VERSION ""

NS_ :

BS_:

BU_: VMCU TECU OBDScanT2 IC3 EMS ECUspare2 ECUspare1 DACU CIOM BBM
VAL_TABLE_ ViSig_Debug_PVT_SCIM_RD_DAI2Faul 3 "Input signals invalid" 2 "Open circuit " 1 "Short to GND" 0 "Nomal" ;
VAL_TABLE_ ViSig_Debug_PVT_SCIM_RD_DAI1Faul 3 "Input signals invalid" 2 "Open circuit " 1 "Short to GND " 0 "Nomal" ;
VAL_TABLE_ Debug_PVT_SCIM_RD_VBAT_Fault 8 "Invalid[Error Value]" 7 "Voltage Too High" 6 "Voltage Too Low" 5 "Voltage out of range" 4 "Reserved" 3 "Reserved" 2 "Reserved" 1 "Reserved" 0 "Nomal" ;
VAL_TABLE_ Debug_PVT_SCIM_RD_12VLivingFault 8 "Invalid[Error Value]" 7 "Reserved" 6 "Reserved" 5 "Voltage out of range" 4 "Reserved" 3 "Reserved" 2 "Reserved" 1 "Reserved" 0 "Nomal" ;
VAL_TABLE_ SetActive 1 "Deactivate" 0 "Activate" ;
VAL_TABLE_ FaultMonitoring 7 "Voltage Too High" 6 "Voltage Too Low" 3 "Open Circuit" 2 "Short To Battery" 1 "Short To Ground" ;

BO_ 3221225472 VECTOR__INDEPENDENT_SIG_MSG: 0 Vector__XXX
 SG_ Debug_6_CIOM : 0|64@1+ (1,0) [0|0] "" Vector__XXX
 SG_ Debug_5_CIOM : 0|64@1+ (1,0) [0|0] "" Vector__XXX
 SG_ Debug_4_CIOM : 0|64@1+ (1,0) [0|0] "" Vector__XXX
 SG_ Debug_3_CIOM : 0|64@1+ (1,0) [0|0] "" Vector__XXX
 SG_ Debug_2_CIOM : 0|64@1+ (1,0) [0|0] "" Vector__XXX

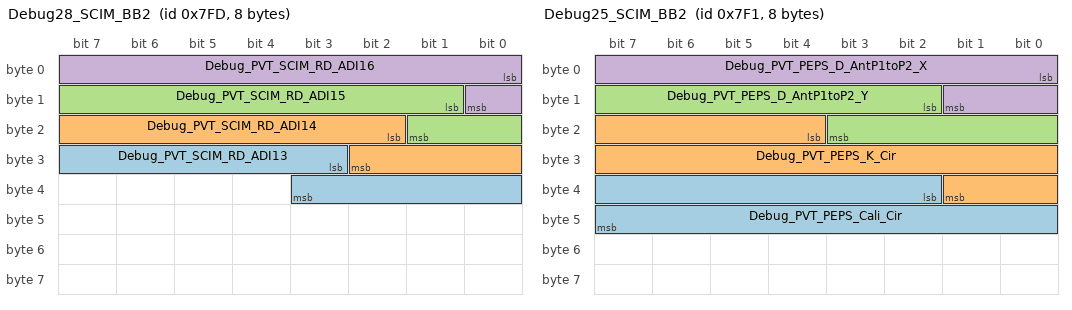
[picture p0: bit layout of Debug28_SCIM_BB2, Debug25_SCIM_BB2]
BO_ 2045 Debug28_SCIM_BB2: 8 CIOM
 SG_ Debug_PVT_SCIM_RD_ADI13 : 27|9@1+ (0.1,0) [0|51] "V" Vector__XXX
 SG_ Debug_PVT_SCIM_RD_ADI14 : 18|9@1+ (0.1,0) [0|51] "V" Vector__XXX
 SG_ Debug_PVT_SCIM_RD_ADI15 : 9|9@1+ (0.1,0) [0|51] "V" Vector__XXX
 SG_ Debug_PVT_SCIM_RD_ADI16 : 0|9@1+ (0.1,0) [0|51] "V" Vector__XXX

BO_ 2044 Debug27_SCIM_BB2: 8 CIOM
 SG_ Debug_PVT_SCIM_RD_DAI1Fault : 34|2@1+ (1,0) [0|3] ""  ECUspare1
 SG_ Debug_PVT_SCIM_RD_DAI2Fualt : 32|2@1+ (1,0) [0|3] ""  ECUspare1
 SG_ Debug_PVT_SCIM_RD_ADI16Fault : 30|2@1+ (1,0) [0|3] ""  ECUspare1
 SG_ Debug_PVT_SCIM_RD_ADI15Fault : 28|2@1+ (1,0) [0|3] ""  ECUspare1
 SG_ Debug_PVT_SCIM_RD_ADI14Fault : 26|2@1+ (1,0) [0|3] ""  ECUspare1
 SG_ Debug_PVT_SCIM_RD_ADI13Fault : 24|2@1+ (1,0) [0|3] ""  ECUspare1
 SG_ Debug_PVT_SCIM_RD_ADI12Fault : 22|2@1+ (1,0) [0|3] ""  ECUspare1
 SG_ Debug_PVT_SCIM_RD_ADI11Fault : 20|2@1+ (1,0) [0|3] ""  ECUspare1
 SG_ Debug_PVT_SCIM_RD_ADI10Fault : 18|2@1+ (1,0) [0|3] ""  ECUspare1
 SG_ Debug_PVT_SCIM_RD_ADI09Fault : 16|2@1+ (1,0) [0|3] ""  ECUspare1
 SG_ Debug_PVT_SCIM_RD_ADI08Fault : 14|2@1+ (1,0) [0|3] ""  ECUspare1
 SG_ Debug_PVT_SCIM_RD_ADI07Fault : 12|2@1+ (1,0) [0|3] ""  ECUspare1
 SG_ Debug_PVT_SCIM_RD_ADI06Fault : 10|2@1+ (1,0) [0|3] ""  ECUspare1
 SG_ Debug_PVT_SCIM_RD_ADI05Fault : 8|2@1+ (1,0) [0|3] ""  ECUspare1
 SG_ Debug_PVT_SCIM_RD_ADI04Fault : 6|2@1+ (1,0) [0|3] ""  ECUspare1
 SG_ Debug_PVT_SCIM_RD_ADI03Fault : 4|2@1+ (1,0) [0|3] ""  ECUspare1
 SG_ Debug_PVT_SCIM_RD_ADI02Fault : 2|2@1+ (1,0) [0|3] ""  ECUspare1
 SG_ Debug_PVT_SCIM_RD_ADI01Fault : 0|2@1+ (1,0) [0|3] ""  ECUspare1

BO_ 2034 Debug26_SCIM_BB2: 8 CIOM
 SG_ Debug_PVT_PEPS_AverRSSI2 : 24|8@1+ (1,0) [0|255] ""  ECUspare1
 SG_ Debug_PVT_PEPS_AverRSSI1 : 16|8@1+ (1,0) [0|255] ""  ECUspare1
 SG_ Debug_PVT_PEPS_DecRSSI : 0|16@1+ (1,0) [0|65535] ""  ECUspare1

BO_ 2033 Debug25_SCIM_BB2: 8 CIOM
 SG_ Debug_PVT_PEPS_Cali_Cir : 34|14@1- (1,0) [-8192|8191] ""  ECUspare1
 SG_ Debug_PVT_PEPS_K_Cir : 20|14@1- (1,0) [-8192|8191] ""  ECUspare1
 SG_ Debug_PVT_PEPS_D_AntP1toP2_Y : 10|10@1- (1,0) [-512|511] ""  ECUspare1
 SG_ Debug_PVT_PEPS_D_AntP1toP2_X : 0|10@1- (1,0) [-512|511] ""  ECUspare1

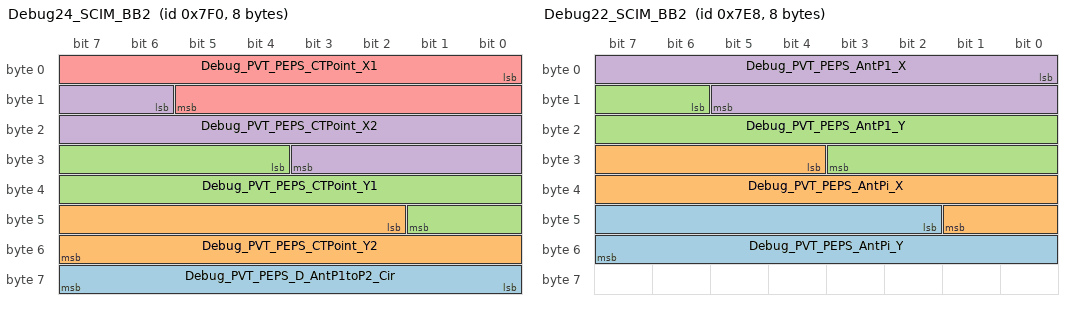
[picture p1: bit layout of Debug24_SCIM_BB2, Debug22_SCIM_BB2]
BO_ 2032 Debug24_SCIM_BB2: 8 CIOM
 SG_ Debug_PVT_PEPS_D_AntP1toP2_Cir : 56|8@1+ (1,0) [0|255] ""  ECUspare1
 SG_ Debug_PVT_PEPS_CTPoint_Y2 : 42|14@1- (1,0) [-8192|8191] ""  ECUspare1
 SG_ Debug_PVT_PEPS_CTPoint_Y1 : 28|14@1- (1,0) [-8192|8191] ""  ECUspare1
 SG_ Debug_PVT_PEPS_CTPoint_X2 : 14|14@1- (1,0) [-8192|8191] ""  ECUspare1
 SG_ Debug_PVT_PEPS_CTPoint_X1 : 0|14@1- (1,0) [-8192|8191] ""  ECUspare1

BO_ 2024 Debug22_SCIM_BB2: 8 CIOM
 SG_ Debug_PVT_PEPS_AntPi_Y : 42|14@1- (1,0) [-8192|8191] ""  ECUspare1
 SG_ Debug_PVT_PEPS_AntPi_X : 28|14@1- (1,0) [-8192|8191] ""  ECUspare1
 SG_ Debug_PVT_PEPS_AntP1_Y : 14|14@1- (1,0) [-8192|8191] ""  ECUspare1
 SG_ Debug_PVT_PEPS_AntP1_X : 0|14@1- (1,0) [-8192|8191] ""  ECUspare1

BO_ 2043 DebugCtrl11_SCIM_BB2: 8 Vector__XXX

BO_ 2042 DebugCtrl10_SCIM_BB2: 8 Vector__XXX

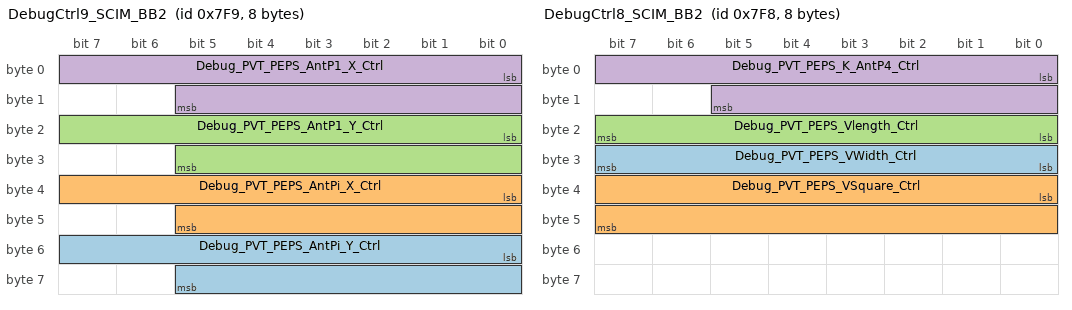
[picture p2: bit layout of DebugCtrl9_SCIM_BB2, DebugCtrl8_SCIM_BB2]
BO_ 2041 DebugCtrl9_SCIM_BB2: 8 ECUspare1
 SG_ Debug_PVT_PEPS_AntPi_Y_Ctrl : 48|14@1- (1,0) [-8192|8191] ""  CIOM
 SG_ Debug_PVT_PEPS_AntPi_X_Ctrl : 32|14@1- (1,0) [-8192|8191] ""  CIOM
 SG_ Debug_PVT_PEPS_AntP1_Y_Ctrl : 16|14@1- (1,0) [-8192|8191] ""  CIOM
 SG_ Debug_PVT_PEPS_AntP1_X_Ctrl : 0|14@1- (1,0) [-8192|8191] ""  CIOM

BO_ 2040 DebugCtrl8_SCIM_BB2: 8 ECUspare1
 SG_ Debug_PVT_PEPS_VWidth_Ctrl : 24|8@1+ (1,0) [0|255] ""  CIOM
 SG_ Debug_PVT_PEPS_VSquare_Ctrl : 32|16@1+ (1,0) [0|65535] ""  CIOM
 SG_ Debug_PVT_PEPS_Vlength_Ctrl : 16|8@1+ (1,0) [0|255] ""  CIOM
 SG_ Debug_PVT_PEPS_K_AntP4_Ctrl : 0|14@1- (1,0) [-8192|8191] ""  CIOM

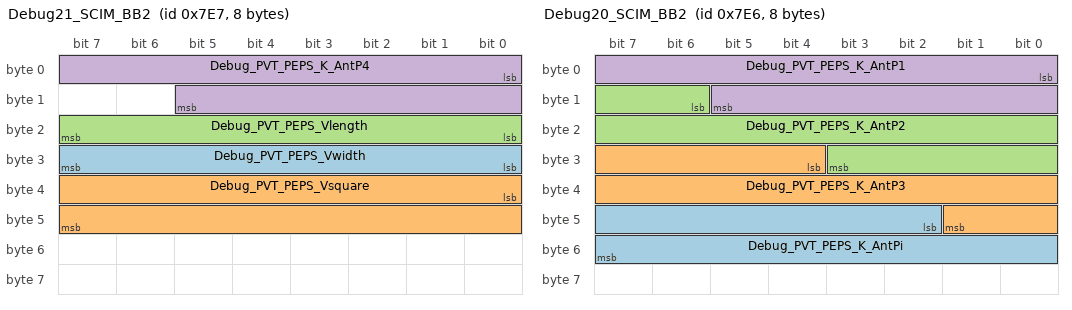
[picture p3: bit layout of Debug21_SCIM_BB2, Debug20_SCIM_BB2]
BO_ 2023 Debug21_SCIM_BB2: 8 CIOM
 SG_ Debug_PVT_PEPS_Vwidth : 24|8@1+ (1,0) [0|255] ""  ECUspare1
 SG_ Debug_PVT_PEPS_Vsquare : 32|16@1+ (1,0) [0|65535] ""  ECUspare1
 SG_ Debug_PVT_PEPS_Vlength : 16|8@1+ (1,0) [0|255] ""  ECUspare1
 SG_ Debug_PVT_PEPS_K_AntP4 : 0|14@1- (1,0) [-8192|8191] ""  ECUspare1

BO_ 2022 Debug20_SCIM_BB2: 8 CIOM
 SG_ Debug_PVT_PEPS_K_AntPi : 42|14@1- (1,0) [-8192|8191] ""  ECUspare1
 SG_ Debug_PVT_PEPS_K_AntP3 : 28|14@1- (1,0) [-8192|8191] ""  ECUspare1
 SG_ Debug_PVT_PEPS_K_AntP2 : 14|14@1- (1,0) [-8192|8191] ""  ECUspare1
 SG_ Debug_PVT_PEPS_K_AntP1 : 0|14@1- (1,0) [-8912|8911] ""  ECUspare1

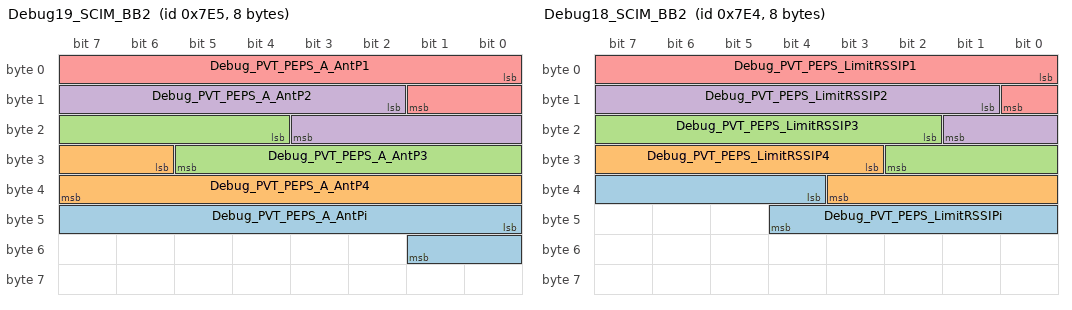
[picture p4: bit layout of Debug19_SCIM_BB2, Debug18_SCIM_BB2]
BO_ 2021 Debug19_SCIM_BB2: 8 CIOM
 SG_ Debug_PVT_PEPS_A_AntPi : 40|10@1- (1,0) [-512|511] ""  ECUspare1
 SG_ Debug_PVT_PEPS_A_AntP4 : 30|10@1- (1,0) [-512|511] ""  ECUspare1
 SG_ Debug_PVT_PEPS_A_AntP3 : 20|10@1- (1,0) [-512|511] ""  ECUspare1
 SG_ Debug_PVT_PEPS_A_AntP2 : 10|10@1- (1,0) [-512|511] ""  ECUspare1
 SG_ Debug_PVT_PEPS_A_AntP1 : 0|10@1- (1,0) [-512|511] ""  ECUspare1

BO_ 2020 Debug18_SCIM_BB2: 8 CIOM
 SG_ Debug_PVT_PEPS_LimitRSSIPi : 36|9@1+ (1,0) [0|511] ""  ECUspare1
 SG_ Debug_PVT_PEPS_LimitRSSIP4 : 27|9@1+ (1,0) [0|511] ""  ECUspare1
 SG_ Debug_PVT_PEPS_LimitRSSIP3 : 18|9@1+ (1,0) [0|511] ""  ECUspare1
 SG_ Debug_PVT_PEPS_LimitRSSIP2 : 9|9@1+ (1,0) [0|511] ""  ECUspare1
 SG_ Debug_PVT_PEPS_LimitRSSIP1 : 0|9@1+ (1,0) [0|511] ""  ECUspare1

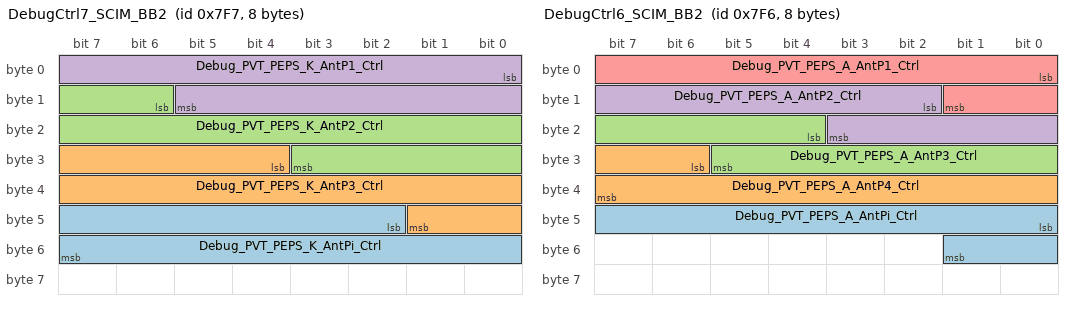
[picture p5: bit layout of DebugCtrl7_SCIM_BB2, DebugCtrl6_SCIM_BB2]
BO_ 2039 DebugCtrl7_SCIM_BB2: 8 ECUspare1
 SG_ Debug_PVT_PEPS_K_AntPi_Ctrl : 42|14@1- (1,0) [-8192|8191] ""  CIOM
 SG_ Debug_PVT_PEPS_K_AntP3_Ctrl : 28|14@1- (1,0) [-8192|8191] ""  CIOM
 SG_ Debug_PVT_PEPS_K_AntP2_Ctrl : 14|14@1- (1,0) [-8192|8191] ""  CIOM
 SG_ Debug_PVT_PEPS_K_AntP1_Ctrl : 0|14@1- (1,0) [-8192|8191] ""  CIOM

BO_ 2038 DebugCtrl6_SCIM_BB2: 8 ECUspare1
 SG_ Debug_PVT_PEPS_A_AntPi_Ctrl : 40|10@1- (1,0) [-512|511] ""  CIOM
 SG_ Debug_PVT_PEPS_A_AntP4_Ctrl : 30|10@1- (1,0) [-512|511] ""  CIOM
 SG_ Debug_PVT_PEPS_A_AntP3_Ctrl : 20|10@1- (1,0) [-512|511] ""  CIOM
 SG_ Debug_PVT_PEPS_A_AntP2_Ctrl : 10|10@1- (1,0) [-512|511] ""  CIOM
 SG_ Debug_PVT_PEPS_A_AntP1_Ctrl : 0|10@1- (1,0) [-512|511] ""  CIOM

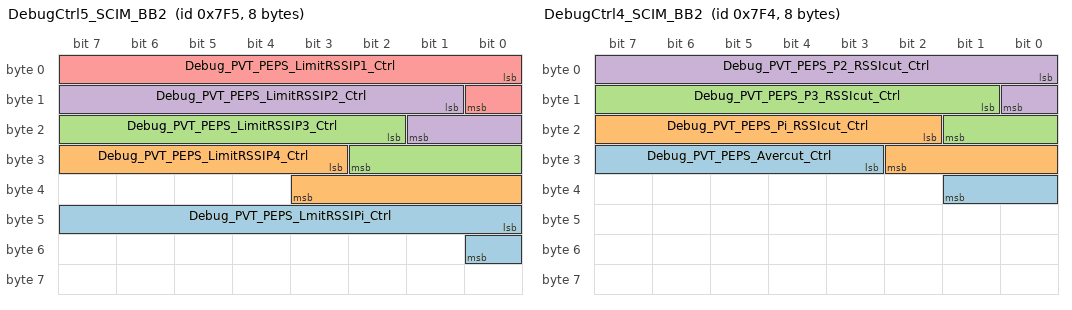
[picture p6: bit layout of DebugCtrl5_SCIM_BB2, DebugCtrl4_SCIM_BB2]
BO_ 2037 DebugCtrl5_SCIM_BB2: 8 ECUspare1
 SG_ Debug_PVT_PEPS_LmitRSSIPi_Ctrl : 40|9@1+ (1,0) [0|511] ""  CIOM
 SG_ Debug_PVT_PEPS_LimitRSSIP4_Ctrl : 27|9@1+ (1,0) [0|511] ""  CIOM
 SG_ Debug_PVT_PEPS_LimitRSSIP3_Ctrl : 18|9@1+ (1,0) [0|511] ""  CIOM
 SG_ Debug_PVT_PEPS_LimitRSSIP2_Ctrl : 9|9@1+ (1,0) [0|511] ""  CIOM
 SG_ Debug_PVT_PEPS_LimitRSSIP1_Ctrl : 0|9@1+ (1,0) [0|511] ""  CIOM

BO_ 2036 DebugCtrl4_SCIM_BB2: 8 ECUspare1
 SG_ Debug_PVT_PEPS_Avercut_Ctrl : 27|7@1+ (1,0) [0|127] ""  CIOM
 SG_ Debug_PVT_PEPS_Pi_RSSIcut_Ctrl : 18|9@1+ (1,0) [0|511] ""  CIOM
 SG_ Debug_PVT_PEPS_P3_RSSIcut_Ctrl : 9|9@1+ (1,0) [0|511] ""  CIOM
 SG_ Debug_PVT_PEPS_P2_RSSIcut_Ctrl : 0|9@1+ (1,0) [0|511] ""  CIOM

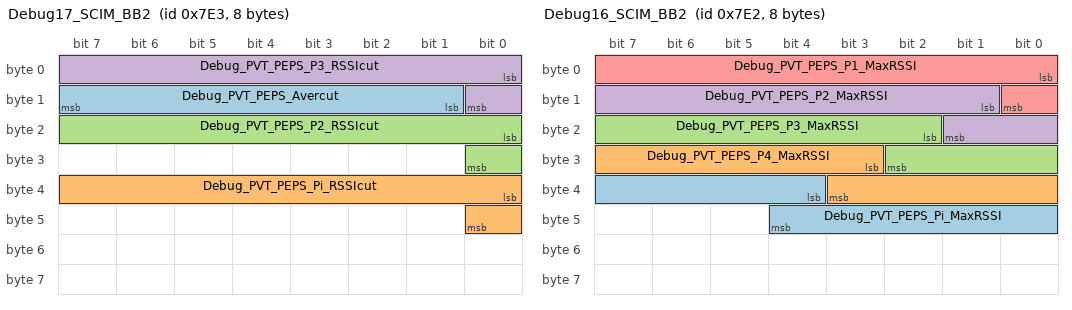
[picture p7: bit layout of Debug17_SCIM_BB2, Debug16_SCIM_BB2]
BO_ 2019 Debug17_SCIM_BB2: 8 CIOM
 SG_ Debug_PVT_PEPS_Avercut : 9|7@1+ (1,0) [0|127] ""  ECUspare1
 SG_ Debug_PVT_PEPS_Pi_RSSIcut : 32|9@1+ (1,0) [0|511] ""  ECUspare1
 SG_ Debug_PVT_PEPS_P2_RSSIcut : 16|9@1+ (1,0) [0|511] ""  ECUspare1
 SG_ Debug_PVT_PEPS_P3_RSSIcut : 0|9@1+ (1,0) [0|511] ""  ECUspare1

BO_ 2018 Debug16_SCIM_BB2: 8 CIOM
 SG_ Debug_PVT_PEPS_Pi_MaxRSSI : 36|9@1+ (1,0) [0|511] ""  ECUspare1
 SG_ Debug_PVT_PEPS_P4_MaxRSSI : 27|9@1+ (1,0) [0|511] ""  ECUspare1
 SG_ Debug_PVT_PEPS_P3_MaxRSSI : 18|9@1+ (1,0) [0|511] ""  ECUspare1
 SG_ Debug_PVT_PEPS_P2_MaxRSSI : 9|9@1+ (1,0) [0|511] ""  ECUspare1
 SG_ Debug_PVT_PEPS_P1_MaxRSSI : 0|9@1+ (1,0) [0|511] ""  ECUspare1

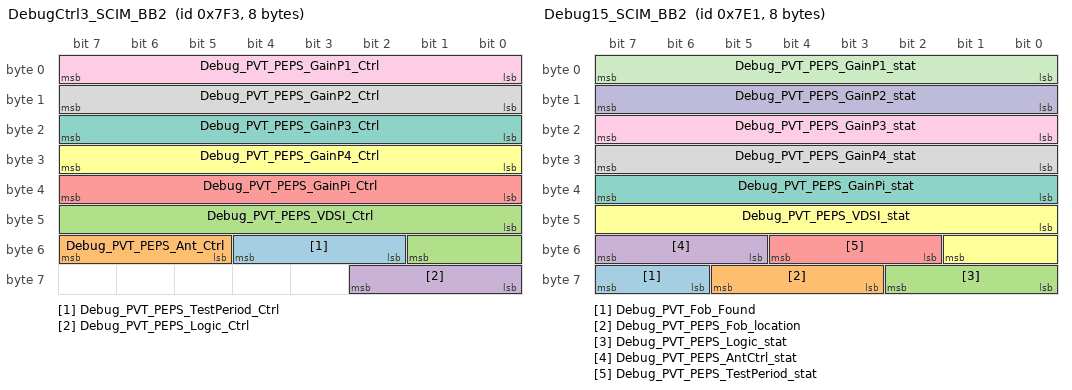
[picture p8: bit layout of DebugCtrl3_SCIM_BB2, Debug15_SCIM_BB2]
BO_ 2035 DebugCtrl3_SCIM_BB2: 8 ECUspare1
 SG_ Debug_PVT_PEPS_TestPeriod_Ctrl : 50|3@1+ (1,0) [0|7] ""  CIOM
 SG_ Debug_PVT_PEPS_Ant_Ctrl : 53|3@1+ (1,0) [0|7] ""  CIOM
 SG_ Debug_PVT_PEPS_VDSI_Ctrl : 40|10@1+ (1,0) [0|1023] ""  CIOM
 SG_ Debug_PVT_PEPS_Logic_Ctrl : 56|3@1+ (1,0) [0|8] ""  CIOM
 SG_ Debug_PVT_PEPS_GainPi_Ctrl : 32|8@1+ (1,0) [0|255] ""  CIOM
 SG_ Debug_PVT_PEPS_GainP4_Ctrl : 24|8@1+ (1,0) [0|255] ""  CIOM
 SG_ Debug_PVT_PEPS_GainP3_Ctrl : 16|8@1+ (1,0) [0|255] ""  CIOM
 SG_ Debug_PVT_PEPS_GainP2_Ctrl : 8|8@1+ (1,0) [0|255] ""  CIOM
 SG_ Debug_PVT_PEPS_GainP1_Ctrl : 0|8@1+ (1,0) [0|255] ""  CIOM

BO_ 2017 Debug15_SCIM_BB2: 8 CIOM
 SG_ Debug_PVT_Fob_Found : 62|2@1+ (1,0) [0|3] "" Vector__XXX
 SG_ Debug_PVT_PEPS_Fob_location : 59|3@1+ (1,0) [0|8] ""  ECUspare1
 SG_ Debug_PVT_PEPS_Logic_stat : 56|3@1+ (1,0) [0|8] ""  ECUspare1
 SG_ Debug_PVT_PEPS_AntCtrl_stat : 53|3@1+ (1,0) [0|7] ""  ECUspare1
 SG_ Debug_PVT_PEPS_TestPeriod_stat : 50|3@1+ (1,0) [0|7] ""  ECUspare1
 SG_ Debug_PVT_PEPS_VDSI_stat : 40|10@1+ (1,0) [0|1023] ""  ECUspare1
 SG_ Debug_PVT_PEPS_GainPi_stat : 32|8@1+ (1,0) [0|255] ""  ECUspare1
 SG_ Debug_PVT_PEPS_GainP4_stat : 24|8@1+ (1,0) [0|255] ""  ECUspare1
 SG_ Debug_PVT_PEPS_GainP3_stat : 16|8@1+ (1,0) [0|255] ""  ECUspare1
 SG_ Debug_PVT_PEPS_GainP2_stat : 8|8@1+ (1,0) [0|255] ""  ECUspare1
 SG_ Debug_PVT_PEPS_GainP1_stat : 0|8@1+ (1,0) [0|255] ""  ECUspare1

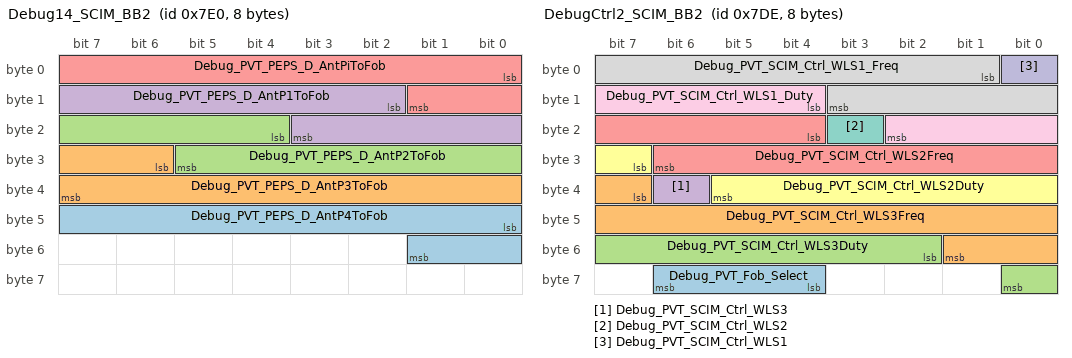
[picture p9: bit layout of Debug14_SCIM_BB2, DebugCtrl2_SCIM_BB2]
BO_ 2016 Debug14_SCIM_BB2: 8 CIOM
 SG_ Debug_PVT_PEPS_D_AntP4ToFob : 40|10@1+ (1,0) [0|1024] ""  ECUspare1
 SG_ Debug_PVT_PEPS_D_AntP3ToFob : 30|10@1+ (1,0) [0|1024] ""  ECUspare1
 SG_ Debug_PVT_PEPS_D_AntP2ToFob : 20|10@1+ (1,0) [0|1024] ""  ECUspare1
 SG_ Debug_PVT_PEPS_D_AntP1ToFob : 10|10@1+ (1,0) [0|1024] ""  ECUspare1
 SG_ Debug_PVT_PEPS_D_AntPiToFob : 0|10@1+ (1,0) [0|1024] ""  ECUspare1

BO_ 2015 Debug13_SCIM_BB2: 8 CIOM
 SG_ Debug_PVT_Fob_RF_RollingCounter : 32|32@1+ (1,0) [0|0] ""  ECUspare1
 SG_ Debug_PVT_SCIM_RF_RollingCounter : 0|32@1+ (1,0) [0|4294967295] ""  ECUspare1

BO_ 2014 DebugCtrl2_SCIM_BB2: 8 ECUspare1
 SG_ Debug_PVT_Fob_Select : 60|3@1+ (1,0) [0|8] ""  CIOM
 SG_ Debug_PVT_SCIM_Ctrl_WLS3Freq : 39|11@1+ (1,0) [0|2047] "Hz"  CIOM
 SG_ Debug_PVT_SCIM_Ctrl_WLS3Duty : 50|7@1+ (1,0) [0|100] "%"  CIOM
 SG_ Debug_PVT_SCIM_Ctrl_WLS3 : 38|1@1+ (1,0) [0|1] ""  CIOM
 SG_ Debug_PVT_SCIM_Ctrl_WLS2Freq : 20|11@1+ (1,0) [0|2047] "Hz"  CIOM
 SG_ Debug_PVT_SCIM_Ctrl_WLS2Duty : 31|7@1+ (1,0) [0|100] "%"  CIOM
 SG_ Debug_PVT_SCIM_Ctrl_WLS2 : 19|1@1+ (1,0) [0|1] ""  CIOM
 SG_ Debug_PVT_SCIM_Ctrl_WLS1_Freq : 1|11@1+ (1,0) [0|2047] "Hz"  CIOM
 SG_ Debug_PVT_SCIM_Ctrl_WLS1_Duty : 12|7@1+ (1,0) [0|100] "%"  CIOM
 SG_ Debug_PVT_SCIM_Ctrl_WLS1 : 0|1@1+ (1,0) [0|1] ""  CIOM

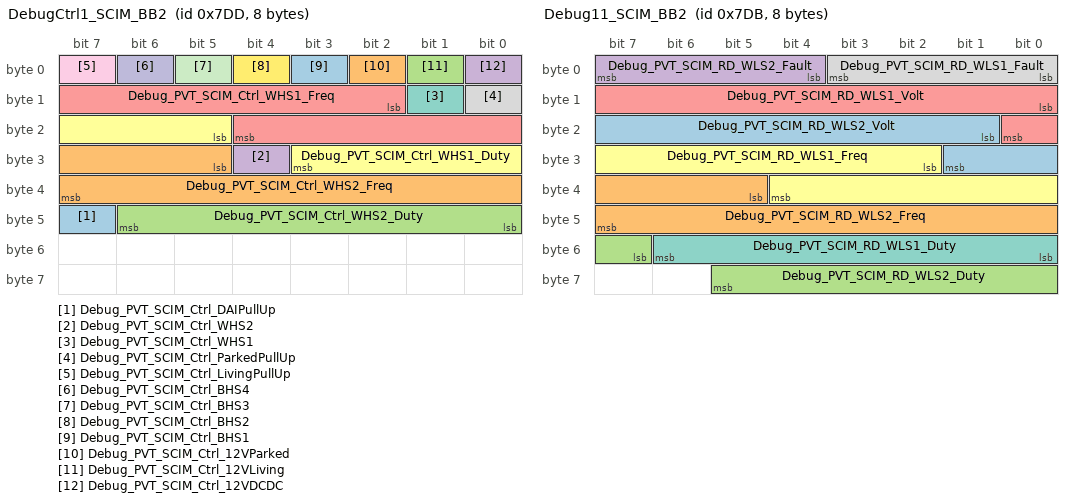
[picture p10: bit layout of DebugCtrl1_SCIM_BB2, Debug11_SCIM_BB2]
BO_ 2013 DebugCtrl1_SCIM_BB2: 8 ECUspare1
 SG_ Debug_PVT_SCIM_Ctrl_DAIPullUp : 47|1@1+ (1,0) [0|1] ""  CIOM
 SG_ Debug_PVT_SCIM_Ctrl_WHS2_Freq : 29|11@1+ (1,0) [0|2047] "Hz"  CIOM
 SG_ Debug_PVT_SCIM_Ctrl_WHS2_Duty : 40|7@1+ (1,0) [0|100] "%"  CIOM
 SG_ Debug_PVT_SCIM_Ctrl_WHS2 : 28|1@1+ (1,0) [0|1] ""  CIOM
 SG_ Debug_PVT_SCIM_Ctrl_WHS1_Freq : 10|11@1+ (1,0) [0|2047] "Hz"  CIOM
 SG_ Debug_PVT_SCIM_Ctrl_WHS1_Duty : 21|7@1+ (1,0) [0|100] "%"  CIOM
 SG_ Debug_PVT_SCIM_Ctrl_WHS1 : 9|1@1+ (1,0) [0|1] ""  CIOM
 SG_ Debug_PVT_SCIM_Ctrl_ParkedPullUp : 8|1@1+ (1,0) [0|1] ""  CIOM
 SG_ Debug_PVT_SCIM_Ctrl_LivingPullUp : 7|1@1+ (1,0) [0|1] ""  CIOM
 SG_ Debug_PVT_SCIM_Ctrl_BHS4 : 6|1@1+ (1,0) [0|1] ""  CIOM
 SG_ Debug_PVT_SCIM_Ctrl_BHS3 : 5|1@1+ (1,0) [0|1] ""  CIOM
 SG_ Debug_PVT_SCIM_Ctrl_BHS2 : 4|1@1+ (1,0) [0|1] ""  CIOM
 SG_ Debug_PVT_SCIM_Ctrl_BHS1 : 3|1@1+ (1,0) [0|1] ""  CIOM
 SG_ Debug_PVT_SCIM_Ctrl_12VParked : 2|1@1+ (1,0) [0|1] ""  CIOM
 SG_ Debug_PVT_SCIM_Ctrl_12VLiving : 1|1@1+ (1,0) [0|1] ""  CIOM
 SG_ Debug_PVT_SCIM_Ctrl_12VDCDC : 0|1@1+ (1,0) [0|1] ""  CIOM

BO_ 2012 Debug12_SCIM_BB2: 8 CIOM
 SG_ Debug_PVT_Fob_ID : 40|3@1+ (1,0) [0|8] ""  ECUspare1
 SG_ Debug_PVT_SCIM_RF_KeyfobSerialNb : 0|24@1+ (1,0) [0|16777216] ""  ECUspare1

BO_ 2011 Debug11_SCIM_BB2: 8 CIOM
 SG_ Debug_PVT_SCIM_RD_WLS2_Volt : 17|9@1+ (0.1,0) [0|51] "V"  ECUspare1
 SG_ Debug_PVT_SCIM_RD_WLS2_Freq : 37|11@1+ (1,0) [0|2047] "Hz"  ECUspare1
 SG_ Debug_PVT_SCIM_RD_WLS2_Duty : 55|7@1+ (1,0) [0|100] "%"  ECUspare1
 SG_ Debug_PVT_SCIM_RD_WLS2_Fault : 4|4@1+ (1,0) [0|15] "0"  ECUspare1
 SG_ Debug_PVT_SCIM_RD_WLS1_Volt : 8|9@1+ (0.1,0) [0|51] "V"  ECUspare1
 SG_ Debug_PVT_SCIM_RD_WLS1_Freq : 26|11@1+ (1,0) [0|2047] "Hz"  ECUspare1
 SG_ Debug_PVT_SCIM_RD_WLS1_Duty : 48|7@1+ (1,0) [0|100] "%"  ECUspare1
 SG_ Debug_PVT_SCIM_RD_WLS1_Fault : 0|4@1+ (1,0) [0|15] "0"  ECUspare1

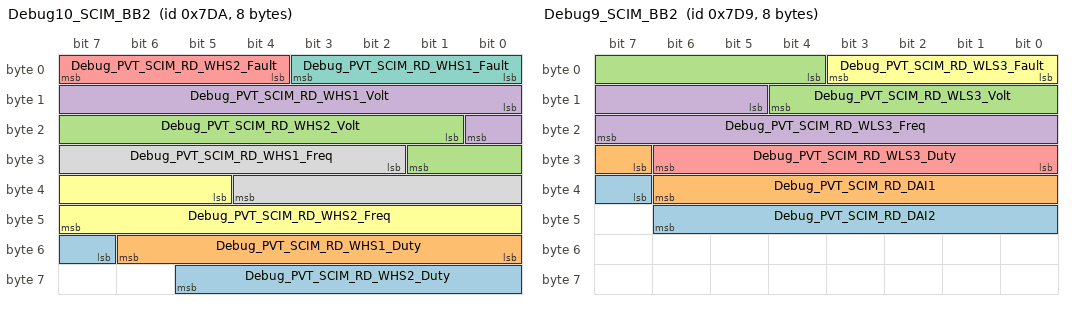
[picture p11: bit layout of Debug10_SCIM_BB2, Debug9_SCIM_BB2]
BO_ 2010 Debug10_SCIM_BB2: 8 CIOM
 SG_ Debug_PVT_SCIM_RD_WHS2_Duty : 55|7@1+ (1,0) [0|100] "%"  ECUspare1
 SG_ Debug_PVT_SCIM_RD_WHS1_Duty : 48|7@1+ (1,0) [0|100] "%"  ECUspare1
 SG_ Debug_PVT_SCIM_RD_WHS2_Volt : 17|9@1+ (0.1,0) [0|51] "V"  ECUspare1
 SG_ Debug_PVT_SCIM_RD_WHS1_Volt : 8|9@1+ (0.1,0) [0|51] "V"  ECUspare1
 SG_ Debug_PVT_SCIM_RD_WHS2_Fault : 4|4@1+ (1,0) [0|15] "0"  ECUspare1
 SG_ Debug_PVT_SCIM_RD_WHS2_Freq : 37|11@1+ (1,0) [0|2047] "Hz"  ECUspare1
 SG_ Debug_PVT_SCIM_RD_WHS1_Fault : 0|4@1+ (1,0) [0|15] "0"  ECUspare1
 SG_ Debug_PVT_SCIM_RD_WHS1_Freq : 26|11@1+ (1,0) [0|2047] "Hz"  ECUspare1

BO_ 2009 Debug9_SCIM_BB2: 8 CIOM
 SG_ Debug_PVT_SCIM_RD_DAI2 : 39|8@1+ (0.2,0) [0|51] "V"  ECUspare1
 SG_ Debug_PVT_SCIM_RD_DAI1 : 31|8@1+ (0.2,0) [0|51] "V"  ECUspare1
 SG_ Debug_PVT_SCIM_RD_WLS3_Volt : 4|9@1+ (0.1,0) [0|51] "V"  ECUspare1
 SG_ Debug_PVT_SCIM_RD_WLS3_Freq : 13|11@1+ (1,0) [0|2047] "Hz"  ECUspare1
 SG_ Debug_PVT_SCIM_RD_WLS3_Duty : 24|7@1+ (1,0) [0|100] "%"  ECUspare1
 SG_ Debug_PVT_SCIM_RD_WLS3_Fault : 0|4@1+ (1,0) [0|15] "0"  ECUspare1

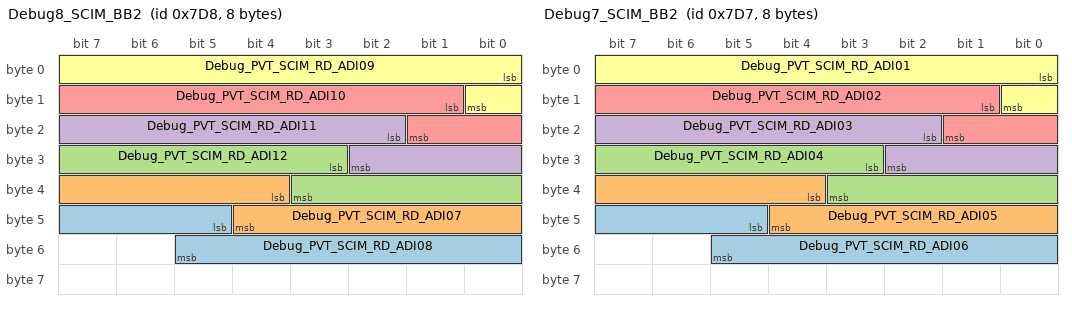
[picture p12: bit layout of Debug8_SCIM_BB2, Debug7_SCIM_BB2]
BO_ 2008 Debug8_SCIM_BB2: 8 CIOM
 SG_ Debug_PVT_SCIM_RD_ADI08 : 45|9@1+ (0.1,0) [0|51] "V" Vector__XXX
 SG_ Debug_PVT_SCIM_RD_ADI07 : 36|9@1+ (0.1,0) [0|51] "V" Vector__XXX
 SG_ Debug_PVT_SCIM_RD_ADI12 : 27|9@1+ (0.1,0) [0|51] "V"  ECUspare1
 SG_ Debug_PVT_SCIM_RD_ADI11 : 18|9@1+ (0.1,0) [0|51] "V"  ECUspare1
 SG_ Debug_PVT_SCIM_RD_ADI10 : 9|9@1+ (0.1,0) [0|51] "V"  ECUspare1
 SG_ Debug_PVT_SCIM_RD_ADI09 : 0|9@1+ (0.1,0) [0|51] "V"  ECUspare1

BO_ 2007 Debug7_SCIM_BB2: 8 CIOM
 SG_ Debug_PVT_SCIM_RD_ADI06 : 45|9@1+ (0.1,0) [0|51] "V"  ECUspare1
 SG_ Debug_PVT_SCIM_RD_ADI05 : 36|9@1+ (0.1,0) [0|51] "V"  ECUspare1
 SG_ Debug_PVT_SCIM_RD_ADI04 : 27|9@1+ (0.1,0) [0|51] "V"  ECUspare1
 SG_ Debug_PVT_SCIM_RD_ADI03 : 18|9@1+ (0.1,0) [0|51] "V"  ECUspare1
 SG_ Debug_PVT_SCIM_RD_ADI02 : 9|9@1+ (0.1,0) [0|51] "V"  ECUspare1
 SG_ Debug_PVT_SCIM_RD_ADI01 : 0|9@1+ (0.1,0) [0|51] "V"  ECUspare1

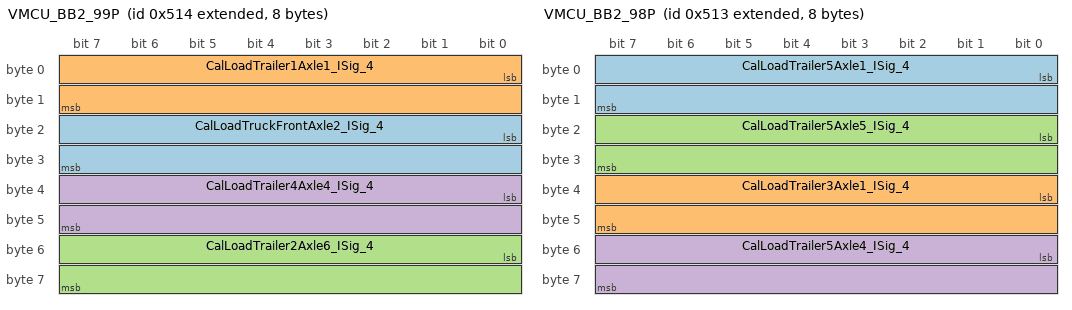
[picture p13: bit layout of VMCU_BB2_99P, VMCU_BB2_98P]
BO_ 2147484948 VMCU_BB2_99P: 8 VMCU
 SG_ CalLoadTruckFrontAxle2_ISig_4 : 16|16@1+ (0.5,0) [0|32767.5] "kg"  IC3,CIOM,BBM
 SG_ CalLoadTrailer1Axle1_ISig_4 : 0|16@1+ (0.5,0) [0|32767.5] "kg"  CIOM,BBM,IC3
 SG_ CalLoadTrailer2Axle6_ISig_4 : 48|16@1+ (0.5,0) [0|32767.5] "kg"  IC3,CIOM
 SG_ CalLoadTrailer4Axle4_ISig_4 : 32|16@1+ (0.5,0) [0|32767.5] "kg"  CIOM,IC3

BO_ 2147484947 VMCU_BB2_98P: 8 VMCU
 SG_ CalLoadTrailer5Axle1_ISig_4 : 0|16@1+ (0.5,0) [0|32767.5] "kg"  IC3,CIOM
 SG_ CalLoadTrailer3Axle1_ISig_4 : 32|16@1+ (0.5,0) [0|32767.5] "kg"  CIOM,IC3
 SG_ CalLoadTrailer5Axle5_ISig_4 : 16|16@1+ (0.5,0) [0|32767.5] "kg"  CIOM,IC3
 SG_ CalLoadTrailer5Axle4_ISig_4 : 48|16@1+ (0.5,0) [0|32767.5] "kg"  IC3,CIOM

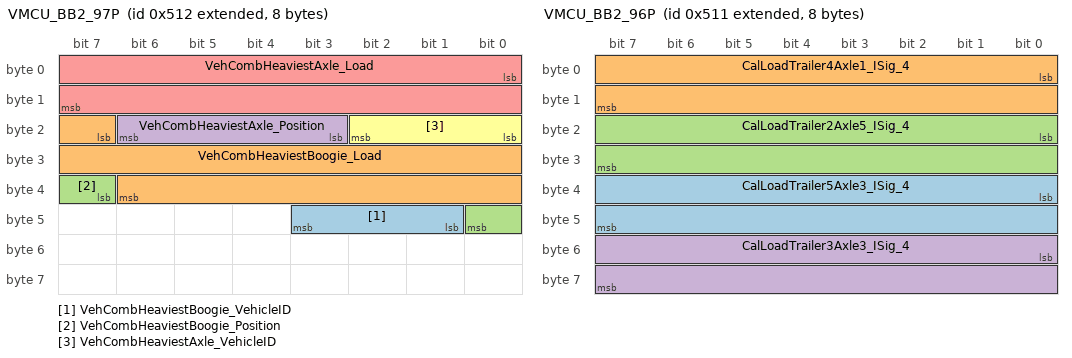
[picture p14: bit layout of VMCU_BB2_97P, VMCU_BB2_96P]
BO_ 2147484946 VMCU_BB2_97P: 8 VMCU
 SG_ VehCombHeaviestBoogie_VehicleID : 41|3@1+ (1,0) [0|0] ""  IC3
 SG_ VehCombHeaviestBoogie_Load : 23|16@1+ (0.5,0) [0|32767.5] "kg"  IC3
 SG_ VehCombHeaviestBoogie_Position : 39|2@1+ (1,0) [0|0] ""  IC3
 SG_ VehCombHeaviestAxle_Position : 19|4@1+ (1,0) [0|0] ""  IC3
 SG_ VehCombHeaviestAxle_Load : 0|16@1+ (0.5,0) [0|32767.5] "kg"  IC3
 SG_ VehCombHeaviestAxle_VehicleID : 16|3@1+ (1,0) [0|0] ""  IC3

BO_ 2147484945 VMCU_BB2_96P: 8 VMCU
 SG_ CalLoadTrailer5Axle3_ISig_4 : 32|16@1+ (0.5,0) [0|32767.5] "kg"  CIOM,IC3
 SG_ CalLoadTrailer4Axle1_ISig_4 : 0|16@1+ (0.5,0) [0|32767.5] "kg"  CIOM,IC3
 SG_ CalLoadTrailer2Axle5_ISig_4 : 16|16@1+ (0.5,0) [0|32767.5] "kg"  CIOM,IC3
 SG_ CalLoadTrailer3Axle3_ISig_4 : 48|16@1+ (0.5,0) [0|32767.5] "kg"  CIOM,IC3

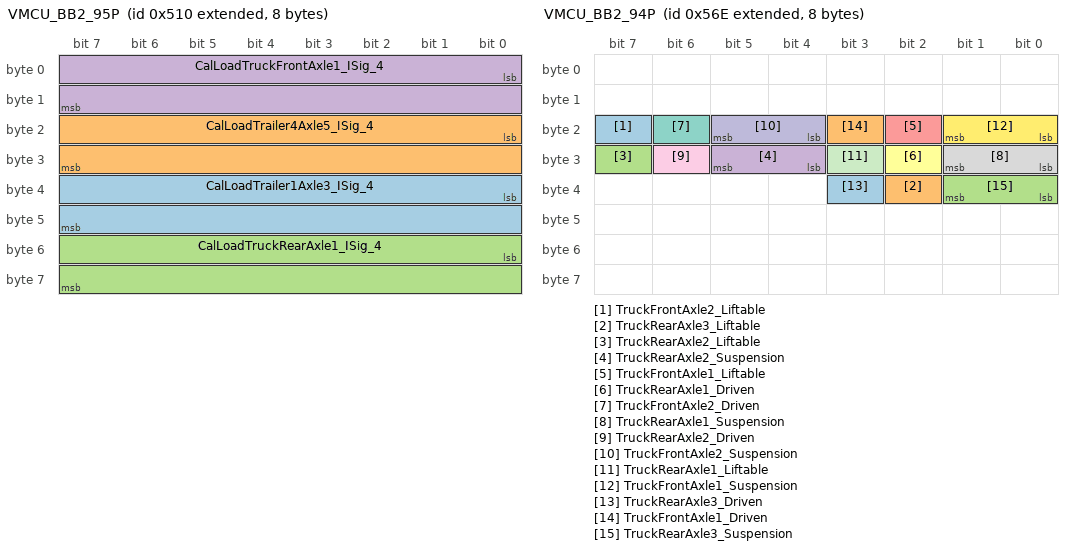
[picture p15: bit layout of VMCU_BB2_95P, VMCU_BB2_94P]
BO_ 2147484944 VMCU_BB2_95P: 8 VMCU
 SG_ CalLoadTrailer1Axle3_ISig_4 : 32|16@1+ (0.5,0) [0|32767.5] "kg"  IC3,BBM,CIOM
 SG_ CalLoadTrailer4Axle5_ISig_4 : 16|16@1+ (0.5,0) [0|32767.5] "kg"  IC3,CIOM
 SG_ CalLoadTruckRearAxle1_ISig_4 : 48|16@1+ (0.5,0) [0|32767.5] "kg"  CIOM,BBM,IC3
 SG_ CalLoadTruckFrontAxle1_ISig_4 : 0|16@1+ (0.5,0) [0|32767.5] "kg"  IC3,BBM,CIOM

BO_ 2147485038 VMCU_BB2_94P: 8 VMCU
 SG_ TruckFrontAxle2_Liftable : 23|1@1+ (1,0) [0|0] ""  IC3
 SG_ TruckRearAxle3_Liftable : 34|1@1+ (1,0) [0|0] ""  IC3
 SG_ TruckRearAxle2_Liftable : 31|1@1+ (1,0) [0|0] ""  IC3
 SG_ TruckRearAxle2_Suspension : 28|2@1+ (1,0) [0|0] ""  IC3
 SG_ TruckFrontAxle1_Liftable : 18|1@1+ (1,0) [0|0] ""  IC3
 SG_ TruckRearAxle1_Driven : 26|1@1+ (1,0) [0|0] ""  IC3
 SG_ TruckFrontAxle2_Driven : 22|1@1+ (1,0) [0|0] ""  IC3
 SG_ TruckRearAxle1_Suspension : 24|2@1+ (1,0) [0|0] ""  IC3
 SG_ TruckRearAxle2_Driven : 30|1@1+ (1,0) [0|0] ""  IC3
 SG_ TruckFrontAxle2_Suspension : 20|2@1+ (1,0) [0|0] ""  IC3
 SG_ TruckRearAxle1_Liftable : 27|1@1+ (1,0) [0|0] ""  IC3
 SG_ TruckFrontAxle1_Suspension : 16|2@1+ (1,0) [0|0] ""  IC3
 SG_ TruckRearAxle3_Driven : 35|1@1+ (1,0) [0|0] ""  IC3
 SG_ TruckFrontAxle1_Driven : 19|1@1+ (1,0) [0|0] ""  IC3
 SG_ TruckRearAxle3_Suspension : 32|2@1+ (1,0) [0|0] ""  IC3

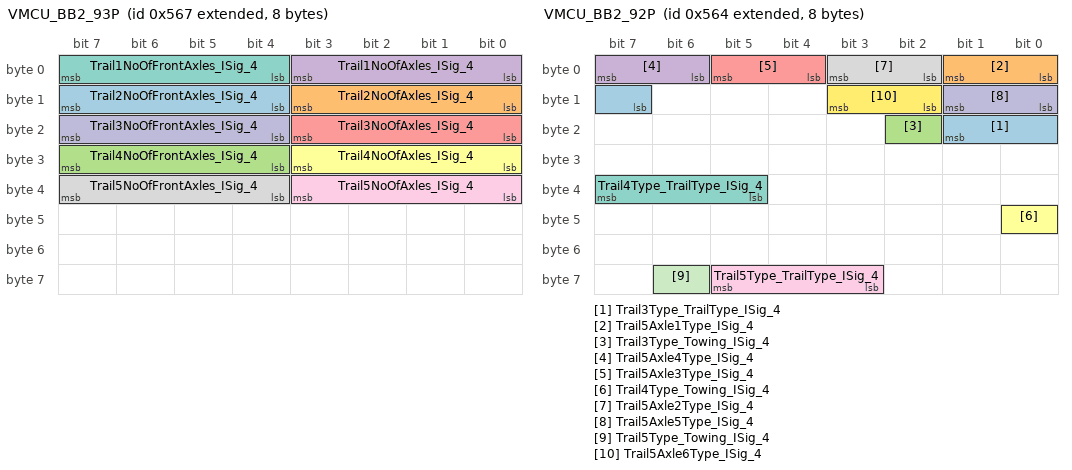
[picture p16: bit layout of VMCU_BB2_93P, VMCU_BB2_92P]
BO_ 2147485031 VMCU_BB2_93P: 8 VMCU
 SG_ Trail2NoOfFrontAxles_ISig_4 : 12|4@1+ (1,0) [0|15] "NotApplicable"  CIOM,IC3
 SG_ Trail2NoOfAxles_ISig_4 : 8|4@1+ (1,0) [0|15] "NotApplicable"  IC3,CIOM
 SG_ Trail4NoOfFrontAxles_ISig_4 : 28|4@1+ (1,0) [0|15] "NotApplicable"  CIOM,IC3
 SG_ Trail1NoOfAxles_ISig_4 : 0|4@1+ (1,0) [0|15] "NotApplicable"  CIOM,IC3
 SG_ Trail3NoOfAxles_ISig_4 : 16|4@1+ (1,0) [0|15] "NotApplicable"  IC3,CIOM
 SG_ Trail4NoOfAxles_ISig_4 : 24|4@1+ (1,0) [0|15] "NotApplicable"  IC3,CIOM
 SG_ Trail1NoOfFrontAxles_ISig_4 : 4|4@1+ (1,0) [0|15] "NotApplicable"  IC3,CIOM
 SG_ Trail5NoOfFrontAxles_ISig_4 : 36|4@1+ (1,0) [0|15] "NotApplicable"  CIOM,IC3
 SG_ Trail5NoOfAxles_ISig_4 : 32|4@1+ (1,0) [0|15] "NotApplicable"  CIOM,IC3
 SG_ Trail3NoOfFrontAxles_ISig_4 : 20|4@1+ (1,0) [0|15] "NotApplicable"  CIOM,IC3

BO_ 2147485028 VMCU_BB2_92P: 8 VMCU
 SG_ Trail3Type_TrailType_ISig_4 : 15|3@1+ (1,0) [0|0] ""  CIOM,IC3
 SG_ Trail5Axle1Type_ISig_4 : 0|2@1+ (1,0) [0|0] ""  CIOM,IC3
 SG_ Trail3Type_Towing_ISig_4 : 18|1@1+ (1,0) [0|0] ""  CIOM,IC3
 SG_ Trail5Axle4Type_ISig_4 : 6|2@1+ (1,0) [0|0] ""  CIOM,IC3
 SG_ Trail5Axle3Type_ISig_4 : 4|2@1+ (1,0) [0|0] ""  CIOM,IC3
 SG_ Trail4Type_Towing_ISig_4 : 40|1@1+ (1,0) [0|0] ""  CIOM,IC3
 SG_ Trail4Type_TrailType_ISig_4 : 37|3@1+ (1,0) [0|0] ""  CIOM,IC3
 SG_ Trail5Axle2Type_ISig_4 : 2|2@1+ (1,0) [0|0] ""  CIOM,IC3
 SG_ Trail5Type_TrailType_ISig_4 : 59|3@1+ (1,0) [0|0] ""  IC3,CIOM
 SG_ Trail5Axle5Type_ISig_4 : 8|2@1+ (1,0) [0|0] ""  CIOM,IC3
 SG_ Trail5Type_Towing_ISig_4 : 62|1@1+ (1,0) [0|0] ""  IC3,CIOM
 SG_ Trail5Axle6Type_ISig_4 : 10|2@1+ (1,0) [0|0] ""  IC3,CIOM

BO_ 2147485026 VMCU_BB2_91P: 8 VMCU
 SG_ Trail2Axle4Type_ISig_4 : 22|2@1+ (1,0) [0|0] ""  CIOM,IC3
 SG_ Trail4Axle1Type_ISig_4 : 44|2@1+ (1,0) [0|0] ""  CIOM,IC3
 SG_ Trail2Axle3Type_ISig_4 : 16|2@1+ (1,0) [0|0] ""  IC3,CIOM
 SG_ Trail1Axle6Type_ISig_4 : 10|2@1+ (1,0) [0|0] ""  IC3,CIOM
 SG_ Trail1Type_Towing_ISig_4 : 21|1@1+ (1,0) [0|0] ""  CIOM,IC3
 SG_ Trail3Axle5Type_ISig_4 : 36|2@1+ (1,0) [0|0] ""  IC3,CIOM
 SG_ Trail1Axle5Type_ISig_4 : 8|2@1+ (1,0) [0|0] ""  IC3,CIOM
 SG_ Trail3Axle4Type_ISig_4 : 34|2@1+ (1,0) [0|0] ""  CIOM,IC3
 SG_ Trail4Axle4Type_ISig_4 : 50|2@1+ (1,0) [0|0] ""  CIOM,IC3
 SG_ Trail4Axle3Type_ISig_4 : 48|2@1+ (1,0) [0|0] ""  IC3,CIOM
 SG_ Trail4Axle2Type_ISig_4 : 46|2@1+ (1,0) [0|0] ""  CIOM,IC3
 SG_ Trail1Axle4Type_ISig_4 : 6|2@1+ (1,0) [0|0] ""  CIOM,IC3
 SG_ Trail1Axle1Type_ISig_4 : 0|2@1+ (1,0) [0|0] ""  IC3,CIOM
 SG_ Trail1Type_TrailType_ISig_4 : 18|3@1+ (1,0) [0|0] ""  CIOM,IC3
 SG_ Trail2Type_Towing_ISig_4 : 43|1@1+ (1,0) [0|0] ""  CIOM,IC3
 SG_ Trail2Axle1Type_ISig_4 : 12|2@1+ (1,0) [0|0] ""  CIOM,IC3
 SG_ Trail3Axle3Type_ISig_4 : 32|2@1+ (1,0) [0|0] ""  CIOM,IC3
 SG_ Trail3Axle1Type_ISig_4 : 28|2@1+ (1,0) [0|0] ""  IC3,CIOM
 SG_ Trail4Axle5Type_ISig_4 : 52|2@1+ (1,0) [0|0] ""  CIOM,IC3
 SG_ Trail1Axle3Type_ISig_4 : 4|2@1+ (1,0) [0|0] ""  IC3,CIOM
 SG_ Trail2Type_TrailType_ISig_4 : 40|3@1+ (1,0) [0|0] ""  CIOM,IC3
 SG_ Trail3Axle2Type_ISig_4 : 30|2@1+ (1,0) [0|0] ""  IC3,CIOM
 SG_ Trail4Axle6Type_ISig_4 : 54|2@1+ (1,0) [0|0] ""  IC3,CIOM
 SG_ Trail2Axle5Type_ISig_4 : 24|2@1+ (1,0) [0|0] ""  IC3,CIOM
 SG_ Trail2Axle6Type_ISig_4 : 26|2@1+ (1,0) [0|0] ""  CIOM,IC3
 SG_ Trail3Axle6Type_ISig_4 : 38|2@1+ (1,0) [0|0] ""  IC3,CIOM
 SG_ Trail1Axle2Type_ISig_4 : 2|2@1+ (1,0) [0|0] ""  IC3,CIOM
 SG_ Trail2Axle2Type_ISig_4 : 14|2@1+ (1,0) [0|0] ""  CIOM,IC3

BO_ 2147484291 VMCU_BB2_90P: 8 VMCU
 SG_ RelCargoLoadTrailer1_ISig_4 : 0|16@1+ (4,-128508) [-128508|133632] "kg"  IC3,CIOM
 SG_ RelCargoLoadTrailer5_ISig_4 : 16|16@1+ (4,-128508) [-128508|133632] "kg"  IC3,CIOM

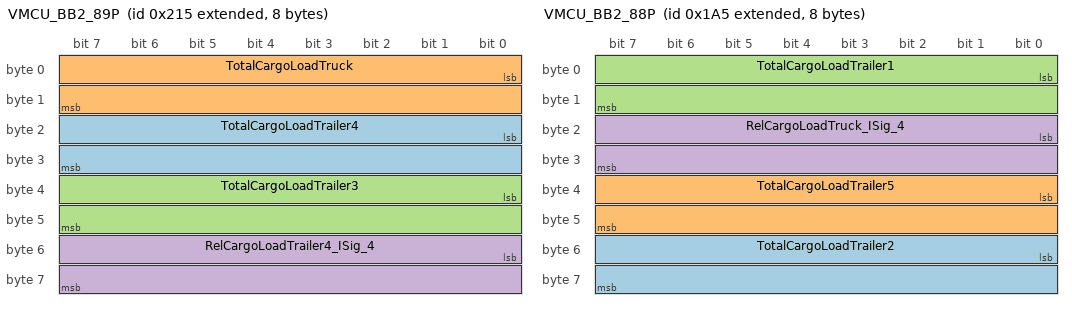
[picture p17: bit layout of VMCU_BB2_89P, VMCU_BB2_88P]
BO_ 2147484181 VMCU_BB2_89P: 8 VMCU
 SG_ TotalCargoLoadTrailer4 : 16|16@1+ (2,0) [0|131070] "kg"  BBM
 SG_ TotalCargoLoadTruck : 0|16@1+ (2,0) [0|131070] "kg"  BBM
 SG_ TotalCargoLoadTrailer3 : 32|16@1+ (2,0) [0|131070] "kg"  BBM
 SG_ RelCargoLoadTrailer4_ISig_4 : 48|16@1+ (4,-128508) [-128508|133632] "kg"  IC3,CIOM

BO_ 2147484069 VMCU_BB2_88P: 8 VMCU
 SG_ TotalCargoLoadTrailer2 : 48|16@1+ (2,0) [0|131070] "kg"  BBM
 SG_ TotalCargoLoadTrailer5 : 32|16@1+ (2,0) [0|131070] "kg"  BBM
 SG_ TotalCargoLoadTrailer1 : 0|16@1+ (2,0) [0|131070] "kg"  BBM
 SG_ RelCargoLoadTruck_ISig_4 : 16|16@1+ (4,-128508) [-128508|133632] "kg"  CIOM,IC3

BO_ 2147483971 VMCU_BB2_87P: 8 VMCU
 SG_ LoadTrailer5_ISig_4 : 32|16@1+ (2,0) [0|131070] "kg"  IC3,CIOM,BBM
 SG_ LoadTrailer4Back : 16|16@1+ (2,0) [0|131070] "kg"  IC3
 SG_ LoadTrailer2Front : 0|16@1+ (2,0) [0|131070] "kg"  IC3

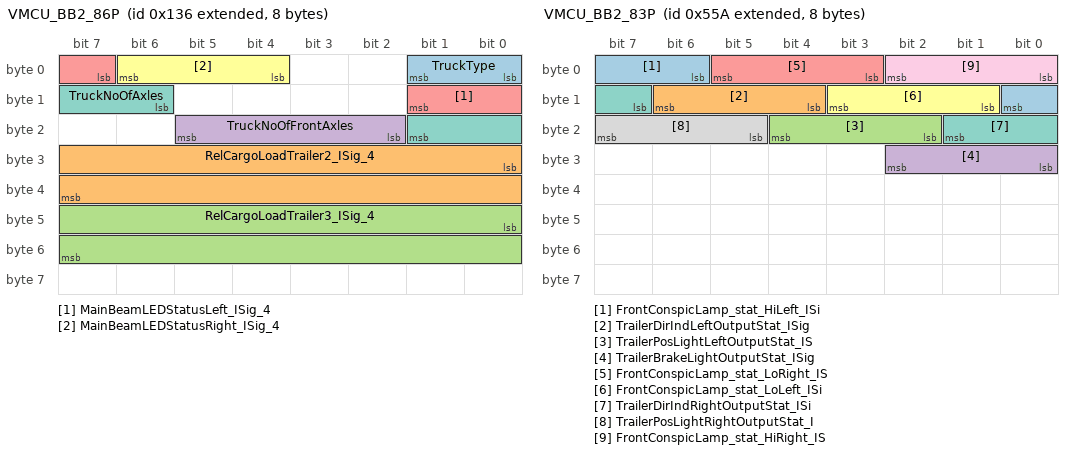
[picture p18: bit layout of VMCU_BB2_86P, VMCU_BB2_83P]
BO_ 2147483958 VMCU_BB2_86P: 8 VMCU
 SG_ TruckType : 0|2@1+ (1,0) [0|0] ""  IC3
 SG_ RelCargoLoadTrailer2_ISig_4 : 24|16@1+ (4,-128508) [-128508|133632] "kg"  IC3,CIOM
 SG_ RelCargoLoadTrailer3_ISig_4 : 40|16@1+ (4,-128508) [-128508|133632] "kg"  IC3,CIOM
 SG_ TruckNoOfFrontAxles : 18|4@1+ (1,0) [0|15] "NotApplicable"  IC3
 SG_ MainBeamLEDStatusLeft_ISig_4 : 7|3@1+ (1,0) [0|0] ""  IC3
 SG_ MainBeamLEDStatusRight_ISig_4 : 4|3@1+ (1,0) [0|0] ""  IC3
 SG_ TruckNoOfAxles : 14|4@1+ (1,0) [0|15] "NotApplicable"  IC3

BO_ 2147485015 VMCU_BB2_85P: 8 VMCU
 SG_ DistanceToEmptyLNG_ISig_4 : 48|16@1+ (1,0) [0|65535] "km"  IC3
 SG_ DistanceToEmpty_Diesel_ISig_4 : 32|16@1+ (1,0) [0|65535] "km"  IC3
 SG_ FuelLostInIdle : 0|32@1+ (0.01,0) [0|42949672.95] "l"  IC3

BO_ 2147485016 VMCU_BB2_84P: 8 VMCU
 SG_ FuelLostInOverAccel : 0|32@1+ (0.01,0) [0|42949672.95] "l"  IC3
 SG_ FuelLostInOverSpd : 32|32@1+ (0.01,0) [0|42949672.95] "l"  IC3

BO_ 2147485018 VMCU_BB2_83P: 8 VMCU
 SG_ FrontConspicLamp_stat_HiLeft_ISi : 6|3@1+ (1,0) [0|0] ""  IC3
 SG_ TrailerDirIndLeftOutputStat_ISig : 12|3@1+ (1,0) [0|0] ""  IC3
 SG_ TrailerPosLightLeftOutputStat_IS : 18|3@1+ (1,0) [0|0] ""  IC3
 SG_ TrailerBrakeLightOutputStat_ISig : 24|3@1+ (1,0) [0|0] ""  IC3
 SG_ FrontConspicLamp_stat_LoRight_IS : 3|3@1+ (1,0) [0|0] ""  IC3
 SG_ FrontConspicLamp_stat_LoLeft_ISi : 9|3@1+ (1,0) [0|0] ""  IC3
 SG_ TrailerDirIndRightOutputStat_ISi : 15|3@1+ (1,0) [0|0] ""  IC3
 SG_ TrailerPosLightRightOutputStat_I : 21|3@1+ (1,0) [0|0] ""  IC3
 SG_ FrontConspicLamp_stat_HiRight_IS : 0|3@1+ (1,0) [0|0] ""  IC3

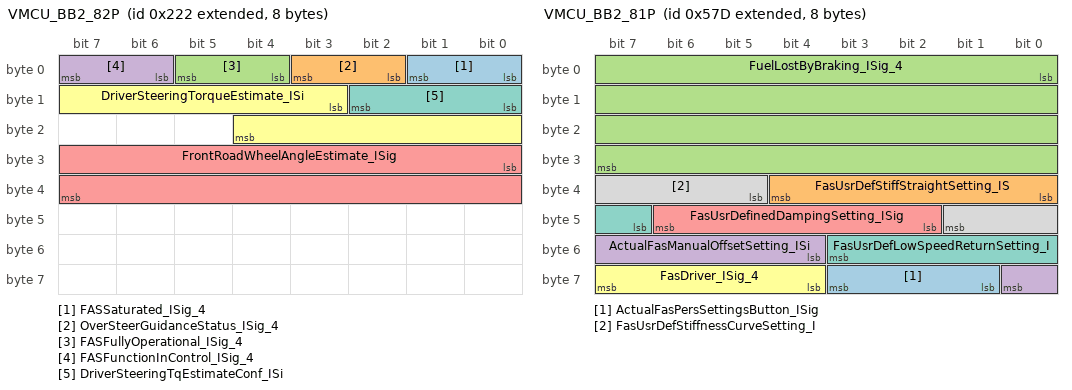
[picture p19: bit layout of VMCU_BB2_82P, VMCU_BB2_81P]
BO_ 2147484194 VMCU_BB2_82P: 8 VMCU
 SG_ FASSaturated_ISig_4 : 0|2@1+ (1,0) [0|0] ""  DACU
 SG_ OverSteerGuidanceStatus_ISig_4 : 2|2@1+ (1,0) [0|0] ""  IC3
 SG_ FASFullyOperational_ISig_4 : 4|2@1+ (1,0) [0|0] ""  DACU,BBM
 SG_ FASFunctionInControl_ISig_4 : 6|2@1+ (1,0) [0|0] ""  DACU
 SG_ FrontRoadWheelAngleEstimate_ISig : 24|16@1+ (5E-005,-1.6) [-1.6|1.67675] "rad"  DACU,BBM
 SG_ DriverSteeringTorqueEstimate_ISi : 11|10@1+ (0.05,-25) [-25|26.15] "Nm"  DACU
 SG_ DriverSteeringTqEstimateConf_ISi : 8|3@1+ (1,0) [0|0] ""  DACU

BO_ 2147485053 VMCU_BB2_81P: 8 VMCU
 SG_ ActualFasPersSettingsButton_ISig : 57|3@1+ (1,0) [0|0] ""  IC3
 SG_ FasUsrDefStiffStraightSetting_IS : 32|5@1+ (1,-10) [-10|21] ""  IC3
 SG_ FuelLostByBraking_ISig_4 : 0|32@1+ (0.01,0) [0|42949672.95] "l"  IC3
 SG_ ActualFasManualOffsetSetting_ISi : 52|5@1+ (1,-10) [-10|21] ""  IC3
 SG_ FasUsrDefinedDampingSetting_ISig : 42|5@1+ (1,-10) [-10|21] ""  IC3
 SG_ FasDriver_ISig_4 : 60|4@1+ (1,0) [0|0] ""  IC3
 SG_ FasUsrDefLowSpeedReturnSetting_I : 47|5@1+ (1,-10) [-10|21] ""  IC3
 SG_ FasUsrDefStiffnessCurveSetting_I : 37|5@1+ (1,-10) [-10|21] ""  IC3

BO_ 2147484478 VMCU_BB2_80P: 8 VMCU
 SG_ PS_PosLightDoorOpen : 10|2@1+ (1,0) [0|0] ""  IC3
 SG_ PS_FogLightRear : 24|2@1+ (1,0) [0|0] ""  IC3
 SG_ TrailerBodyLampDI_stat : 2|2@1+ (1,0) [0|0] ""  CIOM
 SG_ ParkedLoadDistribution_ISig_4 : 20|3@1+ (1,0) [0|0] ""  IC3
 SG_ PV_HeadLightLevel : 16|4@1+ (1,-7) [-7|8] "NotApplicable"  IC3
 SG_ TrailerBodyLampFdbk_stat : 0|2@1+ (1,0) [0|0] ""  CIOM
 SG_ PS_FogLightFront : 26|2@1+ (1,0) [0|0] ""  IC3
 SG_ Alcolock_PBReleaseInhibit_ind : 61|3@1+ (1,0) [0|0] ""  IC3
 SG_ DHCNotificationReq : 55|4@1+ (1,0) [0|0] ""  IC3
 SG_ DriverCrank_rqst : 12|2@1+ (1,0) [0|0] ""  IC3
 SG_ PS_HeadLightAdjustment : 8|2@1+ (1,0) [0|0] ""  IC3
 SG_ PS_MainBeam : 14|2@1+ (1,0) [0|0] ""  IC3
 SG_ InstFuel_ConsumpValue : 28|16@1+ (0.01,0) [0|655.35] ""  IC3
 SG_ InstFuel_VehicleMoving : 44|2@1+ (1,0) [0|0] ""  IC3
 SG_ PS_AFSAllowedInDriveP : 49|2@1+ (1,0) [0|0] ""  IC3
 SG_ PS_AFS : 46|3@1+ (1,0) [0|0] ""  IC3
 SG_ AC2CoolingFanControl_rqst : 4|2@1+ (1,0) [0|0] ""  CIOM
 SG_ DHCStatus : 53|2@1+ (1,0) [0|0] ""  IC3
 SG_ PS_PositionLight : 51|2@1+ (1,0) [0|0] ""  IC3

CM_ "COM_MATRIX_T2_1.6.0";
CM_ BO_ 3221225472 "This is a message for not used signals, created by Vector CANdb++ DBC OLE DB Provider.";
BA_DEF_ BO_  "GenMsgStartDelayTime" INT 0 0;
BA_DEF_ BO_  "GenMsgDelayTime" INT 0 0;
BA_DEF_ BO_  "GenMsgCycleTime" INT 0 0;
BA_DEF_ BO_  "GenMsgSendType" ENUM  "Cyclic","NotUsed","NotUsed","NotUsed","NotUsed","NotUsed","NotUsed","IfActive","NoMsgSendType","NotUsed";
BA_DEF_ SG_  "GenSigStartValue" INT 0 0;
BA_DEF_ SG_  "GenSigCycleTimeActive" INT 0 0;
BA_DEF_ SG_  "GenSigCycleTime" INT 0 0;
BA_DEF_ SG_  "GenSigSendType" ENUM  "Cyclic","OnWrite","OnWriteWithRepetition","OnChange","OnChangeWithRepetition","IfActive","IfActiveWithRepetition","NoSigSendType","NotUsed","NotUsed","NotUsed","NotUsed","NotUsed";
BA_DEF_  "Baudrate" INT 0 1000000;
BA_DEF_  "BusType" STRING ;
BA_DEF_  "NmType" STRING ;
BA_DEF_  "Manufacturer" STRING ;
BA_DEF_  "VersionYear" INT 0 99;
BA_DEF_  "VersionNumber" INT 0 99;
BA_DEF_  "VersionMonth" INT 1 12;
BA_DEF_  "VersionDay" INT 1 31;
BA_DEF_ BO_  "VFrameFormat" ENUM  "StandardCAN","ExtendedCAN","reserved","J1939PG";
BA_DEF_ BU_  "TpOwnSystemEcuNumber" HEX 0 255;
BA_DEF_ SG_  "SigType" ENUM  "Default","Range","RangeSigned","ASCII","Discrete","Control","ReferencePGN","DTC","StringDelimiter","StringLength","StringLengthControl";
BA_DEF_ SG_  "SeToolVersion_SIGNAL" STRING ;
BA_DEF_ SG_  "SeToolUniqueID_SIGNAL" STRING ;
BA_DEF_ SG_  "SeToolOwnerSigGroup_SIGNAL" STRING ;
BA_DEF_ SG_  "SeToolOwnerSigGroupID_SIGNAL" STRING ;
BA_DEF_ SG_  "SeToolName_SIGNAL" STRING ;
BA_DEF_ SG_  "SeToolItemID_SIGNAL" STRING ;
BA_DEF_ SG_  "SeToolAncestorID_SIGNAL" STRING ;
BA_DEF_ SG_  "Platform_VMCU1_Sig" ENUM  "No","Yes";
BA_DEF_ BU_  "NmStationAddress" INT 0 255;
BA_DEF_  "NmAsrWaitBusSleepTime" INT 0 65535;
BA_DEF_  "NmAsrTimeoutTime" INT 0 65535;
BA_DEF_  "NmAsrRepeatMessageTime" INT 0 65535;
BA_DEF_ BU_  "NmAsrNodeIdentifier" HEX 0 253;
BA_DEF_ BU_  "NmAsrNode" ENUM  "No","Yes";
BA_DEF_  "NmAsrMessageCount" INT 1 256;
BA_DEF_ BO_  "NmAsrMessage" ENUM  "No","Yes";
BA_DEF_  "NmAsrCanMsgCycleTime" INT 0 65535;
BA_DEF_  "NmAsrBaseAddress" HEX 0 536870911;
BA_DEF_ SG_  "NeedsUpdateBit" ENUM  "No","Yes";
BA_DEF_ SG_  "MmAnSignal" ENUM  "No","Yes";
BA_DEF_ BU_  "IsOBDrelevant" ENUM  "No","Yes";
BA_DEF_ SG_  "GenSigMaxLatency" INT 0 65535;
BA_DEF_ SG_  "GenSigILSupport" ENUM  "Yes","No";
BA_DEF_ BO_  "GenMsgRequestable" INT 0 1;
BA_DEF_ BO_  "GenMsgILSupport" ENUM  "No","Yes";
BA_DEF_ BU_  "DiagnosticClientAddress" HEX 0 255;
BA_DEF_ BO_  "DiagUUDTResponse" ENUM  "No","Yes";
BA_DEF_ BO_  "DiagState" ENUM  "No","Yes";
BA_DEF_ BU_  "DiagRole" ENUM  "None","OBDTester","ExternalTester","InternalTester";
BA_DEF_ BO_  "DiagResponse" ENUM  "No","Yes";
BA_DEF_ BO_  "DiagRequest" ENUM  "No","Yes";
BA_DEF_ BO_  "DiagConnection" HEX 0 65535;
BA_DEF_  "DBName" STRING ;
BA_DEF_ BO_  "CanTpSTmin" INT 0 255;
BA_DEF_ BO_  "CanTpFcFrameId" HEX 0 2147483647;
BA_DEF_ BO_  "CanTpBs" INT 0 255;
BA_DEF_ SG_  "SystemSignalLongSymbol" STRING ;
BA_DEF_REL_ BU_SG_REL_  "GenSigTimeoutTime" INT 0 65535;
BA_DEF_REL_ BU_SG_REL_  "GenSigFirstTimeoutTime" INT 0 65535;
BA_DEF_DEF_  "GenMsgStartDelayTime" 0;
BA_DEF_DEF_  "GenMsgDelayTime" 0;
BA_DEF_DEF_  "GenMsgCycleTime" 0;
BA_DEF_DEF_  "GenMsgSendType" "Cyclic";
BA_DEF_DEF_  "GenSigStartValue" 0;
BA_DEF_DEF_  "GenSigCycleTimeActive" 0;
BA_DEF_DEF_  "GenSigCycleTime" 0;
BA_DEF_DEF_  "GenSigSendType" "Cyclic";
BA_DEF_DEF_  "Baudrate" 500000;
BA_DEF_DEF_  "BusType" "";
BA_DEF_DEF_  "NmType" "";
BA_DEF_DEF_  "Manufacturer" "VOLVO_AB";
BA_DEF_DEF_  "VersionYear" 0;
BA_DEF_DEF_  "VersionNumber" 0;
BA_DEF_DEF_  "VersionMonth" 1;
BA_DEF_DEF_  "VersionDay" 1;
BA_DEF_DEF_  "VFrameFormat" "ExtendedCAN";
BA_DEF_DEF_  "TpOwnSystemEcuNumber" 0;
BA_DEF_DEF_  "SigType" "Default";
BA_DEF_DEF_  "SeToolVersion_SIGNAL" "";
BA_DEF_DEF_  "SeToolUniqueID_SIGNAL" "";
BA_DEF_DEF_  "SeToolOwnerSigGroup_SIGNAL" "";
BA_DEF_DEF_  "SeToolOwnerSigGroupID_SIGNAL" "";
BA_DEF_DEF_  "SeToolName_SIGNAL" "";
BA_DEF_DEF_  "SeToolItemID_SIGNAL" "";
BA_DEF_DEF_  "SeToolAncestorID_SIGNAL" "";
BA_DEF_DEF_  "Platform_VMCU1_Sig" "No";
BA_DEF_DEF_  "NmStationAddress" 254;
BA_DEF_DEF_  "NmAsrWaitBusSleepTime" 750;
BA_DEF_DEF_  "NmAsrTimeoutTime" 5000;
BA_DEF_DEF_  "NmAsrRepeatMessageTime" 300;
BA_DEF_DEF_  "NmAsrNodeIdentifier" 0;
BA_DEF_DEF_  "NmAsrNode" "Yes";
BA_DEF_DEF_  "NmAsrMessageCount" 256;
BA_DEF_DEF_  "NmAsrMessage" "No";
BA_DEF_DEF_  "NmAsrCanMsgCycleTime" 200;
BA_DEF_DEF_  "NmAsrBaseAddress" 486506496;
BA_DEF_DEF_  "NeedsUpdateBit" "No";
BA_DEF_DEF_  "MmAnSignal" "No";
BA_DEF_DEF_  "IsOBDrelevant" "No";
BA_DEF_DEF_  "GenSigMaxLatency" 0;
BA_DEF_DEF_  "GenSigILSupport" "Yes";
BA_DEF_DEF_  "GenMsgRequestable" 1;
BA_DEF_DEF_  "GenMsgILSupport" "Yes";
BA_DEF_DEF_  "DiagnosticClientAddress" 0;
BA_DEF_DEF_  "DiagUUDTResponse" "No";
BA_DEF_DEF_  "DiagState" "No";
BA_DEF_DEF_  "DiagRole" "None";
BA_DEF_DEF_  "DiagResponse" "No";
BA_DEF_DEF_  "DiagRequest" "No";
BA_DEF_DEF_  "DiagConnection" 0;
BA_DEF_DEF_  "DBName" "";
BA_DEF_DEF_  "CanTpSTmin" 0;
BA_DEF_DEF_  "CanTpFcFrameId" 2147483647;
BA_DEF_DEF_  "CanTpBs" 255;
BA_DEF_DEF_REL_ "GenSigTimeoutTime" 0;
BA_DEF_DEF_REL_ "GenSigFirstTimeoutTime" 0;
BA_DEF_DEF_  "SystemSignalLongSymbol" "";
BA_ "NmType" "NmAsr";
BA_ "BusType" "CAN";
BA_ "VersionDay" 17;
BA_ "VersionNumber" 1;
BA_ "VersionYear" 18;
BA_ "DBName" "Backbone2";
BA_ "IsOBDrelevant" BU_ VMCU 1;
BA_ "TpOwnSystemEcuNumber" BU_ VMCU 36;
BA_ "NmAsrNodeIdentifier" BU_ VMCU 36;
BA_ "TpOwnSystemEcuNumber" BU_ TECU 24;
BA_ "NmAsrNodeIdentifier" BU_ TECU 24;
BA_ "DiagRole" BU_ IC3 3;
BA_ "DiagnosticClientAddress" BU_ IC3 243;
BA_ "TpOwnSystemEcuNumber" BU_ IC3 97;
BA_ "NmAsrNodeIdentifier" BU_ IC3 96;
BA_ "IsOBDrelevant" BU_ EMS 1;
BA_ "TpOwnSystemEcuNumber" BU_ EMS 16;
BA_ "NmAsrNodeIdentifier" BU_ EMS 16;
BA_ "TpOwnSystemEcuNumber" BU_ DACU 80;
BA_ "NmAsrNodeIdentifier" BU_ DACU 80;
BA_ "TpOwnSystemEcuNumber" BU_ CIOM 64;
BA_ "NmAsrNodeIdentifier" BU_ CIOM 64;
BA_ "TpOwnSystemEcuNumber" BU_ BBM 230;
BA_ "NmAsrNodeIdentifier" BU_ BBM 230;
BA_ "GenMsgDelayTime" BO_ 2045 50;
BA_ "GenMsgStartDelayTime" BO_ 2045 50;
BA_ "GenMsgCycleTime" BO_ 2045 20;
BA_ "VFrameFormat" BO_ 2045 0;
BA_ "VFrameFormat" BO_ 2044 0;
BA_ "GenMsgStartDelayTime" BO_ 2044 50;
BA_ "GenMsgDelayTime" BO_ 2044 50;
BA_ "GenMsgCycleTime" BO_ 2044 20;
BA_ "GenMsgCycleTime" BO_ 2034 20;
BA_ "VFrameFormat" BO_ 2034 0;
BA_ "GenMsgStartDelayTime" BO_ 2034 50;
BA_ "GenMsgDelayTime" BO_ 2034 50;
BA_ "GenMsgCycleTime" BO_ 2033 20;
BA_ "VFrameFormat" BO_ 2033 0;
BA_ "GenMsgStartDelayTime" BO_ 2033 50;
BA_ "GenMsgDelayTime" BO_ 2033 50;
BA_ "GenMsgCycleTime" BO_ 2032 20;
BA_ "VFrameFormat" BO_ 2032 0;
BA_ "GenMsgStartDelayTime" BO_ 2032 50;
BA_ "GenMsgDelayTime" BO_ 2032 50;
BA_ "GenMsgCycleTime" BO_ 2024 20;
BA_ "VFrameFormat" BO_ 2024 0;
BA_ "GenMsgStartDelayTime" BO_ 2024 50;
BA_ "GenMsgDelayTime" BO_ 2024 50;
BA_ "VFrameFormat" BO_ 2043 0;
BA_ "VFrameFormat" BO_ 2042 0;
BA_ "GenMsgCycleTime" BO_ 2041 20;
BA_ "GenMsgDelayTime" BO_ 2041 50;
BA_ "GenMsgStartDelayTime" BO_ 2041 50;
BA_ "GenMsgSendType" BO_ 2041 8;
BA_ "VFrameFormat" BO_ 2041 0;
BA_ "GenMsgCycleTime" BO_ 2040 20;
BA_ "GenMsgDelayTime" BO_ 2040 50;
BA_ "GenMsgStartDelayTime" BO_ 2040 50;
BA_ "GenMsgSendType" BO_ 2040 8;
BA_ "VFrameFormat" BO_ 2040 0;
BA_ "GenMsgCycleTime" BO_ 2023 20;
BA_ "VFrameFormat" BO_ 2023 0;
BA_ "GenMsgStartDelayTime" BO_ 2023 50;
BA_ "GenMsgDelayTime" BO_ 2023 50;
BA_ "GenMsgCycleTime" BO_ 2022 20;
BA_ "VFrameFormat" BO_ 2022 0;
BA_ "GenMsgStartDelayTime" BO_ 2022 50;
BA_ "GenMsgDelayTime" BO_ 2022 50;
BA_ "GenMsgCycleTime" BO_ 2021 20;
BA_ "VFrameFormat" BO_ 2021 0;
BA_ "GenMsgStartDelayTime" BO_ 2021 50;
BA_ "GenMsgDelayTime" BO_ 2021 50;
BA_ "GenMsgCycleTime" BO_ 2020 20;
BA_ "VFrameFormat" BO_ 2020 0;
BA_ "GenMsgStartDelayTime" BO_ 2020 50;
BA_ "GenMsgDelayTime" BO_ 2020 50;
BA_ "GenMsgCycleTime" BO_ 2039 20;
BA_ "GenMsgDelayTime" BO_ 2039 50;
BA_ "GenMsgStartDelayTime" BO_ 2039 50;
BA_ "GenMsgSendType" BO_ 2039 8;
BA_ "VFrameFormat" BO_ 2039 0;
BA_ "GenMsgCycleTime" BO_ 2038 20;
BA_ "GenMsgDelayTime" BO_ 2038 50;
BA_ "GenMsgStartDelayTime" BO_ 2038 50;
BA_ "GenMsgSendType" BO_ 2038 8;
BA_ "VFrameFormat" BO_ 2038 0;
BA_ "GenMsgCycleTime" BO_ 2037 20;
BA_ "GenMsgDelayTime" BO_ 2037 50;
BA_ "GenMsgStartDelayTime" BO_ 2037 50;
BA_ "GenMsgSendType" BO_ 2037 8;
BA_ "VFrameFormat" BO_ 2037 0;
BA_ "GenMsgCycleTime" BO_ 2036 20;
BA_ "GenMsgDelayTime" BO_ 2036 50;
BA_ "GenMsgStartDelayTime" BO_ 2036 50;
BA_ "GenMsgSendType" BO_ 2036 8;
BA_ "VFrameFormat" BO_ 2036 0;
BA_ "GenMsgCycleTime" BO_ 2019 20;
BA_ "VFrameFormat" BO_ 2019 0;
BA_ "GenMsgStartDelayTime" BO_ 2019 50;
BA_ "GenMsgDelayTime" BO_ 2019 50;
BA_ "GenMsgCycleTime" BO_ 2018 20;
BA_ "VFrameFormat" BO_ 2018 0;
BA_ "GenMsgStartDelayTime" BO_ 2018 50;
BA_ "GenMsgDelayTime" BO_ 2018 50;
BA_ "GenMsgCycleTime" BO_ 2035 20;
BA_ "GenMsgDelayTime" BO_ 2035 50;
BA_ "GenMsgStartDelayTime" BO_ 2035 50;
BA_ "GenMsgSendType" BO_ 2035 8;
BA_ "VFrameFormat" BO_ 2035 0;
BA_ "GenMsgCycleTime" BO_ 2017 20;
BA_ "VFrameFormat" BO_ 2017 0;
BA_ "GenMsgStartDelayTime" BO_ 2017 50;
BA_ "GenMsgDelayTime" BO_ 2017 50;
BA_ "GenMsgCycleTime" BO_ 2016 20;
BA_ "VFrameFormat" BO_ 2016 0;
BA_ "GenMsgStartDelayTime" BO_ 2016 50;
BA_ "GenMsgDelayTime" BO_ 2016 50;
BA_ "GenMsgCycleTime" BO_ 2015 20;
BA_ "VFrameFormat" BO_ 2015 0;
BA_ "GenMsgStartDelayTime" BO_ 2015 50;
BA_ "GenMsgDelayTime" BO_ 2015 50;
BA_ "GenMsgCycleTime" BO_ 2014 20;
BA_ "GenMsgDelayTime" BO_ 2014 50;
BA_ "GenMsgStartDelayTime" BO_ 2014 50;
BA_ "GenMsgSendType" BO_ 2014 8;
BA_ "VFrameFormat" BO_ 2014 0;
BA_ "GenMsgCycleTime" BO_ 2013 20;
BA_ "GenMsgDelayTime" BO_ 2013 50;
BA_ "GenMsgStartDelayTime" BO_ 2013 50;
BA_ "GenMsgSendType" BO_ 2013 8;
BA_ "VFrameFormat" BO_ 2013 0;
BA_ "GenMsgCycleTime" BO_ 2012 20;
BA_ "VFrameFormat" BO_ 2012 0;
BA_ "GenMsgDelayTime" BO_ 2012 50;
BA_ "GenMsgStartDelayTime" BO_ 2012 50;
BA_ "GenMsgCycleTime" BO_ 2011 20;
BA_ "VFrameFormat" BO_ 2011 0;
BA_ "GenMsgDelayTime" BO_ 2011 50;
BA_ "GenMsgStartDelayTime" BO_ 2011 50;
BA_ "VFrameFormat" BO_ 2010 0;
BA_ "GenMsgDelayTime" BO_ 2010 50;
BA_ "GenMsgStartDelayTime" BO_ 2010 50;
BA_ "GenMsgCycleTime" BO_ 2010 20;
BA_ "GenMsgCycleTime" BO_ 2009 20;
BA_ "VFrameFormat" BO_ 2009 0;
BA_ "GenMsgDelayTime" BO_ 2009 50;
BA_ "GenMsgStartDelayTime" BO_ 2009 50;
BA_ "GenMsgCycleTime" BO_ 2008 20;
BA_ "VFrameFormat" BO_ 2008 0;
BA_ "GenMsgDelayTime" BO_ 2008 50;
BA_ "GenMsgStartDelayTime" BO_ 2008 50;
BA_ "GenMsgCycleTime" BO_ 2007 20;
BA_ "VFrameFormat" BO_ 2007 0;
BA_ "GenMsgDelayTime" BO_ 2007 50;
BA_ "GenMsgStartDelayTime" BO_ 2007 50;
BA_ "GenMsgCycleTime" BO_ 2147484948 1000;
BA_ "GenMsgStartDelayTime" BO_ 2147484948 95;
BA_ "GenMsgCycleTime" BO_ 2147484947 1000;
BA_ "GenMsgStartDelayTime" BO_ 2147484947 85;
BA_ "GenMsgCycleTime" BO_ 2147484946 1000;
BA_ "GenMsgStartDelayTime" BO_ 2147484946 75;
BA_ "GenMsgCycleTime" BO_ 2147484945 1000;
BA_ "GenMsgStartDelayTime" BO_ 2147484945 60;
BA_ "GenMsgCycleTime" BO_ 2147484944 1000;
BA_ "GenMsgStartDelayTime" BO_ 2147484944 50;
BA_ "GenMsgCycleTime" BO_ 2147485038 1000;
BA_ "GenMsgStartDelayTime" BO_ 2147485038 160;
BA_ "GenMsgCycleTime" BO_ 2147485031 1000;
BA_ "GenMsgStartDelayTime" BO_ 2147485031 150;
BA_ "GenMsgCycleTime" BO_ 2147485028 1000;
BA_ "GenMsgStartDelayTime" BO_ 2147485028 140;
BA_ "GenMsgCycleTime" BO_ 2147485026 1000;
BA_ "GenMsgStartDelayTime" BO_ 2147485026 130;
BA_ "GenMsgCycleTime" BO_ 2147484291 1000;
BA_ "GenMsgStartDelayTime" BO_ 2147484291 135;
BA_ "GenMsgCycleTime" BO_ 2147484181 500;
BA_ "GenMsgStartDelayTime" BO_ 2147484181 105;
BA_ "GenMsgCycleTime" BO_ 2147484069 500;
BA_ "GenMsgStartDelayTime" BO_ 2147484069 90;
BA_ "GenMsgCycleTime" BO_ 2147483971 500;
BA_ "GenMsgStartDelayTime" BO_ 2147483971 75;
BA_ "GenMsgCycleTime" BO_ 2147483958 500;
BA_ "GenMsgStartDelayTime" BO_ 2147483958 50;
BA_ "GenMsgCycleTime" BO_ 2147485015 1000;
BA_ "GenMsgStartDelayTime" BO_ 2147485015 125;
BA_ "GenMsgCycleTime" BO_ 2147485016 1000;
BA_ "GenMsgStartDelayTime" BO_ 2147485016 70;
BA_ "GenMsgCycleTime" BO_ 2147485018 250;
BA_ "GenMsgStartDelayTime" BO_ 2147485018 60;
BA_ "GenMsgCycleTime" BO_ 2147484194 20;
BA_ "GenMsgStartDelayTime" BO_ 2147484194 10;
BA_ "GenMsgCycleTime" BO_ 2147485053 1000;
BA_ "GenMsgStartDelayTime" BO_ 2147485053 25;
BA_ "GenMsgCycleTime" BO_ 2147484478 100;
BA_ "GenMsgStartDelayTime" BO_ 2147484478 10;
BA_ "GenSigSendType" SG_ 3221225472 Debug_6_CIOM 1;
BA_ "GenSigMaxLatency" SG_ 3221225472 Debug_6_CIOM 55;
BA_ "Platform_VMCU1_Sig" SG_ 3221225472 Debug_6_CIOM 1;
BA_ "GenSigSendType" SG_ 3221225472 Debug_5_CIOM 1;
BA_ "GenSigMaxLatency" SG_ 3221225472 Debug_5_CIOM 55;
BA_ "Platform_VMCU1_Sig" SG_ 3221225472 Debug_5_CIOM 1;
BA_ "GenSigSendType" SG_ 3221225472 Debug_4_CIOM 1;
BA_ "GenSigMaxLatency" SG_ 3221225472 Debug_4_CIOM 55;
BA_ "Platform_VMCU1_Sig" SG_ 3221225472 Debug_4_CIOM 1;
BA_ "GenSigSendType" SG_ 3221225472 Debug_3_CIOM 1;
BA_ "GenSigMaxLatency" SG_ 3221225472 Debug_3_CIOM 55;
BA_ "Platform_VMCU1_Sig" SG_ 3221225472 Debug_3_CIOM 1;
BA_ "GenSigSendType" SG_ 3221225472 Debug_2_CIOM 1;
BA_ "GenSigMaxLatency" SG_ 3221225472 Debug_2_CIOM 55;
BA_ "Platform_VMCU1_Sig" SG_ 3221225472 Debug_2_CIOM 1;
BA_ "GenSigCycleTime" SG_ 2045 Debug_PVT_SCIM_RD_ADI13 100;
BA_ "GenSigCycleTimeActive" SG_ 2045 Debug_PVT_SCIM_RD_ADI13 100;
BA_ "GenSigCycleTime" SG_ 2045 Debug_PVT_SCIM_RD_ADI14 100;
BA_ "GenSigCycleTimeActive" SG_ 2045 Debug_PVT_SCIM_RD_ADI14 100;
BA_ "GenSigCycleTime" SG_ 2045 Debug_PVT_SCIM_RD_ADI15 100;
BA_ "GenSigCycleTimeActive" SG_ 2045 Debug_PVT_SCIM_RD_ADI15 100;
BA_ "GenSigCycleTime" SG_ 2045 Debug_PVT_SCIM_RD_ADI16 100;
BA_ "GenSigCycleTimeActive" SG_ 2045 Debug_PVT_SCIM_RD_ADI16 100;
BA_ "GenSigCycleTime" SG_ 2044 Debug_PVT_SCIM_RD_DAI1Fault 100;
BA_ "GenSigCycleTimeActive" SG_ 2044 Debug_PVT_SCIM_RD_DAI1Fault 100;
BA_ "GenSigCycleTime" SG_ 2044 Debug_PVT_SCIM_RD_DAI2Fualt 100;
BA_ "GenSigCycleTimeActive" SG_ 2044 Debug_PVT_SCIM_RD_DAI2Fualt 100;
BA_ "GenSigCycleTime" SG_ 2044 Debug_PVT_SCIM_RD_ADI16Fault 100;
BA_ "GenSigCycleTimeActive" SG_ 2044 Debug_PVT_SCIM_RD_ADI16Fault 100;
BA_ "GenSigCycleTime" SG_ 2044 Debug_PVT_SCIM_RD_ADI15Fault 100;
BA_ "GenSigCycleTimeActive" SG_ 2044 Debug_PVT_SCIM_RD_ADI15Fault 100;
BA_ "GenSigCycleTime" SG_ 2044 Debug_PVT_SCIM_RD_ADI14Fault 100;
BA_ "GenSigCycleTimeActive" SG_ 2044 Debug_PVT_SCIM_RD_ADI14Fault 100;
BA_ "GenSigCycleTime" SG_ 2044 Debug_PVT_SCIM_RD_ADI13Fault 100;
BA_ "GenSigCycleTimeActive" SG_ 2044 Debug_PVT_SCIM_RD_ADI13Fault 100;
BA_ "GenSigCycleTime" SG_ 2044 Debug_PVT_SCIM_RD_ADI12Fault 100;
BA_ "GenSigCycleTimeActive" SG_ 2044 Debug_PVT_SCIM_RD_ADI12Fault 100;
BA_ "GenSigCycleTime" SG_ 2044 Debug_PVT_SCIM_RD_ADI11Fault 100;
BA_ "GenSigCycleTimeActive" SG_ 2044 Debug_PVT_SCIM_RD_ADI11Fault 100;
BA_ "GenSigCycleTime" SG_ 2044 Debug_PVT_SCIM_RD_ADI10Fault 100;
BA_ "GenSigCycleTimeActive" SG_ 2044 Debug_PVT_SCIM_RD_ADI10Fault 100;
BA_ "GenSigCycleTime" SG_ 2044 Debug_PVT_SCIM_RD_ADI09Fault 100;
BA_ "GenSigCycleTimeActive" SG_ 2044 Debug_PVT_SCIM_RD_ADI09Fault 100;
BA_ "GenSigCycleTime" SG_ 2044 Debug_PVT_SCIM_RD_ADI08Fault 100;
BA_ "GenSigCycleTimeActive" SG_ 2044 Debug_PVT_SCIM_RD_ADI08Fault 100;
BA_ "GenSigCycleTime" SG_ 2044 Debug_PVT_SCIM_RD_ADI07Fault 100;
BA_ "GenSigCycleTimeActive" SG_ 2044 Debug_PVT_SCIM_RD_ADI07Fault 100;
BA_ "GenSigCycleTime" SG_ 2044 Debug_PVT_SCIM_RD_ADI06Fault 100;
BA_ "GenSigCycleTimeActive" SG_ 2044 Debug_PVT_SCIM_RD_ADI06Fault 100;
BA_ "GenSigCycleTime" SG_ 2044 Debug_PVT_SCIM_RD_ADI05Fault 100;
BA_ "GenSigCycleTimeActive" SG_ 2044 Debug_PVT_SCIM_RD_ADI05Fault 100;
BA_ "GenSigCycleTime" SG_ 2044 Debug_PVT_SCIM_RD_ADI04Fault 100;
BA_ "GenSigCycleTimeActive" SG_ 2044 Debug_PVT_SCIM_RD_ADI04Fault 100;
BA_ "GenSigCycleTime" SG_ 2044 Debug_PVT_SCIM_RD_ADI03Fault 100;
BA_ "GenSigCycleTimeActive" SG_ 2044 Debug_PVT_SCIM_RD_ADI03Fault 100;
BA_ "GenSigCycleTime" SG_ 2044 Debug_PVT_SCIM_RD_ADI02Fault 100;
BA_ "GenSigCycleTimeActive" SG_ 2044 Debug_PVT_SCIM_RD_ADI02Fault 100;
BA_ "GenSigCycleTime" SG_ 2044 Debug_PVT_SCIM_RD_ADI01Fault 100;
BA_ "GenSigCycleTimeActive" SG_ 2044 Debug_PVT_SCIM_RD_ADI01Fault 100;
BA_ "GenSigCycleTime" SG_ 2034 Debug_PVT_PEPS_AverRSSI2 100;
BA_ "GenSigCycleTimeActive" SG_ 2034 Debug_PVT_PEPS_AverRSSI2 100;
BA_ "GenSigCycleTime" SG_ 2034 Debug_PVT_PEPS_AverRSSI1 100;
BA_ "GenSigCycleTimeActive" SG_ 2034 Debug_PVT_PEPS_AverRSSI1 100;
BA_ "GenSigCycleTimeActive" SG_ 2034 Debug_PVT_PEPS_DecRSSI 100;
BA_ "GenSigCycleTime" SG_ 2034 Debug_PVT_PEPS_DecRSSI 100;
BA_ "GenSigCycleTime" SG_ 2033 Debug_PVT_PEPS_Cali_Cir 100;
BA_ "GenSigCycleTimeActive" SG_ 2033 Debug_PVT_PEPS_Cali_Cir 100;
BA_ "GenSigCycleTime" SG_ 2033 Debug_PVT_PEPS_K_Cir 100;
BA_ "GenSigCycleTimeActive" SG_ 2033 Debug_PVT_PEPS_K_Cir 100;
BA_ "GenSigCycleTime" SG_ 2033 Debug_PVT_PEPS_D_AntP1toP2_Y 100;
BA_ "GenSigCycleTimeActive" SG_ 2033 Debug_PVT_PEPS_D_AntP1toP2_Y 100;
BA_ "GenSigCycleTime" SG_ 2033 Debug_PVT_PEPS_D_AntP1toP2_X 100;
BA_ "GenSigCycleTimeActive" SG_ 2033 Debug_PVT_PEPS_D_AntP1toP2_X 100;
BA_ "GenSigCycleTime" SG_ 2032 Debug_PVT_PEPS_D_AntP1toP2_Cir 100;
BA_ "GenSigCycleTimeActive" SG_ 2032 Debug_PVT_PEPS_D_AntP1toP2_Cir 100;
BA_ "GenSigCycleTime" SG_ 2032 Debug_PVT_PEPS_CTPoint_Y2 100;
BA_ "GenSigCycleTimeActive" SG_ 2032 Debug_PVT_PEPS_CTPoint_Y2 100;
BA_ "GenSigCycleTime" SG_ 2032 Debug_PVT_PEPS_CTPoint_Y1 100;
BA_ "GenSigCycleTimeActive" SG_ 2032 Debug_PVT_PEPS_CTPoint_Y1 100;
BA_ "GenSigCycleTime" SG_ 2032 Debug_PVT_PEPS_CTPoint_X2 100;
BA_ "GenSigCycleTimeActive" SG_ 2032 Debug_PVT_PEPS_CTPoint_X2 100;
BA_ "GenSigCycleTime" SG_ 2032 Debug_PVT_PEPS_CTPoint_X1 100;
BA_ "GenSigCycleTimeActive" SG_ 2032 Debug_PVT_PEPS_CTPoint_X1 100;
BA_ "GenSigCycleTimeActive" SG_ 2024 Debug_PVT_PEPS_AntPi_Y 100;
BA_ "GenSigCycleTime" SG_ 2024 Debug_PVT_PEPS_AntPi_Y 100;
BA_ "GenSigCycleTimeActive" SG_ 2024 Debug_PVT_PEPS_AntPi_X 100;
BA_ "GenSigCycleTime" SG_ 2024 Debug_PVT_PEPS_AntPi_X 100;
BA_ "GenSigCycleTimeActive" SG_ 2024 Debug_PVT_PEPS_AntP1_Y 100;
BA_ "GenSigCycleTime" SG_ 2024 Debug_PVT_PEPS_AntP1_Y 100;
BA_ "GenSigCycleTimeActive" SG_ 2024 Debug_PVT_PEPS_AntP1_X 100;
BA_ "GenSigCycleTime" SG_ 2024 Debug_PVT_PEPS_AntP1_X 100;
BA_ "GenSigCycleTimeActive" SG_ 2023 Debug_PVT_PEPS_Vwidth 100;
BA_ "GenSigCycleTime" SG_ 2023 Debug_PVT_PEPS_Vwidth 100;
BA_ "GenSigCycleTimeActive" SG_ 2023 Debug_PVT_PEPS_Vsquare 100;
BA_ "GenSigCycleTime" SG_ 2023 Debug_PVT_PEPS_Vsquare 100;
BA_ "GenSigCycleTimeActive" SG_ 2023 Debug_PVT_PEPS_Vlength 100;
BA_ "GenSigCycleTime" SG_ 2023 Debug_PVT_PEPS_Vlength 100;
BA_ "GenSigCycleTime" SG_ 2023 Debug_PVT_PEPS_K_AntP4 100;
BA_ "GenSigCycleTimeActive" SG_ 2023 Debug_PVT_PEPS_K_AntP4 100;
BA_ "GenSigCycleTime" SG_ 2022 Debug_PVT_PEPS_K_AntPi 100;
BA_ "GenSigCycleTimeActive" SG_ 2022 Debug_PVT_PEPS_K_AntPi 100;
BA_ "GenSigCycleTime" SG_ 2022 Debug_PVT_PEPS_K_AntP3 100;
BA_ "GenSigCycleTimeActive" SG_ 2022 Debug_PVT_PEPS_K_AntP3 100;
BA_ "GenSigCycleTime" SG_ 2022 Debug_PVT_PEPS_K_AntP2 100;
BA_ "GenSigCycleTimeActive" SG_ 2022 Debug_PVT_PEPS_K_AntP2 100;
BA_ "GenSigCycleTime" SG_ 2022 Debug_PVT_PEPS_K_AntP1 100;
BA_ "GenSigCycleTimeActive" SG_ 2022 Debug_PVT_PEPS_K_AntP1 100;
BA_ "GenSigCycleTimeActive" SG_ 2021 Debug_PVT_PEPS_A_AntPi 100;
BA_ "GenSigCycleTime" SG_ 2021 Debug_PVT_PEPS_A_AntPi 100;
BA_ "GenSigCycleTimeActive" SG_ 2021 Debug_PVT_PEPS_A_AntP4 100;
BA_ "GenSigCycleTime" SG_ 2021 Debug_PVT_PEPS_A_AntP4 100;
BA_ "GenSigCycleTimeActive" SG_ 2021 Debug_PVT_PEPS_A_AntP3 100;
BA_ "GenSigCycleTime" SG_ 2021 Debug_PVT_PEPS_A_AntP3 100;
BA_ "GenSigCycleTimeActive" SG_ 2021 Debug_PVT_PEPS_A_AntP2 100;
BA_ "GenSigCycleTime" SG_ 2021 Debug_PVT_PEPS_A_AntP2 100;
BA_ "GenSigCycleTimeActive" SG_ 2021 Debug_PVT_PEPS_A_AntP1 100;
BA_ "GenSigCycleTime" SG_ 2021 Debug_PVT_PEPS_A_AntP1 100;
BA_ "GenSigCycleTime" SG_ 2020 Debug_PVT_PEPS_LimitRSSIPi 100;
BA_ "GenSigCycleTimeActive" SG_ 2020 Debug_PVT_PEPS_LimitRSSIPi 100;
BA_ "GenSigCycleTime" SG_ 2020 Debug_PVT_PEPS_LimitRSSIP4 100;
BA_ "GenSigCycleTimeActive" SG_ 2020 Debug_PVT_PEPS_LimitRSSIP4 100;
BA_ "GenSigCycleTime" SG_ 2020 Debug_PVT_PEPS_LimitRSSIP3 100;
BA_ "GenSigCycleTimeActive" SG_ 2020 Debug_PVT_PEPS_LimitRSSIP3 100;
BA_ "GenSigCycleTime" SG_ 2020 Debug_PVT_PEPS_LimitRSSIP2 100;
BA_ "GenSigCycleTimeActive" SG_ 2020 Debug_PVT_PEPS_LimitRSSIP2 100;
BA_ "GenSigCycleTime" SG_ 2020 Debug_PVT_PEPS_LimitRSSIP1 100;
BA_ "GenSigCycleTimeActive" SG_ 2020 Debug_PVT_PEPS_LimitRSSIP1 100;
BA_ "GenSigCycleTimeActive" SG_ 2038 Debug_PVT_PEPS_A_AntPi_Ctrl 100;
BA_ "GenSigCycleTime" SG_ 2038 Debug_PVT_PEPS_A_AntPi_Ctrl 100;
BA_ "GenSigCycleTimeActive" SG_ 2038 Debug_PVT_PEPS_A_AntP4_Ctrl 100;
BA_ "GenSigCycleTime" SG_ 2038 Debug_PVT_PEPS_A_AntP4_Ctrl 100;
BA_ "GenSigCycleTime" SG_ 2038 Debug_PVT_PEPS_A_AntP3_Ctrl 100;
BA_ "GenSigCycleTimeActive" SG_ 2038 Debug_PVT_PEPS_A_AntP3_Ctrl 100;
BA_ "GenSigCycleTimeActive" SG_ 2038 Debug_PVT_PEPS_A_AntP2_Ctrl 100;
BA_ "GenSigCycleTime" SG_ 2038 Debug_PVT_PEPS_A_AntP2_Ctrl 100;
BA_ "GenSigCycleTimeActive" SG_ 2038 Debug_PVT_PEPS_A_AntP1_Ctrl 100;
BA_ "GenSigCycleTime" SG_ 2038 Debug_PVT_PEPS_A_AntP1_Ctrl 100;
BA_ "GenSigCycleTimeActive" SG_ 2019 Debug_PVT_PEPS_Avercut 100;
BA_ "GenSigCycleTime" SG_ 2019 Debug_PVT_PEPS_Avercut 100;
BA_ "GenSigCycleTime" SG_ 2019 Debug_PVT_PEPS_Pi_RSSIcut 100;
BA_ "GenSigCycleTimeActive" SG_ 2019 Debug_PVT_PEPS_Pi_RSSIcut 100;
BA_ "GenSigCycleTimeActive" SG_ 2019 Debug_PVT_PEPS_P2_RSSIcut 100;
BA_ "GenSigCycleTime" SG_ 2019 Debug_PVT_PEPS_P2_RSSIcut 100;
BA_ "GenSigCycleTimeActive" SG_ 2019 Debug_PVT_PEPS_P3_RSSIcut 100;
BA_ "GenSigCycleTime" SG_ 2019 Debug_PVT_PEPS_P3_RSSIcut 100;
BA_ "GenSigCycleTime" SG_ 2018 Debug_PVT_PEPS_Pi_MaxRSSI 100;
BA_ "GenSigCycleTimeActive" SG_ 2018 Debug_PVT_PEPS_Pi_MaxRSSI 100;
BA_ "GenSigCycleTimeActive" SG_ 2018 Debug_PVT_PEPS_P4_MaxRSSI 100;
BA_ "GenSigCycleTime" SG_ 2018 Debug_PVT_PEPS_P4_MaxRSSI 100;
BA_ "GenSigCycleTimeActive" SG_ 2018 Debug_PVT_PEPS_P3_MaxRSSI 100;
BA_ "GenSigCycleTime" SG_ 2018 Debug_PVT_PEPS_P3_MaxRSSI 100;
BA_ "GenSigCycleTimeActive" SG_ 2018 Debug_PVT_PEPS_P2_MaxRSSI 100;
BA_ "GenSigCycleTime" SG_ 2018 Debug_PVT_PEPS_P2_MaxRSSI 100;
BA_ "GenSigCycleTimeActive" SG_ 2018 Debug_PVT_PEPS_P1_MaxRSSI 100;
BA_ "GenSigCycleTime" SG_ 2018 Debug_PVT_PEPS_P1_MaxRSSI 100;
BA_ "GenSigCycleTime" SG_ 2017 Debug_PVT_Fob_Found 20;
BA_ "GenSigCycleTimeActive" SG_ 2017 Debug_PVT_PEPS_Fob_location 100;
BA_ "GenSigCycleTime" SG_ 2017 Debug_PVT_PEPS_Fob_location 100;
BA_ "GenSigCycleTime" SG_ 2017 Debug_PVT_PEPS_Logic_stat 100;
BA_ "GenSigCycleTimeActive" SG_ 2017 Debug_PVT_PEPS_Logic_stat 100;
BA_ "GenSigCycleTimeActive" SG_ 2017 Debug_PVT_PEPS_AntCtrl_stat 100;
BA_ "GenSigCycleTime" SG_ 2017 Debug_PVT_PEPS_AntCtrl_stat 100;
BA_ "GenSigCycleTimeActive" SG_ 2017 Debug_PVT_PEPS_TestPeriod_stat 100;
BA_ "GenSigCycleTime" SG_ 2017 Debug_PVT_PEPS_TestPeriod_stat 100;
BA_ "GenSigCycleTimeActive" SG_ 2017 Debug_PVT_PEPS_VDSI_stat 100;
BA_ "GenSigCycleTime" SG_ 2017 Debug_PVT_PEPS_VDSI_stat 100;
BA_ "GenSigCycleTime" SG_ 2017 Debug_PVT_PEPS_GainPi_stat 100;
BA_ "GenSigCycleTimeActive" SG_ 2017 Debug_PVT_PEPS_GainPi_stat 100;
BA_ "GenSigCycleTimeActive" SG_ 2017 Debug_PVT_PEPS_GainP4_stat 100;
BA_ "GenSigCycleTime" SG_ 2017 Debug_PVT_PEPS_GainP4_stat 100;
BA_ "GenSigCycleTimeActive" SG_ 2017 Debug_PVT_PEPS_GainP3_stat 100;
BA_ "GenSigCycleTime" SG_ 2017 Debug_PVT_PEPS_GainP3_stat 100;
BA_ "GenSigCycleTimeActive" SG_ 2017 Debug_PVT_PEPS_GainP2_stat 100;
BA_ "GenSigCycleTime" SG_ 2017 Debug_PVT_PEPS_GainP2_stat 100;
BA_ "GenSigCycleTimeActive" SG_ 2017 Debug_PVT_PEPS_GainP1_stat 100;
BA_ "GenSigCycleTime" SG_ 2017 Debug_PVT_PEPS_GainP1_stat 100;
BA_ "GenSigCycleTime" SG_ 2016 Debug_PVT_PEPS_D_AntP4ToFob 100;
BA_ "GenSigCycleTimeActive" SG_ 2016 Debug_PVT_PEPS_D_AntP4ToFob 100;
BA_ "GenSigCycleTimeActive" SG_ 2016 Debug_PVT_PEPS_D_AntP3ToFob 100;
BA_ "GenSigCycleTime" SG_ 2016 Debug_PVT_PEPS_D_AntP3ToFob 100;
BA_ "GenSigCycleTime" SG_ 2016 Debug_PVT_PEPS_D_AntP2ToFob 100;
BA_ "GenSigCycleTimeActive" SG_ 2016 Debug_PVT_PEPS_D_AntP2ToFob 100;
BA_ "GenSigCycleTime" SG_ 2016 Debug_PVT_PEPS_D_AntP1ToFob 100;
BA_ "GenSigCycleTimeActive" SG_ 2016 Debug_PVT_PEPS_D_AntP1ToFob 100;
BA_ "GenSigCycleTimeActive" SG_ 2016 Debug_PVT_PEPS_D_AntPiToFob 100;
BA_ "GenSigCycleTime" SG_ 2016 Debug_PVT_PEPS_D_AntPiToFob 100;
BA_ "GenSigCycleTimeActive" SG_ 2015 Debug_PVT_Fob_RF_RollingCounter 100;
BA_ "GenSigCycleTime" SG_ 2015 Debug_PVT_Fob_RF_RollingCounter 100;
BA_ "GenSigCycleTimeActive" SG_ 2015 Debug_PVT_SCIM_RF_RollingCounter 100;
BA_ "GenSigCycleTime" SG_ 2015 Debug_PVT_SCIM_RF_RollingCounter 100;
BA_ "GenSigCycleTimeActive" SG_ 2014 Debug_PVT_Fob_Select 100;
BA_ "GenSigCycleTime" SG_ 2014 Debug_PVT_Fob_Select 100;
BA_ "GenSigCycleTimeActive" SG_ 2012 Debug_PVT_Fob_ID 100;
BA_ "GenSigCycleTime" SG_ 2012 Debug_PVT_Fob_ID 100;
BA_ "GenSigCycleTimeActive" SG_ 2012 Debug_PVT_SCIM_RF_KeyfobSerialNb 100;
BA_ "GenSigCycleTime" SG_ 2012 Debug_PVT_SCIM_RF_KeyfobSerialNb 100;
BA_ "GenSigCycleTimeActive" SG_ 2011 Debug_PVT_SCIM_RD_WLS2_Volt 100;
BA_ "GenSigCycleTime" SG_ 2011 Debug_PVT_SCIM_RD_WLS2_Volt 100;
BA_ "GenSigCycleTimeActive" SG_ 2011 Debug_PVT_SCIM_RD_WLS2_Freq 100;
BA_ "GenSigCycleTime" SG_ 2011 Debug_PVT_SCIM_RD_WLS2_Freq 100;
BA_ "GenSigCycleTimeActive" SG_ 2011 Debug_PVT_SCIM_RD_WLS2_Duty 100;
BA_ "GenSigCycleTime" SG_ 2011 Debug_PVT_SCIM_RD_WLS2_Duty 100;
BA_ "GenSigCycleTimeActive" SG_ 2011 Debug_PVT_SCIM_RD_WLS2_Fault 100;
BA_ "GenSigCycleTime" SG_ 2011 Debug_PVT_SCIM_RD_WLS2_Fault 100;
BA_ "GenSigCycleTimeActive" SG_ 2011 Debug_PVT_SCIM_RD_WLS1_Volt 100;
BA_ "GenSigCycleTime" SG_ 2011 Debug_PVT_SCIM_RD_WLS1_Volt 100;
BA_ "GenSigCycleTimeActive" SG_ 2011 Debug_PVT_SCIM_RD_WLS1_Freq 100;
BA_ "GenSigCycleTime" SG_ 2011 Debug_PVT_SCIM_RD_WLS1_Freq 100;
BA_ "GenSigCycleTimeActive" SG_ 2011 Debug_PVT_SCIM_RD_WLS1_Duty 100;
BA_ "GenSigCycleTime" SG_ 2011 Debug_PVT_SCIM_RD_WLS1_Duty 100;
BA_ "GenSigCycleTimeActive" SG_ 2011 Debug_PVT_SCIM_RD_WLS1_Fault 100;
BA_ "GenSigCycleTime" SG_ 2011 Debug_PVT_SCIM_RD_WLS1_Fault 100;
BA_ "GenSigCycleTimeActive" SG_ 2010 Debug_PVT_SCIM_RD_WHS2_Duty 100;
BA_ "GenSigCycleTime" SG_ 2010 Debug_PVT_SCIM_RD_WHS2_Duty 100;
BA_ "GenSigCycleTime" SG_ 2010 Debug_PVT_SCIM_RD_WHS1_Duty 100;
BA_ "GenSigCycleTimeActive" SG_ 2010 Debug_PVT_SCIM_RD_WHS1_Duty 100;
BA_ "GenSigCycleTimeActive" SG_ 2010 Debug_PVT_SCIM_RD_WHS2_Volt 100;
BA_ "GenSigCycleTime" SG_ 2010 Debug_PVT_SCIM_RD_WHS2_Volt 100;
BA_ "GenSigCycleTimeActive" SG_ 2010 Debug_PVT_SCIM_RD_WHS1_Volt 100;
BA_ "GenSigCycleTime" SG_ 2010 Debug_PVT_SCIM_RD_WHS1_Volt 100;
BA_ "GenSigCycleTimeActive" SG_ 2010 Debug_PVT_SCIM_RD_WHS2_Fault 100;
BA_ "GenSigCycleTime" SG_ 2010 Debug_PVT_SCIM_RD_WHS2_Fault 100;
BA_ "GenSigCycleTimeActive" SG_ 2010 Debug_PVT_SCIM_RD_WHS2_Freq 100;
BA_ "GenSigCycleTime" SG_ 2010 Debug_PVT_SCIM_RD_WHS2_Freq 100;
BA_ "GenSigCycleTime" SG_ 2010 Debug_PVT_SCIM_RD_WHS1_Fault 100;
BA_ "GenSigCycleTimeActive" SG_ 2010 Debug_PVT_SCIM_RD_WHS1_Fault 100;
BA_ "GenSigCycleTime" SG_ 2010 Debug_PVT_SCIM_RD_WHS1_Freq 100;
BA_ "GenSigCycleTimeActive" SG_ 2010 Debug_PVT_SCIM_RD_WHS1_Freq 100;
BA_ "GenSigCycleTime" SG_ 2009 Debug_PVT_SCIM_RD_DAI2 100;
BA_ "GenSigCycleTimeActive" SG_ 2009 Debug_PVT_SCIM_RD_DAI2 100;
BA_ "GenSigCycleTime" SG_ 2009 Debug_PVT_SCIM_RD_DAI1 100;
BA_ "GenSigCycleTimeActive" SG_ 2009 Debug_PVT_SCIM_RD_DAI1 100;
BA_ "GenSigCycleTimeActive" SG_ 2009 Debug_PVT_SCIM_RD_WLS3_Volt 100;
BA_ "GenSigCycleTime" SG_ 2009 Debug_PVT_SCIM_RD_WLS3_Volt 100;
BA_ "GenSigCycleTimeActive" SG_ 2009 Debug_PVT_SCIM_RD_WLS3_Freq 100;
BA_ "GenSigCycleTime" SG_ 2009 Debug_PVT_SCIM_RD_WLS3_Freq 100;
BA_ "GenSigCycleTimeActive" SG_ 2009 Debug_PVT_SCIM_RD_WLS3_Duty 100;
BA_ "GenSigCycleTime" SG_ 2009 Debug_PVT_SCIM_RD_WLS3_Duty 100;
BA_ "GenSigCycleTimeActive" SG_ 2009 Debug_PVT_SCIM_RD_WLS3_Fault 100;
BA_ "GenSigCycleTime" SG_ 2009 Debug_PVT_SCIM_RD_WLS3_Fault 100;
BA_ "GenSigCycleTime" SG_ 2008 Debug_PVT_SCIM_RD_ADI08 100;
BA_ "GenSigCycleTimeActive" SG_ 2008 Debug_PVT_SCIM_RD_ADI08 100;
BA_ "GenSigCycleTime" SG_ 2008 Debug_PVT_SCIM_RD_ADI07 100;
BA_ "GenSigCycleTimeActive" SG_ 2008 Debug_PVT_SCIM_RD_ADI07 100;
BA_ "GenSigCycleTime" SG_ 2008 Debug_PVT_SCIM_RD_ADI12 100;
BA_ "GenSigCycleTimeActive" SG_ 2008 Debug_PVT_SCIM_RD_ADI12 100;
BA_ "GenSigCycleTime" SG_ 2008 Debug_PVT_SCIM_RD_ADI11 100;
BA_ "GenSigCycleTimeActive" SG_ 2008 Debug_PVT_SCIM_RD_ADI11 100;
BA_ "GenSigCycleTime" SG_ 2008 Debug_PVT_SCIM_RD_ADI10 100;
BA_ "GenSigCycleTimeActive" SG_ 2008 Debug_PVT_SCIM_RD_ADI10 100;
BA_ "GenSigCycleTime" SG_ 2008 Debug_PVT_SCIM_RD_ADI09 100;
BA_ "GenSigCycleTimeActive" SG_ 2008 Debug_PVT_SCIM_RD_ADI09 100;
BA_ "GenSigCycleTimeActive" SG_ 2007 Debug_PVT_SCIM_RD_ADI06 100;
BA_ "GenSigCycleTime" SG_ 2007 Debug_PVT_SCIM_RD_ADI06 100;
BA_ "GenSigCycleTime" SG_ 2007 Debug_PVT_SCIM_RD_ADI05 100;
BA_ "GenSigCycleTimeActive" SG_ 2007 Debug_PVT_SCIM_RD_ADI05 100;
BA_ "GenSigCycleTime" SG_ 2007 Debug_PVT_SCIM_RD_ADI04 100;
BA_ "GenSigCycleTimeActive" SG_ 2007 Debug_PVT_SCIM_RD_ADI04 100;
BA_ "GenSigCycleTimeActive" SG_ 2007 Debug_PVT_SCIM_RD_ADI03 100;
BA_ "GenSigCycleTime" SG_ 2007 Debug_PVT_SCIM_RD_ADI03 100;
BA_ "GenSigCycleTimeActive" SG_ 2007 Debug_PVT_SCIM_RD_ADI02 100;
BA_ "GenSigCycleTime" SG_ 2007 Debug_PVT_SCIM_RD_ADI02 100;
BA_ "GenSigCycleTimeActive" SG_ 2007 Debug_PVT_SCIM_RD_ADI01 100;
BA_ "GenSigCycleTime" SG_ 2007 Debug_PVT_SCIM_RD_ADI01 100;
BA_ "GenSigCycleTime" SG_ 2147484948 CalLoadTruckFrontAxle2_ISig_4 100;
BA_ "GenSigCycleTimeActive" SG_ 2147484948 CalLoadTruckFrontAxle2_ISig_4 100;
BA_ "GenSigStartValue" SG_ 2147484948 CalLoadTruckFrontAxle2_ISig_4 65535;
BA_ "GenSigCycleTime" SG_ 2147484948 CalLoadTrailer1Axle1_ISig_4 100;
BA_ "GenSigCycleTimeActive" SG_ 2147484948 CalLoadTrailer1Axle1_ISig_4 100;
BA_ "GenSigStartValue" SG_ 2147484948 CalLoadTrailer1Axle1_ISig_4 65535;
BA_ "GenSigCycleTime" SG_ 2147484948 CalLoadTrailer2Axle6_ISig_4 100;
BA_ "GenSigCycleTimeActive" SG_ 2147484948 CalLoadTrailer2Axle6_ISig_4 100;
BA_ "GenSigStartValue" SG_ 2147484948 CalLoadTrailer2Axle6_ISig_4 65535;
BA_ "GenSigCycleTime" SG_ 2147484948 CalLoadTrailer4Axle4_ISig_4 100;
BA_ "GenSigCycleTimeActive" SG_ 2147484948 CalLoadTrailer4Axle4_ISig_4 100;
BA_ "GenSigStartValue" SG_ 2147484948 CalLoadTrailer4Axle4_ISig_4 65535;
BA_ "GenSigCycleTime" SG_ 2147484947 CalLoadTrailer5Axle1_ISig_4 100;
BA_ "GenSigCycleTimeActive" SG_ 2147484947 CalLoadTrailer5Axle1_ISig_4 100;
BA_ "GenSigStartValue" SG_ 2147484947 CalLoadTrailer5Axle1_ISig_4 65535;
BA_ "GenSigCycleTime" SG_ 2147484947 CalLoadTrailer3Axle1_ISig_4 100;
BA_ "GenSigCycleTimeActive" SG_ 2147484947 CalLoadTrailer3Axle1_ISig_4 100;
BA_ "GenSigStartValue" SG_ 2147484947 CalLoadTrailer3Axle1_ISig_4 65535;
BA_ "GenSigCycleTime" SG_ 2147484947 CalLoadTrailer5Axle5_ISig_4 100;
BA_ "GenSigCycleTimeActive" SG_ 2147484947 CalLoadTrailer5Axle5_ISig_4 100;
BA_ "GenSigStartValue" SG_ 2147484947 CalLoadTrailer5Axle5_ISig_4 65535;
BA_ "GenSigCycleTime" SG_ 2147484947 CalLoadTrailer5Axle4_ISig_4 100;
BA_ "GenSigCycleTimeActive" SG_ 2147484947 CalLoadTrailer5Axle4_ISig_4 100;
BA_ "GenSigStartValue" SG_ 2147484947 CalLoadTrailer5Axle4_ISig_4 65535;
BA_ "GenSigCycleTime" SG_ 2147484946 VehCombHeaviestBoogie_VehicleID 100;
BA_ "GenSigCycleTimeActive" SG_ 2147484946 VehCombHeaviestBoogie_VehicleID 100;
BA_ "GenSigStartValue" SG_ 2147484946 VehCombHeaviestBoogie_VehicleID 7;
BA_ "GenSigMaxLatency" SG_ 2147484946 VehCombHeaviestBoogie_VehicleID 1000;
BA_ "GenSigCycleTime" SG_ 2147484946 VehCombHeaviestBoogie_Load 100;
BA_ "GenSigCycleTimeActive" SG_ 2147484946 VehCombHeaviestBoogie_Load 100;
BA_ "GenSigStartValue" SG_ 2147484946 VehCombHeaviestBoogie_Load 65535;
BA_ "GenSigMaxLatency" SG_ 2147484946 VehCombHeaviestBoogie_Load 1000;
BA_ "GenSigCycleTime" SG_ 2147484946 VehCombHeaviestBoogie_Position 100;
BA_ "GenSigCycleTimeActive" SG_ 2147484946 VehCombHeaviestBoogie_Position 100;
BA_ "GenSigStartValue" SG_ 2147484946 VehCombHeaviestBoogie_Position 3;
BA_ "GenSigMaxLatency" SG_ 2147484946 VehCombHeaviestBoogie_Position 1000;
BA_ "GenSigCycleTime" SG_ 2147484946 VehCombHeaviestAxle_Position 100;
BA_ "GenSigCycleTimeActive" SG_ 2147484946 VehCombHeaviestAxle_Position 100;
BA_ "GenSigStartValue" SG_ 2147484946 VehCombHeaviestAxle_Position 15;
BA_ "GenSigMaxLatency" SG_ 2147484946 VehCombHeaviestAxle_Position 1000;
BA_ "GenSigCycleTime" SG_ 2147484946 VehCombHeaviestAxle_Load 100;
BA_ "GenSigCycleTimeActive" SG_ 2147484946 VehCombHeaviestAxle_Load 100;
BA_ "GenSigStartValue" SG_ 2147484946 VehCombHeaviestAxle_Load 65535;
BA_ "GenSigMaxLatency" SG_ 2147484946 VehCombHeaviestAxle_Load 1000;
BA_ "GenSigCycleTime" SG_ 2147484946 VehCombHeaviestAxle_VehicleID 100;
BA_ "GenSigCycleTimeActive" SG_ 2147484946 VehCombHeaviestAxle_VehicleID 100;
BA_ "GenSigStartValue" SG_ 2147484946 VehCombHeaviestAxle_VehicleID 7;
BA_ "GenSigMaxLatency" SG_ 2147484946 VehCombHeaviestAxle_VehicleID 1000;
BA_ "GenSigCycleTime" SG_ 2147484945 CalLoadTrailer5Axle3_ISig_4 100;
BA_ "GenSigCycleTimeActive" SG_ 2147484945 CalLoadTrailer5Axle3_ISig_4 100;
BA_ "GenSigStartValue" SG_ 2147484945 CalLoadTrailer5Axle3_ISig_4 65535;
BA_ "GenSigCycleTime" SG_ 2147484945 CalLoadTrailer4Axle1_ISig_4 100;
BA_ "GenSigCycleTimeActive" SG_ 2147484945 CalLoadTrailer4Axle1_ISig_4 100;
BA_ "GenSigStartValue" SG_ 2147484945 CalLoadTrailer4Axle1_ISig_4 65535;
BA_ "GenSigCycleTime" SG_ 2147484945 CalLoadTrailer2Axle5_ISig_4 100;
BA_ "GenSigCycleTimeActive" SG_ 2147484945 CalLoadTrailer2Axle5_ISig_4 100;
BA_ "GenSigStartValue" SG_ 2147484945 CalLoadTrailer2Axle5_ISig_4 65535;
BA_ "GenSigCycleTime" SG_ 2147484945 CalLoadTrailer3Axle3_ISig_4 100;
BA_ "GenSigCycleTimeActive" SG_ 2147484945 CalLoadTrailer3Axle3_ISig_4 100;
BA_ "GenSigStartValue" SG_ 2147484945 CalLoadTrailer3Axle3_ISig_4 65535;
BA_ "GenSigCycleTime" SG_ 2147484944 CalLoadTrailer1Axle3_ISig_4 100;
BA_ "GenSigCycleTimeActive" SG_ 2147484944 CalLoadTrailer1Axle3_ISig_4 100;
BA_ "GenSigStartValue" SG_ 2147484944 CalLoadTrailer1Axle3_ISig_4 65535;
BA_ "GenSigCycleTime" SG_ 2147484944 CalLoadTrailer4Axle5_ISig_4 100;
BA_ "GenSigCycleTimeActive" SG_ 2147484944 CalLoadTrailer4Axle5_ISig_4 100;
BA_ "GenSigStartValue" SG_ 2147484944 CalLoadTrailer4Axle5_ISig_4 65535;
BA_ "GenSigCycleTime" SG_ 2147484944 CalLoadTruckRearAxle1_ISig_4 100;
BA_ "GenSigCycleTimeActive" SG_ 2147484944 CalLoadTruckRearAxle1_ISig_4 100;
BA_ "GenSigStartValue" SG_ 2147484944 CalLoadTruckRearAxle1_ISig_4 65535;
BA_ "GenSigCycleTime" SG_ 2147484944 CalLoadTruckFrontAxle1_ISig_4 100;
BA_ "GenSigCycleTimeActive" SG_ 2147484944 CalLoadTruckFrontAxle1_ISig_4 100;
BA_ "GenSigStartValue" SG_ 2147484944 CalLoadTruckFrontAxle1_ISig_4 65535;
BA_ "GenSigCycleTime" SG_ 2147485038 TruckFrontAxle2_Liftable 100;
BA_ "GenSigCycleTimeActive" SG_ 2147485038 TruckFrontAxle2_Liftable 100;
BA_ "GenSigCycleTime" SG_ 2147485038 TruckRearAxle3_Liftable 100;
BA_ "GenSigCycleTimeActive" SG_ 2147485038 TruckRearAxle3_Liftable 100;
BA_ "GenSigCycleTime" SG_ 2147485038 TruckRearAxle2_Liftable 100;
BA_ "GenSigCycleTimeActive" SG_ 2147485038 TruckRearAxle2_Liftable 100;
BA_ "GenSigCycleTime" SG_ 2147485038 TruckRearAxle2_Suspension 100;
BA_ "GenSigCycleTimeActive" SG_ 2147485038 TruckRearAxle2_Suspension 100;
BA_ "GenSigStartValue" SG_ 2147485038 TruckRearAxle2_Suspension 3;
BA_ "GenSigCycleTime" SG_ 2147485038 TruckFrontAxle1_Liftable 100;
BA_ "GenSigCycleTimeActive" SG_ 2147485038 TruckFrontAxle1_Liftable 100;
BA_ "GenSigCycleTime" SG_ 2147485038 TruckRearAxle1_Driven 100;
BA_ "GenSigCycleTimeActive" SG_ 2147485038 TruckRearAxle1_Driven 100;
BA_ "GenSigCycleTime" SG_ 2147485038 TruckFrontAxle2_Driven 100;
BA_ "GenSigCycleTimeActive" SG_ 2147485038 TruckFrontAxle2_Driven 100;
BA_ "GenSigCycleTime" SG_ 2147485038 TruckRearAxle1_Suspension 100;
BA_ "GenSigCycleTimeActive" SG_ 2147485038 TruckRearAxle1_Suspension 100;
BA_ "GenSigStartValue" SG_ 2147485038 TruckRearAxle1_Suspension 3;
BA_ "GenSigCycleTime" SG_ 2147485038 TruckRearAxle2_Driven 100;
BA_ "GenSigCycleTimeActive" SG_ 2147485038 TruckRearAxle2_Driven 100;
BA_ "GenSigCycleTime" SG_ 2147485038 TruckFrontAxle2_Suspension 100;
BA_ "GenSigCycleTimeActive" SG_ 2147485038 TruckFrontAxle2_Suspension 100;
BA_ "GenSigStartValue" SG_ 2147485038 TruckFrontAxle2_Suspension 3;
BA_ "GenSigCycleTime" SG_ 2147485038 TruckRearAxle1_Liftable 100;
BA_ "GenSigCycleTimeActive" SG_ 2147485038 TruckRearAxle1_Liftable 100;
BA_ "GenSigCycleTime" SG_ 2147485038 TruckFrontAxle1_Suspension 100;
BA_ "GenSigCycleTimeActive" SG_ 2147485038 TruckFrontAxle1_Suspension 100;
BA_ "GenSigStartValue" SG_ 2147485038 TruckFrontAxle1_Suspension 3;
BA_ "GenSigCycleTime" SG_ 2147485038 TruckRearAxle3_Driven 100;
BA_ "GenSigCycleTimeActive" SG_ 2147485038 TruckRearAxle3_Driven 100;
BA_ "GenSigCycleTime" SG_ 2147485038 TruckFrontAxle1_Driven 100;
BA_ "GenSigCycleTimeActive" SG_ 2147485038 TruckFrontAxle1_Driven 100;
BA_ "GenSigCycleTime" SG_ 2147485038 TruckRearAxle3_Suspension 100;
BA_ "GenSigCycleTimeActive" SG_ 2147485038 TruckRearAxle3_Suspension 100;
BA_ "GenSigStartValue" SG_ 2147485038 TruckRearAxle3_Suspension 3;
BA_ "GenSigCycleTime" SG_ 2147485031 Trail2NoOfFrontAxles_ISig_4 100;
BA_ "GenSigCycleTimeActive" SG_ 2147485031 Trail2NoOfFrontAxles_ISig_4 100;
BA_ "GenSigStartValue" SG_ 2147485031 Trail2NoOfFrontAxles_ISig_4 15;
BA_ "GenSigCycleTime" SG_ 2147485031 Trail2NoOfAxles_ISig_4 100;
BA_ "GenSigCycleTimeActive" SG_ 2147485031 Trail2NoOfAxles_ISig_4 100;
BA_ "GenSigStartValue" SG_ 2147485031 Trail2NoOfAxles_ISig_4 15;
BA_ "GenSigCycleTime" SG_ 2147485031 Trail4NoOfFrontAxles_ISig_4 100;
BA_ "GenSigCycleTimeActive" SG_ 2147485031 Trail4NoOfFrontAxles_ISig_4 100;
BA_ "GenSigStartValue" SG_ 2147485031 Trail4NoOfFrontAxles_ISig_4 15;
BA_ "GenSigCycleTime" SG_ 2147485031 Trail1NoOfAxles_ISig_4 100;
BA_ "GenSigCycleTimeActive" SG_ 2147485031 Trail1NoOfAxles_ISig_4 100;
BA_ "GenSigStartValue" SG_ 2147485031 Trail1NoOfAxles_ISig_4 15;
BA_ "GenSigCycleTime" SG_ 2147485031 Trail3NoOfAxles_ISig_4 100;
BA_ "GenSigCycleTimeActive" SG_ 2147485031 Trail3NoOfAxles_ISig_4 100;
BA_ "GenSigStartValue" SG_ 2147485031 Trail3NoOfAxles_ISig_4 15;
BA_ "GenSigCycleTime" SG_ 2147485031 Trail4NoOfAxles_ISig_4 100;
BA_ "GenSigCycleTimeActive" SG_ 2147485031 Trail4NoOfAxles_ISig_4 100;
BA_ "GenSigStartValue" SG_ 2147485031 Trail4NoOfAxles_ISig_4 15;
BA_ "GenSigCycleTime" SG_ 2147485031 Trail1NoOfFrontAxles_ISig_4 100;
BA_ "GenSigCycleTimeActive" SG_ 2147485031 Trail1NoOfFrontAxles_ISig_4 100;
BA_ "GenSigStartValue" SG_ 2147485031 Trail1NoOfFrontAxles_ISig_4 15;
BA_ "GenSigCycleTime" SG_ 2147485031 Trail5NoOfFrontAxles_ISig_4 100;
BA_ "GenSigCycleTimeActive" SG_ 2147485031 Trail5NoOfFrontAxles_ISig_4 100;
BA_ "GenSigStartValue" SG_ 2147485031 Trail5NoOfFrontAxles_ISig_4 15;
BA_ "GenSigCycleTime" SG_ 2147485031 Trail5NoOfAxles_ISig_4 100;
BA_ "GenSigCycleTimeActive" SG_ 2147485031 Trail5NoOfAxles_ISig_4 100;
BA_ "GenSigStartValue" SG_ 2147485031 Trail5NoOfAxles_ISig_4 15;
BA_ "GenSigCycleTime" SG_ 2147485031 Trail3NoOfFrontAxles_ISig_4 100;
BA_ "GenSigCycleTimeActive" SG_ 2147485031 Trail3NoOfFrontAxles_ISig_4 100;
BA_ "GenSigStartValue" SG_ 2147485031 Trail3NoOfFrontAxles_ISig_4 15;
BA_ "GenSigCycleTime" SG_ 2147485028 Trail3Type_TrailType_ISig_4 100;
BA_ "GenSigCycleTimeActive" SG_ 2147485028 Trail3Type_TrailType_ISig_4 100;
BA_ "GenSigStartValue" SG_ 2147485028 Trail3Type_TrailType_ISig_4 7;
BA_ "GenSigCycleTime" SG_ 2147485028 Trail5Axle1Type_ISig_4 100;
BA_ "GenSigCycleTimeActive" SG_ 2147485028 Trail5Axle1Type_ISig_4 100;
BA_ "GenSigStartValue" SG_ 2147485028 Trail5Axle1Type_ISig_4 3;
BA_ "GenSigCycleTime" SG_ 2147485028 Trail3Type_Towing_ISig_4 100;
BA_ "GenSigCycleTimeActive" SG_ 2147485028 Trail3Type_Towing_ISig_4 100;
BA_ "GenSigCycleTime" SG_ 2147485028 Trail5Axle4Type_ISig_4 100;
BA_ "GenSigCycleTimeActive" SG_ 2147485028 Trail5Axle4Type_ISig_4 100;
BA_ "GenSigStartValue" SG_ 2147485028 Trail5Axle4Type_ISig_4 3;
BA_ "GenSigCycleTime" SG_ 2147485028 Trail5Axle3Type_ISig_4 100;
BA_ "GenSigCycleTimeActive" SG_ 2147485028 Trail5Axle3Type_ISig_4 100;
BA_ "GenSigStartValue" SG_ 2147485028 Trail5Axle3Type_ISig_4 3;
BA_ "GenSigCycleTime" SG_ 2147485028 Trail4Type_Towing_ISig_4 100;
BA_ "GenSigCycleTimeActive" SG_ 2147485028 Trail4Type_Towing_ISig_4 100;
BA_ "GenSigCycleTime" SG_ 2147485028 Trail4Type_TrailType_ISig_4 100;
BA_ "GenSigCycleTimeActive" SG_ 2147485028 Trail4Type_TrailType_ISig_4 100;
BA_ "GenSigStartValue" SG_ 2147485028 Trail4Type_TrailType_ISig_4 7;
BA_ "GenSigCycleTime" SG_ 2147485028 Trail5Axle2Type_ISig_4 100;
BA_ "GenSigCycleTimeActive" SG_ 2147485028 Trail5Axle2Type_ISig_4 100;
BA_ "GenSigStartValue" SG_ 2147485028 Trail5Axle2Type_ISig_4 3;
BA_ "GenSigCycleTime" SG_ 2147485028 Trail5Type_TrailType_ISig_4 100;
BA_ "GenSigCycleTimeActive" SG_ 2147485028 Trail5Type_TrailType_ISig_4 100;
BA_ "GenSigStartValue" SG_ 2147485028 Trail5Type_TrailType_ISig_4 7;
BA_ "GenSigCycleTime" SG_ 2147485028 Trail5Axle5Type_ISig_4 100;
BA_ "GenSigCycleTimeActive" SG_ 2147485028 Trail5Axle5Type_ISig_4 100;
BA_ "GenSigStartValue" SG_ 2147485028 Trail5Axle5Type_ISig_4 3;
BA_ "GenSigCycleTime" SG_ 2147485028 Trail5Type_Towing_ISig_4 100;
BA_ "GenSigCycleTimeActive" SG_ 2147485028 Trail5Type_Towing_ISig_4 100;
BA_ "GenSigCycleTime" SG_ 2147485028 Trail5Axle6Type_ISig_4 100;
BA_ "GenSigCycleTimeActive" SG_ 2147485028 Trail5Axle6Type_ISig_4 100;
BA_ "GenSigStartValue" SG_ 2147485028 Trail5Axle6Type_ISig_4 3;
BA_ "GenSigCycleTime" SG_ 2147485026 Trail2Axle4Type_ISig_4 100;
BA_ "GenSigCycleTimeActive" SG_ 2147485026 Trail2Axle4Type_ISig_4 100;
BA_ "GenSigStartValue" SG_ 2147485026 Trail2Axle4Type_ISig_4 3;
BA_ "GenSigCycleTime" SG_ 2147485026 Trail4Axle1Type_ISig_4 100;
BA_ "GenSigCycleTimeActive" SG_ 2147485026 Trail4Axle1Type_ISig_4 100;
BA_ "GenSigStartValue" SG_ 2147485026 Trail4Axle1Type_ISig_4 3;
BA_ "GenSigCycleTime" SG_ 2147485026 Trail2Axle3Type_ISig_4 100;
BA_ "GenSigCycleTimeActive" SG_ 2147485026 Trail2Axle3Type_ISig_4 100;
BA_ "GenSigStartValue" SG_ 2147485026 Trail2Axle3Type_ISig_4 3;
BA_ "GenSigCycleTime" SG_ 2147485026 Trail1Axle6Type_ISig_4 100;
BA_ "GenSigCycleTimeActive" SG_ 2147485026 Trail1Axle6Type_ISig_4 100;
BA_ "GenSigStartValue" SG_ 2147485026 Trail1Axle6Type_ISig_4 3;
BA_ "GenSigCycleTime" SG_ 2147485026 Trail1Type_Towing_ISig_4 100;
BA_ "GenSigCycleTimeActive" SG_ 2147485026 Trail1Type_Towing_ISig_4 100;
BA_ "GenSigCycleTime" SG_ 2147485026 Trail3Axle5Type_ISig_4 100;
BA_ "GenSigCycleTimeActive" SG_ 2147485026 Trail3Axle5Type_ISig_4 100;
BA_ "GenSigStartValue" SG_ 2147485026 Trail3Axle5Type_ISig_4 3;
BA_ "GenSigCycleTime" SG_ 2147485026 Trail1Axle5Type_ISig_4 100;
BA_ "GenSigCycleTimeActive" SG_ 2147485026 Trail1Axle5Type_ISig_4 100;
BA_ "GenSigStartValue" SG_ 2147485026 Trail1Axle5Type_ISig_4 3;
BA_ "GenSigCycleTime" SG_ 2147485026 Trail3Axle4Type_ISig_4 100;
BA_ "GenSigCycleTimeActive" SG_ 2147485026 Trail3Axle4Type_ISig_4 100;
BA_ "GenSigStartValue" SG_ 2147485026 Trail3Axle4Type_ISig_4 3;
BA_ "GenSigCycleTime" SG_ 2147485026 Trail4Axle4Type_ISig_4 100;
BA_ "GenSigCycleTimeActive" SG_ 2147485026 Trail4Axle4Type_ISig_4 100;
BA_ "GenSigStartValue" SG_ 2147485026 Trail4Axle4Type_ISig_4 3;
BA_ "GenSigCycleTime" SG_ 2147485026 Trail4Axle3Type_ISig_4 100;
BA_ "GenSigCycleTimeActive" SG_ 2147485026 Trail4Axle3Type_ISig_4 100;
BA_ "GenSigStartValue" SG_ 2147485026 Trail4Axle3Type_ISig_4 3;
BA_ "GenSigCycleTime" SG_ 2147485026 Trail4Axle2Type_ISig_4 100;
BA_ "GenSigCycleTimeActive" SG_ 2147485026 Trail4Axle2Type_ISig_4 100;
BA_ "GenSigStartValue" SG_ 2147485026 Trail4Axle2Type_ISig_4 3;
BA_ "GenSigCycleTime" SG_ 2147485026 Trail1Axle4Type_ISig_4 100;
BA_ "GenSigCycleTimeActive" SG_ 2147485026 Trail1Axle4Type_ISig_4 100;
BA_ "GenSigStartValue" SG_ 2147485026 Trail1Axle4Type_ISig_4 3;
BA_ "GenSigCycleTime" SG_ 2147485026 Trail1Axle1Type_ISig_4 100;
BA_ "GenSigCycleTimeActive" SG_ 2147485026 Trail1Axle1Type_ISig_4 100;
BA_ "GenSigStartValue" SG_ 2147485026 Trail1Axle1Type_ISig_4 3;
BA_ "GenSigCycleTime" SG_ 2147485026 Trail1Type_TrailType_ISig_4 100;
BA_ "GenSigCycleTimeActive" SG_ 2147485026 Trail1Type_TrailType_ISig_4 100;
BA_ "GenSigStartValue" SG_ 2147485026 Trail1Type_TrailType_ISig_4 7;
BA_ "GenSigCycleTime" SG_ 2147485026 Trail2Type_Towing_ISig_4 100;
BA_ "GenSigCycleTimeActive" SG_ 2147485026 Trail2Type_Towing_ISig_4 100;
BA_ "GenSigCycleTime" SG_ 2147485026 Trail2Axle1Type_ISig_4 100;
BA_ "GenSigCycleTimeActive" SG_ 2147485026 Trail2Axle1Type_ISig_4 100;
BA_ "GenSigStartValue" SG_ 2147485026 Trail2Axle1Type_ISig_4 3;
BA_ "GenSigCycleTime" SG_ 2147485026 Trail3Axle3Type_ISig_4 100;
BA_ "GenSigCycleTimeActive" SG_ 2147485026 Trail3Axle3Type_ISig_4 100;
BA_ "GenSigStartValue" SG_ 2147485026 Trail3Axle3Type_ISig_4 3;
BA_ "GenSigCycleTime" SG_ 2147485026 Trail3Axle1Type_ISig_4 100;
BA_ "GenSigCycleTimeActive" SG_ 2147485026 Trail3Axle1Type_ISig_4 100;
BA_ "GenSigStartValue" SG_ 2147485026 Trail3Axle1Type_ISig_4 3;
BA_ "GenSigCycleTime" SG_ 2147485026 Trail4Axle5Type_ISig_4 100;
BA_ "GenSigCycleTimeActive" SG_ 2147485026 Trail4Axle5Type_ISig_4 100;
BA_ "GenSigStartValue" SG_ 2147485026 Trail4Axle5Type_ISig_4 3;
BA_ "GenSigCycleTime" SG_ 2147485026 Trail1Axle3Type_ISig_4 100;
BA_ "GenSigCycleTimeActive" SG_ 2147485026 Trail1Axle3Type_ISig_4 100;
BA_ "GenSigStartValue" SG_ 2147485026 Trail1Axle3Type_ISig_4 3;
BA_ "GenSigCycleTime" SG_ 2147485026 Trail2Type_TrailType_ISig_4 100;
BA_ "GenSigCycleTimeActive" SG_ 2147485026 Trail2Type_TrailType_ISig_4 100;
BA_ "GenSigStartValue" SG_ 2147485026 Trail2Type_TrailType_ISig_4 7;
BA_ "GenSigCycleTime" SG_ 2147485026 Trail3Axle2Type_ISig_4 100;
BA_ "GenSigCycleTimeActive" SG_ 2147485026 Trail3Axle2Type_ISig_4 100;
BA_ "GenSigStartValue" SG_ 2147485026 Trail3Axle2Type_ISig_4 3;
BA_ "GenSigCycleTime" SG_ 2147485026 Trail4Axle6Type_ISig_4 100;
BA_ "GenSigCycleTimeActive" SG_ 2147485026 Trail4Axle6Type_ISig_4 100;
BA_ "GenSigStartValue" SG_ 2147485026 Trail4Axle6Type_ISig_4 3;
BA_ "GenSigCycleTime" SG_ 2147485026 Trail2Axle5Type_ISig_4 100;
BA_ "GenSigCycleTimeActive" SG_ 2147485026 Trail2Axle5Type_ISig_4 100;
BA_ "GenSigStartValue" SG_ 2147485026 Trail2Axle5Type_ISig_4 3;
BA_ "GenSigCycleTime" SG_ 2147485026 Trail2Axle6Type_ISig_4 100;
BA_ "GenSigCycleTimeActive" SG_ 2147485026 Trail2Axle6Type_ISig_4 100;
BA_ "GenSigStartValue" SG_ 2147485026 Trail2Axle6Type_ISig_4 3;
BA_ "GenSigCycleTime" SG_ 2147485026 Trail3Axle6Type_ISig_4 100;
BA_ "GenSigCycleTimeActive" SG_ 2147485026 Trail3Axle6Type_ISig_4 100;
BA_ "GenSigStartValue" SG_ 2147485026 Trail3Axle6Type_ISig_4 3;
BA_ "GenSigCycleTime" SG_ 2147485026 Trail1Axle2Type_ISig_4 100;
BA_ "GenSigCycleTimeActive" SG_ 2147485026 Trail1Axle2Type_ISig_4 100;
BA_ "GenSigStartValue" SG_ 2147485026 Trail1Axle2Type_ISig_4 3;
BA_ "GenSigCycleTime" SG_ 2147485026 Trail2Axle2Type_ISig_4 100;
BA_ "GenSigCycleTimeActive" SG_ 2147485026 Trail2Axle2Type_ISig_4 100;
BA_ "GenSigStartValue" SG_ 2147485026 Trail2Axle2Type_ISig_4 3;
BA_ "GenSigCycleTime" SG_ 2147484291 RelCargoLoadTrailer1_ISig_4 100;
BA_ "GenSigCycleTimeActive" SG_ 2147484291 RelCargoLoadTrailer1_ISig_4 100;
BA_ "GenSigStartValue" SG_ 2147484291 RelCargoLoadTrailer1_ISig_4 65535;
BA_ "GenSigCycleTime" SG_ 2147484291 RelCargoLoadTrailer5_ISig_4 100;
BA_ "GenSigCycleTimeActive" SG_ 2147484291 RelCargoLoadTrailer5_ISig_4 100;
BA_ "GenSigStartValue" SG_ 2147484291 RelCargoLoadTrailer5_ISig_4 65535;
BA_ "GenSigCycleTime" SG_ 2147484181 TotalCargoLoadTrailer4 100;
BA_ "GenSigCycleTimeActive" SG_ 2147484181 TotalCargoLoadTrailer4 100;
BA_ "GenSigStartValue" SG_ 2147484181 TotalCargoLoadTrailer4 65535;
BA_ "GenSigCycleTime" SG_ 2147484181 TotalCargoLoadTruck 100;
BA_ "GenSigCycleTimeActive" SG_ 2147484181 TotalCargoLoadTruck 100;
BA_ "GenSigStartValue" SG_ 2147484181 TotalCargoLoadTruck 65535;
BA_ "GenSigCycleTime" SG_ 2147484181 TotalCargoLoadTrailer3 100;
BA_ "GenSigCycleTimeActive" SG_ 2147484181 TotalCargoLoadTrailer3 100;
BA_ "GenSigStartValue" SG_ 2147484181 TotalCargoLoadTrailer3 65535;
BA_ "GenSigCycleTime" SG_ 2147484181 RelCargoLoadTrailer4_ISig_4 100;
BA_ "GenSigCycleTimeActive" SG_ 2147484181 RelCargoLoadTrailer4_ISig_4 100;
BA_ "GenSigStartValue" SG_ 2147484181 RelCargoLoadTrailer4_ISig_4 65535;
BA_ "GenSigCycleTime" SG_ 2147484069 TotalCargoLoadTrailer2 100;
BA_ "GenSigCycleTimeActive" SG_ 2147484069 TotalCargoLoadTrailer2 100;
BA_ "GenSigStartValue" SG_ 2147484069 TotalCargoLoadTrailer2 65535;
BA_ "GenSigCycleTime" SG_ 2147484069 TotalCargoLoadTrailer5 100;
BA_ "GenSigCycleTimeActive" SG_ 2147484069 TotalCargoLoadTrailer5 100;
BA_ "GenSigStartValue" SG_ 2147484069 TotalCargoLoadTrailer5 65535;
BA_ "GenSigCycleTime" SG_ 2147484069 TotalCargoLoadTrailer1 100;
BA_ "GenSigCycleTimeActive" SG_ 2147484069 TotalCargoLoadTrailer1 100;
BA_ "GenSigStartValue" SG_ 2147484069 TotalCargoLoadTrailer1 65535;
BA_ "GenSigCycleTime" SG_ 2147484069 RelCargoLoadTruck_ISig_4 100;
BA_ "GenSigCycleTimeActive" SG_ 2147484069 RelCargoLoadTruck_ISig_4 100;
BA_ "GenSigStartValue" SG_ 2147484069 RelCargoLoadTruck_ISig_4 65535;
BA_ "GenSigCycleTime" SG_ 2147483971 LoadTrailer5_ISig_4 100;
BA_ "GenSigCycleTimeActive" SG_ 2147483971 LoadTrailer5_ISig_4 100;
BA_ "GenSigStartValue" SG_ 2147483971 LoadTrailer5_ISig_4 65535;
BA_ "GenSigCycleTime" SG_ 2147483971 LoadTrailer4Back 100;
BA_ "GenSigCycleTimeActive" SG_ 2147483971 LoadTrailer4Back 100;
BA_ "GenSigStartValue" SG_ 2147483971 LoadTrailer4Back 65535;
BA_ "GenSigCycleTime" SG_ 2147483971 LoadTrailer2Front 100;
BA_ "GenSigCycleTimeActive" SG_ 2147483971 LoadTrailer2Front 100;
BA_ "GenSigStartValue" SG_ 2147483971 LoadTrailer2Front 65535;
BA_ "GenSigCycleTime" SG_ 2147483958 TruckType 100;
BA_ "GenSigCycleTimeActive" SG_ 2147483958 TruckType 100;
BA_ "GenSigStartValue" SG_ 2147483958 TruckType 3;
BA_ "GenSigCycleTime" SG_ 2147483958 RelCargoLoadTrailer2_ISig_4 100;
BA_ "GenSigCycleTimeActive" SG_ 2147483958 RelCargoLoadTrailer2_ISig_4 100;
BA_ "GenSigStartValue" SG_ 2147483958 RelCargoLoadTrailer2_ISig_4 65535;
BA_ "GenSigCycleTime" SG_ 2147483958 RelCargoLoadTrailer3_ISig_4 100;
BA_ "GenSigCycleTimeActive" SG_ 2147483958 RelCargoLoadTrailer3_ISig_4 100;
BA_ "GenSigStartValue" SG_ 2147483958 RelCargoLoadTrailer3_ISig_4 65535;
BA_ "GenSigCycleTime" SG_ 2147483958 TruckNoOfFrontAxles 100;
BA_ "GenSigCycleTimeActive" SG_ 2147483958 TruckNoOfFrontAxles 100;
BA_ "GenSigStartValue" SG_ 2147483958 TruckNoOfFrontAxles 15;
BA_ "GenSigCycleTime" SG_ 2147483958 MainBeamLEDStatusLeft_ISig_4 100;
BA_ "GenSigCycleTimeActive" SG_ 2147483958 MainBeamLEDStatusLeft_ISig_4 100;
BA_ "GenSigStartValue" SG_ 2147483958 MainBeamLEDStatusLeft_ISig_4 7;
BA_ "GenSigCycleTime" SG_ 2147483958 MainBeamLEDStatusRight_ISig_4 100;
BA_ "GenSigCycleTimeActive" SG_ 2147483958 MainBeamLEDStatusRight_ISig_4 100;
BA_ "GenSigStartValue" SG_ 2147483958 MainBeamLEDStatusRight_ISig_4 7;
BA_ "GenSigCycleTime" SG_ 2147483958 TruckNoOfAxles 100;
BA_ "GenSigCycleTimeActive" SG_ 2147483958 TruckNoOfAxles 100;
BA_ "GenSigStartValue" SG_ 2147483958 TruckNoOfAxles 15;
BA_ "GenSigCycleTime" SG_ 2147485015 DistanceToEmptyLNG_ISig_4 100;
BA_ "GenSigCycleTimeActive" SG_ 2147485015 DistanceToEmptyLNG_ISig_4 100;
BA_ "GenSigStartValue" SG_ 2147485015 DistanceToEmptyLNG_ISig_4 65535;
BA_ "GenSigMaxLatency" SG_ 2147485015 DistanceToEmptyLNG_ISig_4 1000;
BA_ "GenSigCycleTime" SG_ 2147485015 DistanceToEmpty_Diesel_ISig_4 100;
BA_ "GenSigCycleTimeActive" SG_ 2147485015 DistanceToEmpty_Diesel_ISig_4 100;
BA_ "GenSigStartValue" SG_ 2147485015 DistanceToEmpty_Diesel_ISig_4 65535;
BA_ "GenSigMaxLatency" SG_ 2147485015 DistanceToEmpty_Diesel_ISig_4 1000;
BA_ "GenSigCycleTime" SG_ 2147485015 FuelLostInIdle 100;
BA_ "GenSigCycleTimeActive" SG_ 2147485015 FuelLostInIdle 100;
BA_ "GenSigStartValue" SG_ 2147485015 FuelLostInIdle 4294967295;
BA_ "GenSigMaxLatency" SG_ 2147485015 FuelLostInIdle 1000;
BA_ "GenSigCycleTime" SG_ 2147485016 FuelLostInOverAccel 100;
BA_ "GenSigCycleTimeActive" SG_ 2147485016 FuelLostInOverAccel 100;
BA_ "GenSigStartValue" SG_ 2147485016 FuelLostInOverAccel 4294967295;
BA_ "GenSigMaxLatency" SG_ 2147485016 FuelLostInOverAccel 1000;
BA_ "GenSigCycleTime" SG_ 2147485016 FuelLostInOverSpd 100;
BA_ "GenSigCycleTimeActive" SG_ 2147485016 FuelLostInOverSpd 100;
BA_ "GenSigStartValue" SG_ 2147485016 FuelLostInOverSpd 4294967295;
BA_ "GenSigMaxLatency" SG_ 2147485016 FuelLostInOverSpd 1000;
BA_ "GenSigCycleTime" SG_ 2147485018 FrontConspicLamp_stat_HiLeft_ISi 100;
BA_ "GenSigCycleTimeActive" SG_ 2147485018 FrontConspicLamp_stat_HiLeft_ISi 100;
BA_ "GenSigStartValue" SG_ 2147485018 FrontConspicLamp_stat_HiLeft_ISi 7;
BA_ "GenSigMaxLatency" SG_ 2147485018 FrontConspicLamp_stat_HiLeft_ISi 259;
BA_ "SystemSignalLongSymbol" SG_ 2147485018 FrontConspicLamp_stat_HiLeft_ISi "FrontConspicLamp_stat_HiLeft_ISig_4";
BA_ "GenSigCycleTime" SG_ 2147485018 TrailerDirIndLeftOutputStat_ISig 100;
BA_ "GenSigCycleTimeActive" SG_ 2147485018 TrailerDirIndLeftOutputStat_ISig 100;
BA_ "GenSigStartValue" SG_ 2147485018 TrailerDirIndLeftOutputStat_ISig 7;
BA_ "SystemSignalLongSymbol" SG_ 2147485018 TrailerDirIndLeftOutputStat_ISig "TrailerDirIndLeftOutputStat_ISig_4";
BA_ "GenSigCycleTime" SG_ 2147485018 TrailerPosLightLeftOutputStat_IS 100;
BA_ "GenSigCycleTimeActive" SG_ 2147485018 TrailerPosLightLeftOutputStat_IS 100;
BA_ "GenSigStartValue" SG_ 2147485018 TrailerPosLightLeftOutputStat_IS 7;
BA_ "SystemSignalLongSymbol" SG_ 2147485018 TrailerPosLightLeftOutputStat_IS "TrailerPosLightLeftOutputStat_ISig_4";
BA_ "GenSigCycleTime" SG_ 2147485018 TrailerBrakeLightOutputStat_ISig 100;
BA_ "GenSigCycleTimeActive" SG_ 2147485018 TrailerBrakeLightOutputStat_ISig 100;
BA_ "GenSigStartValue" SG_ 2147485018 TrailerBrakeLightOutputStat_ISig 7;
BA_ "SystemSignalLongSymbol" SG_ 2147485018 TrailerBrakeLightOutputStat_ISig "TrailerBrakeLightOutputStat_ISig_4";
BA_ "GenSigCycleTime" SG_ 2147485018 FrontConspicLamp_stat_LoRight_IS 100;
BA_ "GenSigCycleTimeActive" SG_ 2147485018 FrontConspicLamp_stat_LoRight_IS 100;
BA_ "GenSigStartValue" SG_ 2147485018 FrontConspicLamp_stat_LoRight_IS 7;
BA_ "GenSigMaxLatency" SG_ 2147485018 FrontConspicLamp_stat_LoRight_IS 259;
BA_ "SystemSignalLongSymbol" SG_ 2147485018 FrontConspicLamp_stat_LoRight_IS "FrontConspicLamp_stat_LoRight_ISig_4";
BA_ "GenSigCycleTime" SG_ 2147485018 FrontConspicLamp_stat_LoLeft_ISi 100;
BA_ "GenSigCycleTimeActive" SG_ 2147485018 FrontConspicLamp_stat_LoLeft_ISi 100;
BA_ "GenSigStartValue" SG_ 2147485018 FrontConspicLamp_stat_LoLeft_ISi 7;
BA_ "GenSigMaxLatency" SG_ 2147485018 FrontConspicLamp_stat_LoLeft_ISi 259;
BA_ "SystemSignalLongSymbol" SG_ 2147485018 FrontConspicLamp_stat_LoLeft_ISi "FrontConspicLamp_stat_LoLeft_ISig_4";
BA_ "GenSigCycleTime" SG_ 2147485018 TrailerDirIndRightOutputStat_ISi 100;
BA_ "GenSigCycleTimeActive" SG_ 2147485018 TrailerDirIndRightOutputStat_ISi 100;
BA_ "GenSigStartValue" SG_ 2147485018 TrailerDirIndRightOutputStat_ISi 7;
BA_ "SystemSignalLongSymbol" SG_ 2147485018 TrailerDirIndRightOutputStat_ISi "TrailerDirIndRightOutputStat_ISig_4";
BA_ "GenSigCycleTime" SG_ 2147485018 TrailerPosLightRightOutputStat_I 100;
BA_ "GenSigCycleTimeActive" SG_ 2147485018 TrailerPosLightRightOutputStat_I 100;
BA_ "GenSigStartValue" SG_ 2147485018 TrailerPosLightRightOutputStat_I 7;
BA_ "SystemSignalLongSymbol" SG_ 2147485018 TrailerPosLightRightOutputStat_I "TrailerPosLightRightOutputStat_ISig_4";
BA_ "GenSigCycleTime" SG_ 2147485018 FrontConspicLamp_stat_HiRight_IS 100;
BA_ "GenSigCycleTimeActive" SG_ 2147485018 FrontConspicLamp_stat_HiRight_IS 100;
BA_ "GenSigStartValue" SG_ 2147485018 FrontConspicLamp_stat_HiRight_IS 7;
BA_ "GenSigMaxLatency" SG_ 2147485018 FrontConspicLamp_stat_HiRight_IS 259;
BA_ "SystemSignalLongSymbol" SG_ 2147485018 FrontConspicLamp_stat_HiRight_IS "FrontConspicLamp_stat_HiRight_ISig_4";
BA_ "GenSigCycleTime" SG_ 2147484194 FASSaturated_ISig_4 100;
BA_ "GenSigCycleTimeActive" SG_ 2147484194 FASSaturated_ISig_4 100;
BA_ "GenSigStartValue" SG_ 2147484194 FASSaturated_ISig_4 3;
BA_ "GenSigMaxLatency" SG_ 2147484194 FASSaturated_ISig_4 27;
BA_ "GenSigCycleTime" SG_ 2147484194 OverSteerGuidanceStatus_ISig_4 100;
BA_ "GenSigCycleTimeActive" SG_ 2147484194 OverSteerGuidanceStatus_ISig_4 100;
BA_ "GenSigStartValue" SG_ 2147484194 OverSteerGuidanceStatus_ISig_4 3;
BA_ "GenSigMaxLatency" SG_ 2147484194 OverSteerGuidanceStatus_ISig_4 27;
BA_ "GenSigCycleTime" SG_ 2147484194 FASFullyOperational_ISig_4 100;
BA_ "GenSigCycleTimeActive" SG_ 2147484194 FASFullyOperational_ISig_4 100;
BA_ "GenSigStartValue" SG_ 2147484194 FASFullyOperational_ISig_4 3;
BA_ "GenSigMaxLatency" SG_ 2147484194 FASFullyOperational_ISig_4 27;
BA_ "GenSigCycleTime" SG_ 2147484194 FASFunctionInControl_ISig_4 100;
BA_ "GenSigCycleTimeActive" SG_ 2147484194 FASFunctionInControl_ISig_4 100;
BA_ "GenSigStartValue" SG_ 2147484194 FASFunctionInControl_ISig_4 3;
BA_ "GenSigMaxLatency" SG_ 2147484194 FASFunctionInControl_ISig_4 27;
BA_ "GenSigCycleTime" SG_ 2147484194 FrontRoadWheelAngleEstimate_ISig 100;
BA_ "GenSigCycleTimeActive" SG_ 2147484194 FrontRoadWheelAngleEstimate_ISig 100;
BA_ "GenSigStartValue" SG_ 2147484194 FrontRoadWheelAngleEstimate_ISig 65535;
BA_ "GenSigMaxLatency" SG_ 2147484194 FrontRoadWheelAngleEstimate_ISig 27;
BA_ "SystemSignalLongSymbol" SG_ 2147484194 FrontRoadWheelAngleEstimate_ISig "FrontRoadWheelAngleEstimate_ISig_4";
BA_ "GenSigCycleTime" SG_ 2147484194 DriverSteeringTorqueEstimate_ISi 100;
BA_ "GenSigCycleTimeActive" SG_ 2147484194 DriverSteeringTorqueEstimate_ISi 100;
BA_ "GenSigStartValue" SG_ 2147484194 DriverSteeringTorqueEstimate_ISi 1023;
BA_ "GenSigMaxLatency" SG_ 2147484194 DriverSteeringTorqueEstimate_ISi 27;
BA_ "SystemSignalLongSymbol" SG_ 2147484194 DriverSteeringTorqueEstimate_ISi "DriverSteeringTorqueEstimate_ISig_4";
BA_ "GenSigCycleTime" SG_ 2147484194 DriverSteeringTqEstimateConf_ISi 100;
BA_ "GenSigCycleTimeActive" SG_ 2147484194 DriverSteeringTqEstimateConf_ISi 100;
BA_ "GenSigStartValue" SG_ 2147484194 DriverSteeringTqEstimateConf_ISi 7;
BA_ "GenSigMaxLatency" SG_ 2147484194 DriverSteeringTqEstimateConf_ISi 27;
BA_ "SystemSignalLongSymbol" SG_ 2147484194 DriverSteeringTqEstimateConf_ISi "DriverSteeringTqEstimateConf_ISig_4";
BA_ "GenSigCycleTime" SG_ 2147485053 ActualFasPersSettingsButton_ISig 100;
BA_ "GenSigCycleTimeActive" SG_ 2147485053 ActualFasPersSettingsButton_ISig 100;
BA_ "GenSigStartValue" SG_ 2147485053 ActualFasPersSettingsButton_ISig 7;
BA_ "SystemSignalLongSymbol" SG_ 2147485053 ActualFasPersSettingsButton_ISig "ActualFasPersSettingsButton_ISig_4";
BA_ "GenSigCycleTime" SG_ 2147485053 FasUsrDefStiffStraightSetting_IS 100;
BA_ "GenSigCycleTimeActive" SG_ 2147485053 FasUsrDefStiffStraightSetting_IS 100;
BA_ "GenSigStartValue" SG_ 2147485053 FasUsrDefStiffStraightSetting_IS 31;
BA_ "SystemSignalLongSymbol" SG_ 2147485053 FasUsrDefStiffStraightSetting_IS "FasUsrDefStiffStraightSetting_ISig_4";
BA_ "GenSigCycleTime" SG_ 2147485053 FuelLostByBraking_ISig_4 100;
BA_ "GenSigCycleTimeActive" SG_ 2147485053 FuelLostByBraking_ISig_4 100;
BA_ "GenSigStartValue" SG_ 2147485053 FuelLostByBraking_ISig_4 4294967295;
BA_ "Platform_VMCU1_Sig" SG_ 2147485053 FuelLostByBraking_ISig_4 1;
BA_ "GenSigCycleTime" SG_ 2147485053 ActualFasManualOffsetSetting_ISi 100;
BA_ "GenSigCycleTimeActive" SG_ 2147485053 ActualFasManualOffsetSetting_ISi 100;
BA_ "GenSigStartValue" SG_ 2147485053 ActualFasManualOffsetSetting_ISi 31;
BA_ "SystemSignalLongSymbol" SG_ 2147485053 ActualFasManualOffsetSetting_ISi "ActualFasManualOffsetSetting_ISig_4";
BA_ "GenSigCycleTime" SG_ 2147485053 FasUsrDefinedDampingSetting_ISig 100;
BA_ "GenSigCycleTimeActive" SG_ 2147485053 FasUsrDefinedDampingSetting_ISig 100;
BA_ "GenSigStartValue" SG_ 2147485053 FasUsrDefinedDampingSetting_ISig 31;
BA_ "SystemSignalLongSymbol" SG_ 2147485053 FasUsrDefinedDampingSetting_ISig "FasUsrDefinedDampingSetting_ISig_4";
BA_ "GenSigCycleTime" SG_ 2147485053 FasDriver_ISig_4 100;
BA_ "GenSigCycleTimeActive" SG_ 2147485053 FasDriver_ISig_4 100;
BA_ "GenSigStartValue" SG_ 2147485053 FasDriver_ISig_4 15;
BA_ "GenSigCycleTime" SG_ 2147485053 FasUsrDefLowSpeedReturnSetting_I 100;
BA_ "GenSigCycleTimeActive" SG_ 2147485053 FasUsrDefLowSpeedReturnSetting_I 100;
BA_ "GenSigStartValue" SG_ 2147485053 FasUsrDefLowSpeedReturnSetting_I 31;
BA_ "SystemSignalLongSymbol" SG_ 2147485053 FasUsrDefLowSpeedReturnSetting_I "FasUsrDefLowSpeedReturnSetting_ISig_4";
BA_ "GenSigCycleTime" SG_ 2147485053 FasUsrDefStiffnessCurveSetting_I 100;
BA_ "GenSigCycleTimeActive" SG_ 2147485053 FasUsrDefStiffnessCurveSetting_I 100;
BA_ "GenSigStartValue" SG_ 2147485053 FasUsrDefStiffnessCurveSetting_I 31;
BA_ "SystemSignalLongSymbol" SG_ 2147485053 FasUsrDefStiffnessCurveSetting_I "FasUsrDefStiffnessCurveSetting_ISig_4";
BA_ "GenSigCycleTime" SG_ 2147484478 PS_PosLightDoorOpen 100;
BA_ "GenSigCycleTimeActive" SG_ 2147484478 PS_PosLightDoorOpen 100;
BA_ "GenSigStartValue" SG_ 2147484478 PS_PosLightDoorOpen 3;
BA_ "Platform_VMCU1_Sig" SG_ 2147484478 PS_PosLightDoorOpen 1;
BA_ "GenSigCycleTime" SG_ 2147484478 PS_FogLightRear 100;
BA_ "GenSigCycleTimeActive" SG_ 2147484478 PS_FogLightRear 100;
BA_ "GenSigStartValue" SG_ 2147484478 PS_FogLightRear 3;
BA_ "Platform_VMCU1_Sig" SG_ 2147484478 PS_FogLightRear 1;
BA_ "GenSigCycleTime" SG_ 2147484478 TrailerBodyLampDI_stat 100;
BA_ "GenSigCycleTimeActive" SG_ 2147484478 TrailerBodyLampDI_stat 100;
BA_ "GenSigStartValue" SG_ 2147484478 TrailerBodyLampDI_stat 3;
BA_ "Platform_VMCU1_Sig" SG_ 2147484478 TrailerBodyLampDI_stat 1;
BA_ "GenSigCycleTime" SG_ 2147484478 ParkedLoadDistribution_ISig_4 100;
BA_ "GenSigCycleTimeActive" SG_ 2147484478 ParkedLoadDistribution_ISig_4 100;
BA_ "GenSigStartValue" SG_ 2147484478 ParkedLoadDistribution_ISig_4 7;
BA_ "Platform_VMCU1_Sig" SG_ 2147484478 ParkedLoadDistribution_ISig_4 1;
BA_ "GenSigCycleTime" SG_ 2147484478 PV_HeadLightLevel 100;
BA_ "GenSigCycleTimeActive" SG_ 2147484478 PV_HeadLightLevel 100;
BA_ "GenSigStartValue" SG_ 2147484478 PV_HeadLightLevel 15;
BA_ "Platform_VMCU1_Sig" SG_ 2147484478 PV_HeadLightLevel 1;
BA_ "GenSigCycleTime" SG_ 2147484478 TrailerBodyLampFdbk_stat 100;
BA_ "GenSigCycleTimeActive" SG_ 2147484478 TrailerBodyLampFdbk_stat 100;
BA_ "GenSigStartValue" SG_ 2147484478 TrailerBodyLampFdbk_stat 3;
BA_ "Platform_VMCU1_Sig" SG_ 2147484478 TrailerBodyLampFdbk_stat 1;
BA_ "GenSigCycleTime" SG_ 2147484478 PS_FogLightFront 100;
BA_ "GenSigCycleTimeActive" SG_ 2147484478 PS_FogLightFront 100;
BA_ "GenSigStartValue" SG_ 2147484478 PS_FogLightFront 3;
BA_ "Platform_VMCU1_Sig" SG_ 2147484478 PS_FogLightFront 1;
BA_ "GenSigCycleTime" SG_ 2147484478 Alcolock_PBReleaseInhibit_ind 100;
BA_ "GenSigCycleTimeActive" SG_ 2147484478 Alcolock_PBReleaseInhibit_ind 100;
BA_ "GenSigStartValue" SG_ 2147484478 Alcolock_PBReleaseInhibit_ind 7;
BA_ "GenSigCycleTime" SG_ 2147484478 DHCNotificationReq 100;
BA_ "GenSigCycleTimeActive" SG_ 2147484478 DHCNotificationReq 100;
BA_ "GenSigStartValue" SG_ 2147484478 DHCNotificationReq 15;
BA_ "GenSigCycleTime" SG_ 2147484478 DriverCrank_rqst 100;
BA_ "GenSigCycleTimeActive" SG_ 2147484478 DriverCrank_rqst 100;
BA_ "GenSigStartValue" SG_ 2147484478 DriverCrank_rqst 3;
BA_ "Platform_VMCU1_Sig" SG_ 2147484478 DriverCrank_rqst 1;
BA_ "GenSigCycleTime" SG_ 2147484478 PS_HeadLightAdjustment 100;
BA_ "GenSigCycleTimeActive" SG_ 2147484478 PS_HeadLightAdjustment 100;
BA_ "GenSigStartValue" SG_ 2147484478 PS_HeadLightAdjustment 3;
BA_ "Platform_VMCU1_Sig" SG_ 2147484478 PS_HeadLightAdjustment 1;
BA_ "GenSigCycleTime" SG_ 2147484478 PS_MainBeam 100;
BA_ "GenSigCycleTimeActive" SG_ 2147484478 PS_MainBeam 100;
BA_ "GenSigStartValue" SG_ 2147484478 PS_MainBeam 3;
BA_ "Platform_VMCU1_Sig" SG_ 2147484478 PS_MainBeam 1;
BA_ "GenSigCycleTime" SG_ 2147484478 InstFuel_ConsumpValue 100;
BA_ "GenSigCycleTimeActive" SG_ 2147484478 InstFuel_ConsumpValue 100;
BA_ "GenSigStartValue" SG_ 2147484478 InstFuel_ConsumpValue 65535;
BA_ "Platform_VMCU1_Sig" SG_ 2147484478 InstFuel_ConsumpValue 1;
BA_ "GenSigCycleTime" SG_ 2147484478 InstFuel_VehicleMoving 100;
BA_ "GenSigCycleTimeActive" SG_ 2147484478 InstFuel_VehicleMoving 100;
BA_ "GenSigStartValue" SG_ 2147484478 InstFuel_VehicleMoving 3;
BA_ "Platform_VMCU1_Sig" SG_ 2147484478 InstFuel_VehicleMoving 1;
BA_ "GenSigCycleTime" SG_ 2147484478 PS_AFSAllowedInDriveP 100;
BA_ "GenSigCycleTimeActive" SG_ 2147484478 PS_AFSAllowedInDriveP 100;
BA_ "GenSigStartValue" SG_ 2147484478 PS_AFSAllowedInDriveP 3;
BA_ "GenSigCycleTime" SG_ 2147484478 PS_AFS 100;
BA_ "GenSigCycleTimeActive" SG_ 2147484478 PS_AFS 100;
BA_ "GenSigStartValue" SG_ 2147484478 PS_AFS 7;
BA_ "GenSigCycleTime" SG_ 2147484478 AC2CoolingFanControl_rqst 100;
BA_ "GenSigCycleTimeActive" SG_ 2147484478 AC2CoolingFanControl_rqst 100;
BA_ "GenSigStartValue" SG_ 2147484478 AC2CoolingFanControl_rqst 3;
BA_ "Platform_VMCU1_Sig" SG_ 2147484478 AC2CoolingFanControl_rqst 1;
BA_ "GenSigCycleTime" SG_ 2147484478 DHCStatus 100;
BA_ "GenSigCycleTimeActive" SG_ 2147484478 DHCStatus 100;
BA_ "GenSigStartValue" SG_ 2147484478 DHCStatus 3;
BA_ "GenSigCycleTime" SG_ 2147484478 PS_PositionLight 100;
BA_ "GenSigCycleTimeActive" SG_ 2147484478 PS_PositionLight 100;
BA_ "GenSigStartValue" SG_ 2147484478 PS_PositionLight 3;
BA_REL_ "GenSigTimeoutTime" BU_SG_REL_ ECUspare1 SG_ 2044 Debug_PVT_SCIM_RD_DAI1Fault 200;
BA_REL_ "GenSigFirstTimeoutTime" BU_SG_REL_ ECUspare1 SG_ 2044 Debug_PVT_SCIM_RD_DAI1Fault 1500;
BA_REL_ "GenSigTimeoutTime" BU_SG_REL_ ECUspare1 SG_ 2044 Debug_PVT_SCIM_RD_DAI2Fualt 200;
BA_REL_ "GenSigFirstTimeoutTime" BU_SG_REL_ ECUspare1 SG_ 2044 Debug_PVT_SCIM_RD_DAI2Fualt 1500;
BA_REL_ "GenSigFirstTimeoutTime" BU_SG_REL_ ECUspare1 SG_ 2044 Debug_PVT_SCIM_RD_ADI16Fault 1500;
BA_REL_ "GenSigTimeoutTime" BU_SG_REL_ ECUspare1 SG_ 2044 Debug_PVT_SCIM_RD_ADI16Fault 200;
BA_REL_ "GenSigFirstTimeoutTime" BU_SG_REL_ ECUspare1 SG_ 2044 Debug_PVT_SCIM_RD_ADI15Fault 1500;
BA_REL_ "GenSigTimeoutTime" BU_SG_REL_ ECUspare1 SG_ 2044 Debug_PVT_SCIM_RD_ADI15Fault 200;
BA_REL_ "GenSigTimeoutTime" BU_SG_REL_ ECUspare1 SG_ 2044 Debug_PVT_SCIM_RD_ADI14Fault 200;
BA_REL_ "GenSigFirstTimeoutTime" BU_SG_REL_ ECUspare1 SG_ 2044 Debug_PVT_SCIM_RD_ADI14Fault 1500;
BA_REL_ "GenSigFirstTimeoutTime" BU_SG_REL_ ECUspare1 SG_ 2044 Debug_PVT_SCIM_RD_ADI13Fault 1500;
BA_REL_ "GenSigTimeoutTime" BU_SG_REL_ ECUspare1 SG_ 2044 Debug_PVT_SCIM_RD_ADI13Fault 200;
BA_REL_ "GenSigFirstTimeoutTime" BU_SG_REL_ ECUspare1 SG_ 2044 Debug_PVT_SCIM_RD_ADI12Fault 1500;
BA_REL_ "GenSigTimeoutTime" BU_SG_REL_ ECUspare1 SG_ 2044 Debug_PVT_SCIM_RD_ADI12Fault 200;
BA_REL_ "GenSigFirstTimeoutTime" BU_SG_REL_ ECUspare1 SG_ 2044 Debug_PVT_SCIM_RD_ADI11Fault 1500;
BA_REL_ "GenSigTimeoutTime" BU_SG_REL_ ECUspare1 SG_ 2044 Debug_PVT_SCIM_RD_ADI11Fault 200;
BA_REL_ "GenSigFirstTimeoutTime" BU_SG_REL_ ECUspare1 SG_ 2044 Debug_PVT_SCIM_RD_ADI10Fault 1500;
BA_REL_ "GenSigTimeoutTime" BU_SG_REL_ ECUspare1 SG_ 2044 Debug_PVT_SCIM_RD_ADI10Fault 200;
BA_REL_ "GenSigTimeoutTime" BU_SG_REL_ ECUspare1 SG_ 2044 Debug_PVT_SCIM_RD_ADI09Fault 200;
BA_REL_ "GenSigFirstTimeoutTime" BU_SG_REL_ ECUspare1 SG_ 2044 Debug_PVT_SCIM_RD_ADI09Fault 1500;
BA_REL_ "GenSigTimeoutTime" BU_SG_REL_ ECUspare1 SG_ 2044 Debug_PVT_SCIM_RD_ADI08Fault 200;
BA_REL_ "GenSigFirstTimeoutTime" BU_SG_REL_ ECUspare1 SG_ 2044 Debug_PVT_SCIM_RD_ADI08Fault 1500;
BA_REL_ "GenSigTimeoutTime" BU_SG_REL_ ECUspare1 SG_ 2044 Debug_PVT_SCIM_RD_ADI07Fault 200;
BA_REL_ "GenSigFirstTimeoutTime" BU_SG_REL_ ECUspare1 SG_ 2044 Debug_PVT_SCIM_RD_ADI07Fault 1500;
BA_REL_ "GenSigFirstTimeoutTime" BU_SG_REL_ ECUspare1 SG_ 2044 Debug_PVT_SCIM_RD_ADI06Fault 1500;
BA_REL_ "GenSigTimeoutTime" BU_SG_REL_ ECUspare1 SG_ 2044 Debug_PVT_SCIM_RD_ADI06Fault 200;
BA_REL_ "GenSigFirstTimeoutTime" BU_SG_REL_ ECUspare1 SG_ 2044 Debug_PVT_SCIM_RD_ADI05Fault 1500;
BA_REL_ "GenSigTimeoutTime" BU_SG_REL_ ECUspare1 SG_ 2044 Debug_PVT_SCIM_RD_ADI05Fault 200;
BA_REL_ "GenSigTimeoutTime" BU_SG_REL_ ECUspare1 SG_ 2044 Debug_PVT_SCIM_RD_ADI04Fault 200;
BA_REL_ "GenSigFirstTimeoutTime" BU_SG_REL_ ECUspare1 SG_ 2044 Debug_PVT_SCIM_RD_ADI04Fault 1500;
BA_REL_ "GenSigTimeoutTime" BU_SG_REL_ ECUspare1 SG_ 2044 Debug_PVT_SCIM_RD_ADI03Fault 200;
BA_REL_ "GenSigFirstTimeoutTime" BU_SG_REL_ ECUspare1 SG_ 2044 Debug_PVT_SCIM_RD_ADI03Fault 1500;
BA_REL_ "GenSigTimeoutTime" BU_SG_REL_ ECUspare1 SG_ 2044 Debug_PVT_SCIM_RD_ADI02Fault 200;
BA_REL_ "GenSigFirstTimeoutTime" BU_SG_REL_ ECUspare1 SG_ 2044 Debug_PVT_SCIM_RD_ADI02Fault 1500;
BA_REL_ "GenSigTimeoutTime" BU_SG_REL_ ECUspare1 SG_ 2044 Debug_PVT_SCIM_RD_ADI01Fault 200;
BA_REL_ "GenSigFirstTimeoutTime" BU_SG_REL_ ECUspare1 SG_ 2044 Debug_PVT_SCIM_RD_ADI01Fault 1500;
BA_REL_ "GenSigTimeoutTime" BU_SG_REL_ ECUspare1 SG_ 2034 Debug_PVT_PEPS_AverRSSI2 200;
BA_REL_ "GenSigFirstTimeoutTime" BU_SG_REL_ ECUspare1 SG_ 2034 Debug_PVT_PEPS_AverRSSI2 1500;
BA_REL_ "GenSigTimeoutTime" BU_SG_REL_ ECUspare1 SG_ 2034 Debug_PVT_PEPS_AverRSSI1 200;
BA_REL_ "GenSigFirstTimeoutTime" BU_SG_REL_ ECUspare1 SG_ 2034 Debug_PVT_PEPS_AverRSSI1 1500;
BA_REL_ "GenSigTimeoutTime" BU_SG_REL_ ECUspare1 SG_ 2034 Debug_PVT_PEPS_DecRSSI 200;
BA_REL_ "GenSigFirstTimeoutTime" BU_SG_REL_ ECUspare1 SG_ 2034 Debug_PVT_PEPS_DecRSSI 1500;
BA_REL_ "GenSigTimeoutTime" BU_SG_REL_ ECUspare1 SG_ 2033 Debug_PVT_PEPS_Cali_Cir 200;
BA_REL_ "GenSigFirstTimeoutTime" BU_SG_REL_ ECUspare1 SG_ 2033 Debug_PVT_PEPS_Cali_Cir 1500;
BA_REL_ "GenSigTimeoutTime" BU_SG_REL_ ECUspare1 SG_ 2033 Debug_PVT_PEPS_K_Cir 200;
BA_REL_ "GenSigFirstTimeoutTime" BU_SG_REL_ ECUspare1 SG_ 2033 Debug_PVT_PEPS_K_Cir 1500;
BA_REL_ "GenSigTimeoutTime" BU_SG_REL_ ECUspare1 SG_ 2033 Debug_PVT_PEPS_D_AntP1toP2_Y 200;
BA_REL_ "GenSigFirstTimeoutTime" BU_SG_REL_ ECUspare1 SG_ 2033 Debug_PVT_PEPS_D_AntP1toP2_Y 1500;
BA_REL_ "GenSigTimeoutTime" BU_SG_REL_ ECUspare1 SG_ 2033 Debug_PVT_PEPS_D_AntP1toP2_X 200;
BA_REL_ "GenSigFirstTimeoutTime" BU_SG_REL_ ECUspare1 SG_ 2033 Debug_PVT_PEPS_D_AntP1toP2_X 1500;
BA_REL_ "GenSigTimeoutTime" BU_SG_REL_ ECUspare1 SG_ 2032 Debug_PVT_PEPS_D_AntP1toP2_Cir 200;
BA_REL_ "GenSigFirstTimeoutTime" BU_SG_REL_ ECUspare1 SG_ 2032 Debug_PVT_PEPS_D_AntP1toP2_Cir 1500;
BA_REL_ "GenSigTimeoutTime" BU_SG_REL_ ECUspare1 SG_ 2032 Debug_PVT_PEPS_CTPoint_Y2 200;
BA_REL_ "GenSigFirstTimeoutTime" BU_SG_REL_ ECUspare1 SG_ 2032 Debug_PVT_PEPS_CTPoint_Y2 1500;
BA_REL_ "GenSigTimeoutTime" BU_SG_REL_ ECUspare1 SG_ 2032 Debug_PVT_PEPS_CTPoint_Y1 200;
BA_REL_ "GenSigFirstTimeoutTime" BU_SG_REL_ ECUspare1 SG_ 2032 Debug_PVT_PEPS_CTPoint_Y1 1500;
BA_REL_ "GenSigTimeoutTime" BU_SG_REL_ ECUspare1 SG_ 2032 Debug_PVT_PEPS_CTPoint_X2 200;
BA_REL_ "GenSigFirstTimeoutTime" BU_SG_REL_ ECUspare1 SG_ 2032 Debug_PVT_PEPS_CTPoint_X2 1500;
BA_REL_ "GenSigTimeoutTime" BU_SG_REL_ ECUspare1 SG_ 2032 Debug_PVT_PEPS_CTPoint_X1 200;
BA_REL_ "GenSigFirstTimeoutTime" BU_SG_REL_ ECUspare1 SG_ 2032 Debug_PVT_PEPS_CTPoint_X1 1500;
BA_REL_ "GenSigTimeoutTime" BU_SG_REL_ ECUspare1 SG_ 2024 Debug_PVT_PEPS_AntPi_Y 200;
BA_REL_ "GenSigFirstTimeoutTime" BU_SG_REL_ ECUspare1 SG_ 2024 Debug_PVT_PEPS_AntPi_Y 1500;
BA_REL_ "GenSigTimeoutTime" BU_SG_REL_ ECUspare1 SG_ 2024 Debug_PVT_PEPS_AntPi_X 200;
BA_REL_ "GenSigFirstTimeoutTime" BU_SG_REL_ ECUspare1 SG_ 2024 Debug_PVT_PEPS_AntPi_X 1500;
BA_REL_ "GenSigTimeoutTime" BU_SG_REL_ ECUspare1 SG_ 2024 Debug_PVT_PEPS_AntP1_Y 200;
BA_REL_ "GenSigFirstTimeoutTime" BU_SG_REL_ ECUspare1 SG_ 2024 Debug_PVT_PEPS_AntP1_Y 1500;
BA_REL_ "GenSigTimeoutTime" BU_SG_REL_ ECUspare1 SG_ 2024 Debug_PVT_PEPS_AntP1_X 200;
BA_REL_ "GenSigFirstTimeoutTime" BU_SG_REL_ ECUspare1 SG_ 2024 Debug_PVT_PEPS_AntP1_X 1500;
BA_REL_ "GenSigTimeoutTime" BU_SG_REL_ CIOM SG_ 2041 Debug_PVT_PEPS_AntPi_Y_Ctrl 200;
BA_REL_ "GenSigFirstTimeoutTime" BU_SG_REL_ CIOM SG_ 2041 Debug_PVT_PEPS_AntPi_Y_Ctrl 1500;
BA_REL_ "GenSigTimeoutTime" BU_SG_REL_ CIOM SG_ 2041 Debug_PVT_PEPS_AntPi_X_Ctrl 200;
BA_REL_ "GenSigFirstTimeoutTime" BU_SG_REL_ CIOM SG_ 2041 Debug_PVT_PEPS_AntPi_X_Ctrl 1500;
BA_REL_ "GenSigTimeoutTime" BU_SG_REL_ CIOM SG_ 2041 Debug_PVT_PEPS_AntP1_Y_Ctrl 200;
BA_REL_ "GenSigFirstTimeoutTime" BU_SG_REL_ CIOM SG_ 2041 Debug_PVT_PEPS_AntP1_Y_Ctrl 1500;
BA_REL_ "GenSigTimeoutTime" BU_SG_REL_ CIOM SG_ 2041 Debug_PVT_PEPS_AntP1_X_Ctrl 200;
BA_REL_ "GenSigFirstTimeoutTime" BU_SG_REL_ CIOM SG_ 2041 Debug_PVT_PEPS_AntP1_X_Ctrl 1500;
BA_REL_ "GenSigTimeoutTime" BU_SG_REL_ CIOM SG_ 2040 Debug_PVT_PEPS_VWidth_Ctrl 200;
BA_REL_ "GenSigFirstTimeoutTime" BU_SG_REL_ CIOM SG_ 2040 Debug_PVT_PEPS_VWidth_Ctrl 1500;
BA_REL_ "GenSigTimeoutTime" BU_SG_REL_ CIOM SG_ 2040 Debug_PVT_PEPS_VSquare_Ctrl 200;
BA_REL_ "GenSigFirstTimeoutTime" BU_SG_REL_ CIOM SG_ 2040 Debug_PVT_PEPS_VSquare_Ctrl 1500;
BA_REL_ "GenSigTimeoutTime" BU_SG_REL_ CIOM SG_ 2040 Debug_PVT_PEPS_Vlength_Ctrl 200;
BA_REL_ "GenSigFirstTimeoutTime" BU_SG_REL_ CIOM SG_ 2040 Debug_PVT_PEPS_Vlength_Ctrl 1500;
BA_REL_ "GenSigTimeoutTime" BU_SG_REL_ CIOM SG_ 2040 Debug_PVT_PEPS_K_AntP4_Ctrl 200;
BA_REL_ "GenSigFirstTimeoutTime" BU_SG_REL_ CIOM SG_ 2040 Debug_PVT_PEPS_K_AntP4_Ctrl 1500;
BA_REL_ "GenSigFirstTimeoutTime" BU_SG_REL_ ECUspare1 SG_ 2023 Debug_PVT_PEPS_Vwidth 1500;
BA_REL_ "GenSigTimeoutTime" BU_SG_REL_ ECUspare1 SG_ 2023 Debug_PVT_PEPS_Vwidth 200;
BA_REL_ "GenSigFirstTimeoutTime" BU_SG_REL_ ECUspare1 SG_ 2023 Debug_PVT_PEPS_Vsquare 1500;
BA_REL_ "GenSigTimeoutTime" BU_SG_REL_ ECUspare1 SG_ 2023 Debug_PVT_PEPS_Vsquare 200;
BA_REL_ "GenSigFirstTimeoutTime" BU_SG_REL_ ECUspare1 SG_ 2023 Debug_PVT_PEPS_Vlength 1500;
BA_REL_ "GenSigTimeoutTime" BU_SG_REL_ ECUspare1 SG_ 2023 Debug_PVT_PEPS_Vlength 200;
BA_REL_ "GenSigTimeoutTime" BU_SG_REL_ ECUspare1 SG_ 2023 Debug_PVT_PEPS_K_AntP4 200;
BA_REL_ "GenSigFirstTimeoutTime" BU_SG_REL_ ECUspare1 SG_ 2023 Debug_PVT_PEPS_K_AntP4 1500;
BA_REL_ "GenSigTimeoutTime" BU_SG_REL_ ECUspare1 SG_ 2022 Debug_PVT_PEPS_K_AntPi 200;
BA_REL_ "GenSigFirstTimeoutTime" BU_SG_REL_ ECUspare1 SG_ 2022 Debug_PVT_PEPS_K_AntPi 1500;
BA_REL_ "GenSigTimeoutTime" BU_SG_REL_ ECUspare1 SG_ 2022 Debug_PVT_PEPS_K_AntP3 200;
BA_REL_ "GenSigFirstTimeoutTime" BU_SG_REL_ ECUspare1 SG_ 2022 Debug_PVT_PEPS_K_AntP3 1500;
BA_REL_ "GenSigTimeoutTime" BU_SG_REL_ ECUspare1 SG_ 2022 Debug_PVT_PEPS_K_AntP2 200;
BA_REL_ "GenSigFirstTimeoutTime" BU_SG_REL_ ECUspare1 SG_ 2022 Debug_PVT_PEPS_K_AntP2 1500;
BA_REL_ "GenSigTimeoutTime" BU_SG_REL_ ECUspare1 SG_ 2022 Debug_PVT_PEPS_K_AntP1 200;
BA_REL_ "GenSigFirstTimeoutTime" BU_SG_REL_ ECUspare1 SG_ 2022 Debug_PVT_PEPS_K_AntP1 1500;
BA_REL_ "GenSigTimeoutTime" BU_SG_REL_ ECUspare1 SG_ 2021 Debug_PVT_PEPS_A_AntPi 200;
BA_REL_ "GenSigFirstTimeoutTime" BU_SG_REL_ ECUspare1 SG_ 2021 Debug_PVT_PEPS_A_AntPi 1500;
BA_REL_ "GenSigTimeoutTime" BU_SG_REL_ ECUspare1 SG_ 2021 Debug_PVT_PEPS_A_AntP4 200;
BA_REL_ "GenSigFirstTimeoutTime" BU_SG_REL_ ECUspare1 SG_ 2021 Debug_PVT_PEPS_A_AntP4 1500;
BA_REL_ "GenSigTimeoutTime" BU_SG_REL_ ECUspare1 SG_ 2021 Debug_PVT_PEPS_A_AntP3 200;
BA_REL_ "GenSigFirstTimeoutTime" BU_SG_REL_ ECUspare1 SG_ 2021 Debug_PVT_PEPS_A_AntP3 1500;
BA_REL_ "GenSigTimeoutTime" BU_SG_REL_ ECUspare1 SG_ 2021 Debug_PVT_PEPS_A_AntP2 200;
BA_REL_ "GenSigFirstTimeoutTime" BU_SG_REL_ ECUspare1 SG_ 2021 Debug_PVT_PEPS_A_AntP2 1500;
BA_REL_ "GenSigTimeoutTime" BU_SG_REL_ ECUspare1 SG_ 2021 Debug_PVT_PEPS_A_AntP1 200;
BA_REL_ "GenSigFirstTimeoutTime" BU_SG_REL_ ECUspare1 SG_ 2021 Debug_PVT_PEPS_A_AntP1 1500;
BA_REL_ "GenSigTimeoutTime" BU_SG_REL_ ECUspare1 SG_ 2020 Debug_PVT_PEPS_LimitRSSIPi 200;
BA_REL_ "GenSigFirstTimeoutTime" BU_SG_REL_ ECUspare1 SG_ 2020 Debug_PVT_PEPS_LimitRSSIPi 1500;
BA_REL_ "GenSigTimeoutTime" BU_SG_REL_ ECUspare1 SG_ 2020 Debug_PVT_PEPS_LimitRSSIP4 200;
BA_REL_ "GenSigFirstTimeoutTime" BU_SG_REL_ ECUspare1 SG_ 2020 Debug_PVT_PEPS_LimitRSSIP4 1500;
BA_REL_ "GenSigTimeoutTime" BU_SG_REL_ ECUspare1 SG_ 2020 Debug_PVT_PEPS_LimitRSSIP3 200;
BA_REL_ "GenSigFirstTimeoutTime" BU_SG_REL_ ECUspare1 SG_ 2020 Debug_PVT_PEPS_LimitRSSIP3 1500;
BA_REL_ "GenSigTimeoutTime" BU_SG_REL_ ECUspare1 SG_ 2020 Debug_PVT_PEPS_LimitRSSIP2 200;
BA_REL_ "GenSigFirstTimeoutTime" BU_SG_REL_ ECUspare1 SG_ 2020 Debug_PVT_PEPS_LimitRSSIP2 1500;
BA_REL_ "GenSigTimeoutTime" BU_SG_REL_ ECUspare1 SG_ 2020 Debug_PVT_PEPS_LimitRSSIP1 200;
BA_REL_ "GenSigFirstTimeoutTime" BU_SG_REL_ ECUspare1 SG_ 2020 Debug_PVT_PEPS_LimitRSSIP1 1500;
BA_REL_ "GenSigTimeoutTime" BU_SG_REL_ CIOM SG_ 2039 Debug_PVT_PEPS_K_AntPi_Ctrl 200;
BA_REL_ "GenSigFirstTimeoutTime" BU_SG_REL_ CIOM SG_ 2039 Debug_PVT_PEPS_K_AntPi_Ctrl 1500;
BA_REL_ "GenSigTimeoutTime" BU_SG_REL_ CIOM SG_ 2039 Debug_PVT_PEPS_K_AntP3_Ctrl 200;
BA_REL_ "GenSigFirstTimeoutTime" BU_SG_REL_ CIOM SG_ 2039 Debug_PVT_PEPS_K_AntP3_Ctrl 1500;
BA_REL_ "GenSigTimeoutTime" BU_SG_REL_ CIOM SG_ 2039 Debug_PVT_PEPS_K_AntP2_Ctrl 200;
BA_REL_ "GenSigFirstTimeoutTime" BU_SG_REL_ CIOM SG_ 2039 Debug_PVT_PEPS_K_AntP2_Ctrl 1500;
BA_REL_ "GenSigTimeoutTime" BU_SG_REL_ CIOM SG_ 2039 Debug_PVT_PEPS_K_AntP1_Ctrl 200;
BA_REL_ "GenSigFirstTimeoutTime" BU_SG_REL_ CIOM SG_ 2039 Debug_PVT_PEPS_K_AntP1_Ctrl 1500;
BA_REL_ "GenSigTimeoutTime" BU_SG_REL_ CIOM SG_ 2038 Debug_PVT_PEPS_A_AntPi_Ctrl 200;
BA_REL_ "GenSigFirstTimeoutTime" BU_SG_REL_ CIOM SG_ 2038 Debug_PVT_PEPS_A_AntPi_Ctrl 1500;
BA_REL_ "GenSigTimeoutTime" BU_SG_REL_ CIOM SG_ 2038 Debug_PVT_PEPS_A_AntP4_Ctrl 200;
BA_REL_ "GenSigFirstTimeoutTime" BU_SG_REL_ CIOM SG_ 2038 Debug_PVT_PEPS_A_AntP4_Ctrl 1500;
BA_REL_ "GenSigTimeoutTime" BU_SG_REL_ CIOM SG_ 2038 Debug_PVT_PEPS_A_AntP3_Ctrl 200;
BA_REL_ "GenSigFirstTimeoutTime" BU_SG_REL_ CIOM SG_ 2038 Debug_PVT_PEPS_A_AntP3_Ctrl 1500;
BA_REL_ "GenSigTimeoutTime" BU_SG_REL_ CIOM SG_ 2038 Debug_PVT_PEPS_A_AntP2_Ctrl 200;
BA_REL_ "GenSigFirstTimeoutTime" BU_SG_REL_ CIOM SG_ 2038 Debug_PVT_PEPS_A_AntP2_Ctrl 1500;
BA_REL_ "GenSigFirstTimeoutTime" BU_SG_REL_ CIOM SG_ 2038 Debug_PVT_PEPS_A_AntP1_Ctrl 1500;
BA_REL_ "GenSigTimeoutTime" BU_SG_REL_ CIOM SG_ 2038 Debug_PVT_PEPS_A_AntP1_Ctrl 200;
BA_REL_ "GenSigTimeoutTime" BU_SG_REL_ CIOM SG_ 2037 Debug_PVT_PEPS_LmitRSSIPi_Ctrl 200;
BA_REL_ "GenSigFirstTimeoutTime" BU_SG_REL_ CIOM SG_ 2037 Debug_PVT_PEPS_LmitRSSIPi_Ctrl 1500;
BA_REL_ "GenSigTimeoutTime" BU_SG_REL_ CIOM SG_ 2037 Debug_PVT_PEPS_LimitRSSIP4_Ctrl 200;
BA_REL_ "GenSigFirstTimeoutTime" BU_SG_REL_ CIOM SG_ 2037 Debug_PVT_PEPS_LimitRSSIP4_Ctrl 1500;
BA_REL_ "GenSigTimeoutTime" BU_SG_REL_ CIOM SG_ 2037 Debug_PVT_PEPS_LimitRSSIP3_Ctrl 200;
BA_REL_ "GenSigFirstTimeoutTime" BU_SG_REL_ CIOM SG_ 2037 Debug_PVT_PEPS_LimitRSSIP3_Ctrl 1500;
BA_REL_ "GenSigTimeoutTime" BU_SG_REL_ CIOM SG_ 2037 Debug_PVT_PEPS_LimitRSSIP2_Ctrl 200;
BA_REL_ "GenSigFirstTimeoutTime" BU_SG_REL_ CIOM SG_ 2037 Debug_PVT_PEPS_LimitRSSIP2_Ctrl 1500;
BA_REL_ "GenSigTimeoutTime" BU_SG_REL_ CIOM SG_ 2037 Debug_PVT_PEPS_LimitRSSIP1_Ctrl 200;
BA_REL_ "GenSigFirstTimeoutTime" BU_SG_REL_ CIOM SG_ 2037 Debug_PVT_PEPS_LimitRSSIP1_Ctrl 1500;
BA_REL_ "GenSigTimeoutTime" BU_SG_REL_ CIOM SG_ 2036 Debug_PVT_PEPS_Avercut_Ctrl 200;
BA_REL_ "GenSigFirstTimeoutTime" BU_SG_REL_ CIOM SG_ 2036 Debug_PVT_PEPS_Avercut_Ctrl 1500;
BA_REL_ "GenSigTimeoutTime" BU_SG_REL_ CIOM SG_ 2036 Debug_PVT_PEPS_Pi_RSSIcut_Ctrl 200;
BA_REL_ "GenSigFirstTimeoutTime" BU_SG_REL_ CIOM SG_ 2036 Debug_PVT_PEPS_Pi_RSSIcut_Ctrl 1500;
BA_REL_ "GenSigTimeoutTime" BU_SG_REL_ CIOM SG_ 2036 Debug_PVT_PEPS_P3_RSSIcut_Ctrl 200;
BA_REL_ "GenSigFirstTimeoutTime" BU_SG_REL_ CIOM SG_ 2036 Debug_PVT_PEPS_P3_RSSIcut_Ctrl 1500;
BA_REL_ "GenSigTimeoutTime" BU_SG_REL_ CIOM SG_ 2036 Debug_PVT_PEPS_P2_RSSIcut_Ctrl 200;
BA_REL_ "GenSigFirstTimeoutTime" BU_SG_REL_ CIOM SG_ 2036 Debug_PVT_PEPS_P2_RSSIcut_Ctrl 1500;
BA_REL_ "GenSigTimeoutTime" BU_SG_REL_ ECUspare1 SG_ 2019 Debug_PVT_PEPS_Avercut 200;
BA_REL_ "GenSigFirstTimeoutTime" BU_SG_REL_ ECUspare1 SG_ 2019 Debug_PVT_PEPS_Avercut 1500;
BA_REL_ "GenSigTimeoutTime" BU_SG_REL_ ECUspare1 SG_ 2019 Debug_PVT_PEPS_Pi_RSSIcut 200;
BA_REL_ "GenSigFirstTimeoutTime" BU_SG_REL_ ECUspare1 SG_ 2019 Debug_PVT_PEPS_Pi_RSSIcut 1500;
BA_REL_ "GenSigTimeoutTime" BU_SG_REL_ ECUspare1 SG_ 2019 Debug_PVT_PEPS_P2_RSSIcut 200;
BA_REL_ "GenSigFirstTimeoutTime" BU_SG_REL_ ECUspare1 SG_ 2019 Debug_PVT_PEPS_P2_RSSIcut 1500;
BA_REL_ "GenSigTimeoutTime" BU_SG_REL_ ECUspare1 SG_ 2019 Debug_PVT_PEPS_P3_RSSIcut 200;
BA_REL_ "GenSigFirstTimeoutTime" BU_SG_REL_ ECUspare1 SG_ 2019 Debug_PVT_PEPS_P3_RSSIcut 1500;
BA_REL_ "GenSigTimeoutTime" BU_SG_REL_ ECUspare1 SG_ 2018 Debug_PVT_PEPS_Pi_MaxRSSI 200;
BA_REL_ "GenSigFirstTimeoutTime" BU_SG_REL_ ECUspare1 SG_ 2018 Debug_PVT_PEPS_Pi_MaxRSSI 1500;
BA_REL_ "GenSigTimeoutTime" BU_SG_REL_ ECUspare1 SG_ 2018 Debug_PVT_PEPS_P4_MaxRSSI 200;
BA_REL_ "GenSigFirstTimeoutTime" BU_SG_REL_ ECUspare1 SG_ 2018 Debug_PVT_PEPS_P4_MaxRSSI 1500;
BA_REL_ "GenSigTimeoutTime" BU_SG_REL_ ECUspare1 SG_ 2018 Debug_PVT_PEPS_P3_MaxRSSI 200;
BA_REL_ "GenSigFirstTimeoutTime" BU_SG_REL_ ECUspare1 SG_ 2018 Debug_PVT_PEPS_P3_MaxRSSI 1500;
BA_REL_ "GenSigTimeoutTime" BU_SG_REL_ ECUspare1 SG_ 2018 Debug_PVT_PEPS_P2_MaxRSSI 200;
BA_REL_ "GenSigFirstTimeoutTime" BU_SG_REL_ ECUspare1 SG_ 2018 Debug_PVT_PEPS_P2_MaxRSSI 1500;
BA_REL_ "GenSigTimeoutTime" BU_SG_REL_ ECUspare1 SG_ 2018 Debug_PVT_PEPS_P1_MaxRSSI 200;
BA_REL_ "GenSigFirstTimeoutTime" BU_SG_REL_ ECUspare1 SG_ 2018 Debug_PVT_PEPS_P1_MaxRSSI 1500;
BA_REL_ "GenSigTimeoutTime" BU_SG_REL_ CIOM SG_ 2035 Debug_PVT_PEPS_TestPeriod_Ctrl 200;
BA_REL_ "GenSigFirstTimeoutTime" BU_SG_REL_ CIOM SG_ 2035 Debug_PVT_PEPS_TestPeriod_Ctrl 1500;
BA_REL_ "GenSigTimeoutTime" BU_SG_REL_ CIOM SG_ 2035 Debug_PVT_PEPS_Ant_Ctrl 200;
BA_REL_ "GenSigFirstTimeoutTime" BU_SG_REL_ CIOM SG_ 2035 Debug_PVT_PEPS_Ant_Ctrl 1500;
BA_REL_ "GenSigTimeoutTime" BU_SG_REL_ CIOM SG_ 2035 Debug_PVT_PEPS_VDSI_Ctrl 200;
BA_REL_ "GenSigFirstTimeoutTime" BU_SG_REL_ CIOM SG_ 2035 Debug_PVT_PEPS_VDSI_Ctrl 1500;
BA_REL_ "GenSigTimeoutTime" BU_SG_REL_ CIOM SG_ 2035 Debug_PVT_PEPS_Logic_Ctrl 200;
BA_REL_ "GenSigFirstTimeoutTime" BU_SG_REL_ CIOM SG_ 2035 Debug_PVT_PEPS_Logic_Ctrl 1500;
BA_REL_ "GenSigTimeoutTime" BU_SG_REL_ CIOM SG_ 2035 Debug_PVT_PEPS_GainPi_Ctrl 200;
BA_REL_ "GenSigFirstTimeoutTime" BU_SG_REL_ CIOM SG_ 2035 Debug_PVT_PEPS_GainPi_Ctrl 1500;
BA_REL_ "GenSigTimeoutTime" BU_SG_REL_ CIOM SG_ 2035 Debug_PVT_PEPS_GainP4_Ctrl 200;
BA_REL_ "GenSigFirstTimeoutTime" BU_SG_REL_ CIOM SG_ 2035 Debug_PVT_PEPS_GainP4_Ctrl 1500;
BA_REL_ "GenSigTimeoutTime" BU_SG_REL_ CIOM SG_ 2035 Debug_PVT_PEPS_GainP3_Ctrl 200;
BA_REL_ "GenSigFirstTimeoutTime" BU_SG_REL_ CIOM SG_ 2035 Debug_PVT_PEPS_GainP3_Ctrl 1500;
BA_REL_ "GenSigTimeoutTime" BU_SG_REL_ CIOM SG_ 2035 Debug_PVT_PEPS_GainP2_Ctrl 200;
BA_REL_ "GenSigFirstTimeoutTime" BU_SG_REL_ CIOM SG_ 2035 Debug_PVT_PEPS_GainP2_Ctrl 1500;
BA_REL_ "GenSigTimeoutTime" BU_SG_REL_ CIOM SG_ 2035 Debug_PVT_PEPS_GainP1_Ctrl 200;
BA_REL_ "GenSigFirstTimeoutTime" BU_SG_REL_ CIOM SG_ 2035 Debug_PVT_PEPS_GainP1_Ctrl 1500;
BA_REL_ "GenSigTimeoutTime" BU_SG_REL_ ECUspare1 SG_ 2017 Debug_PVT_PEPS_Fob_location 200;
BA_REL_ "GenSigFirstTimeoutTime" BU_SG_REL_ ECUspare1 SG_ 2017 Debug_PVT_PEPS_Fob_location 1500;
BA_REL_ "GenSigTimeoutTime" BU_SG_REL_ ECUspare1 SG_ 2017 Debug_PVT_PEPS_Logic_stat 200;
BA_REL_ "GenSigFirstTimeoutTime" BU_SG_REL_ ECUspare1 SG_ 2017 Debug_PVT_PEPS_Logic_stat 1500;
BA_REL_ "GenSigTimeoutTime" BU_SG_REL_ ECUspare1 SG_ 2017 Debug_PVT_PEPS_AntCtrl_stat 200;
BA_REL_ "GenSigFirstTimeoutTime" BU_SG_REL_ ECUspare1 SG_ 2017 Debug_PVT_PEPS_AntCtrl_stat 1500;
BA_REL_ "GenSigTimeoutTime" BU_SG_REL_ ECUspare1 SG_ 2017 Debug_PVT_PEPS_TestPeriod_stat 200;
BA_REL_ "GenSigFirstTimeoutTime" BU_SG_REL_ ECUspare1 SG_ 2017 Debug_PVT_PEPS_TestPeriod_stat 1500;
BA_REL_ "GenSigTimeoutTime" BU_SG_REL_ ECUspare1 SG_ 2017 Debug_PVT_PEPS_VDSI_stat 200;
BA_REL_ "GenSigFirstTimeoutTime" BU_SG_REL_ ECUspare1 SG_ 2017 Debug_PVT_PEPS_VDSI_stat 1500;
BA_REL_ "GenSigTimeoutTime" BU_SG_REL_ ECUspare1 SG_ 2017 Debug_PVT_PEPS_GainPi_stat 200;
BA_REL_ "GenSigFirstTimeoutTime" BU_SG_REL_ ECUspare1 SG_ 2017 Debug_PVT_PEPS_GainPi_stat 1500;
BA_REL_ "GenSigTimeoutTime" BU_SG_REL_ ECUspare1 SG_ 2017 Debug_PVT_PEPS_GainP4_stat 200;
BA_REL_ "GenSigFirstTimeoutTime" BU_SG_REL_ ECUspare1 SG_ 2017 Debug_PVT_PEPS_GainP4_stat 1500;
BA_REL_ "GenSigTimeoutTime" BU_SG_REL_ ECUspare1 SG_ 2017 Debug_PVT_PEPS_GainP3_stat 200;
BA_REL_ "GenSigFirstTimeoutTime" BU_SG_REL_ ECUspare1 SG_ 2017 Debug_PVT_PEPS_GainP3_stat 1500;
BA_REL_ "GenSigTimeoutTime" BU_SG_REL_ ECUspare1 SG_ 2017 Debug_PVT_PEPS_GainP2_stat 200;
BA_REL_ "GenSigFirstTimeoutTime" BU_SG_REL_ ECUspare1 SG_ 2017 Debug_PVT_PEPS_GainP2_stat 1500;
BA_REL_ "GenSigTimeoutTime" BU_SG_REL_ ECUspare1 SG_ 2017 Debug_PVT_PEPS_GainP1_stat 200;
BA_REL_ "GenSigFirstTimeoutTime" BU_SG_REL_ ECUspare1 SG_ 2017 Debug_PVT_PEPS_GainP1_stat 1500;
BA_REL_ "GenSigTimeoutTime" BU_SG_REL_ ECUspare1 SG_ 2016 Debug_PVT_PEPS_D_AntP4ToFob 200;
BA_REL_ "GenSigFirstTimeoutTime" BU_SG_REL_ ECUspare1 SG_ 2016 Debug_PVT_PEPS_D_AntP4ToFob 1500;
BA_REL_ "GenSigTimeoutTime" BU_SG_REL_ ECUspare1 SG_ 2016 Debug_PVT_PEPS_D_AntP3ToFob 200;
BA_REL_ "GenSigFirstTimeoutTime" BU_SG_REL_ ECUspare1 SG_ 2016 Debug_PVT_PEPS_D_AntP3ToFob 1500;
BA_REL_ "GenSigTimeoutTime" BU_SG_REL_ ECUspare1 SG_ 2016 Debug_PVT_PEPS_D_AntP2ToFob 200;
BA_REL_ "GenSigFirstTimeoutTime" BU_SG_REL_ ECUspare1 SG_ 2016 Debug_PVT_PEPS_D_AntP2ToFob 1500;
BA_REL_ "GenSigTimeoutTime" BU_SG_REL_ ECUspare1 SG_ 2016 Debug_PVT_PEPS_D_AntP1ToFob 200;
BA_REL_ "GenSigFirstTimeoutTime" BU_SG_REL_ ECUspare1 SG_ 2016 Debug_PVT_PEPS_D_AntP1ToFob 1500;
BA_REL_ "GenSigTimeoutTime" BU_SG_REL_ ECUspare1 SG_ 2016 Debug_PVT_PEPS_D_AntPiToFob 200;
BA_REL_ "GenSigFirstTimeoutTime" BU_SG_REL_ ECUspare1 SG_ 2016 Debug_PVT_PEPS_D_AntPiToFob 1500;
BA_REL_ "GenSigTimeoutTime" BU_SG_REL_ ECUspare1 SG_ 2015 Debug_PVT_Fob_RF_RollingCounter 200;
BA_REL_ "GenSigFirstTimeoutTime" BU_SG_REL_ ECUspare1 SG_ 2015 Debug_PVT_Fob_RF_RollingCounter 1500;
BA_REL_ "GenSigTimeoutTime" BU_SG_REL_ ECUspare1 SG_ 2015 Debug_PVT_SCIM_RF_RollingCounter 200;
BA_REL_ "GenSigFirstTimeoutTime" BU_SG_REL_ ECUspare1 SG_ 2015 Debug_PVT_SCIM_RF_RollingCounter 1500;
BA_REL_ "GenSigFirstTimeoutTime" BU_SG_REL_ CIOM SG_ 2014 Debug_PVT_Fob_Select 1500;
BA_REL_ "GenSigTimeoutTime" BU_SG_REL_ CIOM SG_ 2014 Debug_PVT_Fob_Select 200;
BA_REL_ "GenSigTimeoutTime" BU_SG_REL_ CIOM SG_ 2014 Debug_PVT_SCIM_Ctrl_WLS3Freq 200;
BA_REL_ "GenSigFirstTimeoutTime" BU_SG_REL_ CIOM SG_ 2014 Debug_PVT_SCIM_Ctrl_WLS3Freq 1500;
BA_REL_ "GenSigTimeoutTime" BU_SG_REL_ CIOM SG_ 2014 Debug_PVT_SCIM_Ctrl_WLS3Duty 200;
BA_REL_ "GenSigFirstTimeoutTime" BU_SG_REL_ CIOM SG_ 2014 Debug_PVT_SCIM_Ctrl_WLS3Duty 1500;
BA_REL_ "GenSigTimeoutTime" BU_SG_REL_ CIOM SG_ 2014 Debug_PVT_SCIM_Ctrl_WLS3 200;
BA_REL_ "GenSigFirstTimeoutTime" BU_SG_REL_ CIOM SG_ 2014 Debug_PVT_SCIM_Ctrl_WLS3 1500;
BA_REL_ "GenSigTimeoutTime" BU_SG_REL_ CIOM SG_ 2014 Debug_PVT_SCIM_Ctrl_WLS2Freq 200;
BA_REL_ "GenSigFirstTimeoutTime" BU_SG_REL_ CIOM SG_ 2014 Debug_PVT_SCIM_Ctrl_WLS2Freq 1500;
BA_REL_ "GenSigTimeoutTime" BU_SG_REL_ CIOM SG_ 2014 Debug_PVT_SCIM_Ctrl_WLS2Duty 200;
BA_REL_ "GenSigFirstTimeoutTime" BU_SG_REL_ CIOM SG_ 2014 Debug_PVT_SCIM_Ctrl_WLS2Duty 1500;
BA_REL_ "GenSigTimeoutTime" BU_SG_REL_ CIOM SG_ 2014 Debug_PVT_SCIM_Ctrl_WLS2 200;
BA_REL_ "GenSigFirstTimeoutTime" BU_SG_REL_ CIOM SG_ 2014 Debug_PVT_SCIM_Ctrl_WLS2 1500;
BA_REL_ "GenSigTimeoutTime" BU_SG_REL_ CIOM SG_ 2014 Debug_PVT_SCIM_Ctrl_WLS1_Freq 200;
BA_REL_ "GenSigFirstTimeoutTime" BU_SG_REL_ CIOM SG_ 2014 Debug_PVT_SCIM_Ctrl_WLS1_Freq 1500;
BA_REL_ "GenSigTimeoutTime" BU_SG_REL_ CIOM SG_ 2014 Debug_PVT_SCIM_Ctrl_WLS1_Duty 200;
BA_REL_ "GenSigFirstTimeoutTime" BU_SG_REL_ CIOM SG_ 2014 Debug_PVT_SCIM_Ctrl_WLS1_Duty 1500;
BA_REL_ "GenSigTimeoutTime" BU_SG_REL_ CIOM SG_ 2014 Debug_PVT_SCIM_Ctrl_WLS1 200;
BA_REL_ "GenSigFirstTimeoutTime" BU_SG_REL_ CIOM SG_ 2014 Debug_PVT_SCIM_Ctrl_WLS1 1500;
BA_REL_ "GenSigTimeoutTime" BU_SG_REL_ CIOM SG_ 2013 Debug_PVT_SCIM_Ctrl_DAIPullUp 200;
BA_REL_ "GenSigFirstTimeoutTime" BU_SG_REL_ CIOM SG_ 2013 Debug_PVT_SCIM_Ctrl_DAIPullUp 1500;
BA_REL_ "GenSigTimeoutTime" BU_SG_REL_ CIOM SG_ 2013 Debug_PVT_SCIM_Ctrl_WHS2_Freq 200;
BA_REL_ "GenSigFirstTimeoutTime" BU_SG_REL_ CIOM SG_ 2013 Debug_PVT_SCIM_Ctrl_WHS2_Freq 1500;
BA_REL_ "GenSigTimeoutTime" BU_SG_REL_ CIOM SG_ 2013 Debug_PVT_SCIM_Ctrl_WHS2_Duty 200;
BA_REL_ "GenSigFirstTimeoutTime" BU_SG_REL_ CIOM SG_ 2013 Debug_PVT_SCIM_Ctrl_WHS2_Duty 1500;
BA_REL_ "GenSigTimeoutTime" BU_SG_REL_ CIOM SG_ 2013 Debug_PVT_SCIM_Ctrl_WHS2 200;
BA_REL_ "GenSigFirstTimeoutTime" BU_SG_REL_ CIOM SG_ 2013 Debug_PVT_SCIM_Ctrl_WHS2 1500;
BA_REL_ "GenSigTimeoutTime" BU_SG_REL_ CIOM SG_ 2013 Debug_PVT_SCIM_Ctrl_WHS1_Freq 200;
BA_REL_ "GenSigFirstTimeoutTime" BU_SG_REL_ CIOM SG_ 2013 Debug_PVT_SCIM_Ctrl_WHS1_Freq 1500;
BA_REL_ "GenSigTimeoutTime" BU_SG_REL_ CIOM SG_ 2013 Debug_PVT_SCIM_Ctrl_WHS1_Duty 200;
BA_REL_ "GenSigFirstTimeoutTime" BU_SG_REL_ CIOM SG_ 2013 Debug_PVT_SCIM_Ctrl_WHS1_Duty 1500;
BA_REL_ "GenSigTimeoutTime" BU_SG_REL_ CIOM SG_ 2013 Debug_PVT_SCIM_Ctrl_WHS1 200;
BA_REL_ "GenSigFirstTimeoutTime" BU_SG_REL_ CIOM SG_ 2013 Debug_PVT_SCIM_Ctrl_WHS1 1500;
BA_REL_ "GenSigTimeoutTime" BU_SG_REL_ CIOM SG_ 2013 Debug_PVT_SCIM_Ctrl_ParkedPullUp 200;
BA_REL_ "GenSigFirstTimeoutTime" BU_SG_REL_ CIOM SG_ 2013 Debug_PVT_SCIM_Ctrl_ParkedPullUp 1500;
BA_REL_ "GenSigTimeoutTime" BU_SG_REL_ CIOM SG_ 2013 Debug_PVT_SCIM_Ctrl_LivingPullUp 200;
BA_REL_ "GenSigFirstTimeoutTime" BU_SG_REL_ CIOM SG_ 2013 Debug_PVT_SCIM_Ctrl_LivingPullUp 1500;
BA_REL_ "GenSigTimeoutTime" BU_SG_REL_ CIOM SG_ 2013 Debug_PVT_SCIM_Ctrl_BHS4 200;
BA_REL_ "GenSigFirstTimeoutTime" BU_SG_REL_ CIOM SG_ 2013 Debug_PVT_SCIM_Ctrl_BHS4 1500;
BA_REL_ "GenSigTimeoutTime" BU_SG_REL_ CIOM SG_ 2013 Debug_PVT_SCIM_Ctrl_BHS3 200;
BA_REL_ "GenSigFirstTimeoutTime" BU_SG_REL_ CIOM SG_ 2013 Debug_PVT_SCIM_Ctrl_BHS3 1500;
BA_REL_ "GenSigTimeoutTime" BU_SG_REL_ CIOM SG_ 2013 Debug_PVT_SCIM_Ctrl_BHS2 200;
BA_REL_ "GenSigFirstTimeoutTime" BU_SG_REL_ CIOM SG_ 2013 Debug_PVT_SCIM_Ctrl_BHS2 1500;
BA_REL_ "GenSigTimeoutTime" BU_SG_REL_ CIOM SG_ 2013 Debug_PVT_SCIM_Ctrl_BHS1 200;
BA_REL_ "GenSigFirstTimeoutTime" BU_SG_REL_ CIOM SG_ 2013 Debug_PVT_SCIM_Ctrl_BHS1 1500;
BA_REL_ "GenSigTimeoutTime" BU_SG_REL_ CIOM SG_ 2013 Debug_PVT_SCIM_Ctrl_12VParked 200;
BA_REL_ "GenSigFirstTimeoutTime" BU_SG_REL_ CIOM SG_ 2013 Debug_PVT_SCIM_Ctrl_12VParked 1500;
BA_REL_ "GenSigTimeoutTime" BU_SG_REL_ CIOM SG_ 2013 Debug_PVT_SCIM_Ctrl_12VLiving 200;
BA_REL_ "GenSigFirstTimeoutTime" BU_SG_REL_ CIOM SG_ 2013 Debug_PVT_SCIM_Ctrl_12VLiving 1500;
BA_REL_ "GenSigTimeoutTime" BU_SG_REL_ CIOM SG_ 2013 Debug_PVT_SCIM_Ctrl_12VDCDC 200;
BA_REL_ "GenSigFirstTimeoutTime" BU_SG_REL_ CIOM SG_ 2013 Debug_PVT_SCIM_Ctrl_12VDCDC 1500;
BA_REL_ "GenSigTimeoutTime" BU_SG_REL_ ECUspare1 SG_ 2012 Debug_PVT_Fob_ID 200;
BA_REL_ "GenSigFirstTimeoutTime" BU_SG_REL_ ECUspare1 SG_ 2012 Debug_PVT_Fob_ID 1500;
BA_REL_ "GenSigTimeoutTime" BU_SG_REL_ ECUspare1 SG_ 2012 Debug_PVT_SCIM_RF_KeyfobSerialNb 200;
BA_REL_ "GenSigFirstTimeoutTime" BU_SG_REL_ ECUspare1 SG_ 2012 Debug_PVT_SCIM_RF_KeyfobSerialNb 1500;
BA_REL_ "GenSigTimeoutTime" BU_SG_REL_ ECUspare1 SG_ 2011 Debug_PVT_SCIM_RD_WLS2_Volt 200;
BA_REL_ "GenSigFirstTimeoutTime" BU_SG_REL_ ECUspare1 SG_ 2011 Debug_PVT_SCIM_RD_WLS2_Volt 1500;
BA_REL_ "GenSigTimeoutTime" BU_SG_REL_ ECUspare1 SG_ 2011 Debug_PVT_SCIM_RD_WLS2_Freq 200;
BA_REL_ "GenSigFirstTimeoutTime" BU_SG_REL_ ECUspare1 SG_ 2011 Debug_PVT_SCIM_RD_WLS2_Freq 1500;
BA_REL_ "GenSigTimeoutTime" BU_SG_REL_ ECUspare1 SG_ 2011 Debug_PVT_SCIM_RD_WLS2_Duty 200;
BA_REL_ "GenSigFirstTimeoutTime" BU_SG_REL_ ECUspare1 SG_ 2011 Debug_PVT_SCIM_RD_WLS2_Duty 1500;
BA_REL_ "GenSigTimeoutTime" BU_SG_REL_ ECUspare1 SG_ 2011 Debug_PVT_SCIM_RD_WLS2_Fault 200;
BA_REL_ "GenSigFirstTimeoutTime" BU_SG_REL_ ECUspare1 SG_ 2011 Debug_PVT_SCIM_RD_WLS2_Fault 1500;
BA_REL_ "GenSigTimeoutTime" BU_SG_REL_ ECUspare1 SG_ 2011 Debug_PVT_SCIM_RD_WLS1_Volt 200;
BA_REL_ "GenSigFirstTimeoutTime" BU_SG_REL_ ECUspare1 SG_ 2011 Debug_PVT_SCIM_RD_WLS1_Volt 1500;
BA_REL_ "GenSigTimeoutTime" BU_SG_REL_ ECUspare1 SG_ 2011 Debug_PVT_SCIM_RD_WLS1_Freq 200;
BA_REL_ "GenSigFirstTimeoutTime" BU_SG_REL_ ECUspare1 SG_ 2011 Debug_PVT_SCIM_RD_WLS1_Freq 1500;
BA_REL_ "GenSigTimeoutTime" BU_SG_REL_ ECUspare1 SG_ 2011 Debug_PVT_SCIM_RD_WLS1_Duty 200;
BA_REL_ "GenSigFirstTimeoutTime" BU_SG_REL_ ECUspare1 SG_ 2011 Debug_PVT_SCIM_RD_WLS1_Duty 1500;
BA_REL_ "GenSigTimeoutTime" BU_SG_REL_ ECUspare1 SG_ 2011 Debug_PVT_SCIM_RD_WLS1_Fault 200;
BA_REL_ "GenSigFirstTimeoutTime" BU_SG_REL_ ECUspare1 SG_ 2011 Debug_PVT_SCIM_RD_WLS1_Fault 1500;
BA_REL_ "GenSigTimeoutTime" BU_SG_REL_ ECUspare1 SG_ 2010 Debug_PVT_SCIM_RD_WHS2_Duty 200;
BA_REL_ "GenSigFirstTimeoutTime" BU_SG_REL_ ECUspare1 SG_ 2010 Debug_PVT_SCIM_RD_WHS2_Duty 1500;
BA_REL_ "GenSigTimeoutTime" BU_SG_REL_ ECUspare1 SG_ 2010 Debug_PVT_SCIM_RD_WHS1_Duty 200;
BA_REL_ "GenSigFirstTimeoutTime" BU_SG_REL_ ECUspare1 SG_ 2010 Debug_PVT_SCIM_RD_WHS1_Duty 1500;
BA_REL_ "GenSigTimeoutTime" BU_SG_REL_ ECUspare1 SG_ 2010 Debug_PVT_SCIM_RD_WHS2_Volt 200;
BA_REL_ "GenSigFirstTimeoutTime" BU_SG_REL_ ECUspare1 SG_ 2010 Debug_PVT_SCIM_RD_WHS2_Volt 1500;
BA_REL_ "GenSigTimeoutTime" BU_SG_REL_ ECUspare1 SG_ 2010 Debug_PVT_SCIM_RD_WHS1_Volt 200;
BA_REL_ "GenSigFirstTimeoutTime" BU_SG_REL_ ECUspare1 SG_ 2010 Debug_PVT_SCIM_RD_WHS1_Volt 1500;
BA_REL_ "GenSigTimeoutTime" BU_SG_REL_ ECUspare1 SG_ 2010 Debug_PVT_SCIM_RD_WHS2_Fault 200;
BA_REL_ "GenSigFirstTimeoutTime" BU_SG_REL_ ECUspare1 SG_ 2010 Debug_PVT_SCIM_RD_WHS2_Fault 1500;
BA_REL_ "GenSigTimeoutTime" BU_SG_REL_ ECUspare1 SG_ 2010 Debug_PVT_SCIM_RD_WHS2_Freq 200;
BA_REL_ "GenSigFirstTimeoutTime" BU_SG_REL_ ECUspare1 SG_ 2010 Debug_PVT_SCIM_RD_WHS2_Freq 1500;
BA_REL_ "GenSigTimeoutTime" BU_SG_REL_ ECUspare1 SG_ 2010 Debug_PVT_SCIM_RD_WHS1_Fault 200;
BA_REL_ "GenSigFirstTimeoutTime" BU_SG_REL_ ECUspare1 SG_ 2010 Debug_PVT_SCIM_RD_WHS1_Fault 1500;
BA_REL_ "GenSigTimeoutTime" BU_SG_REL_ ECUspare1 SG_ 2010 Debug_PVT_SCIM_RD_WHS1_Freq 200;
BA_REL_ "GenSigFirstTimeoutTime" BU_SG_REL_ ECUspare1 SG_ 2010 Debug_PVT_SCIM_RD_WHS1_Freq 1500;
BA_REL_ "GenSigTimeoutTime" BU_SG_REL_ ECUspare1 SG_ 2009 Debug_PVT_SCIM_RD_DAI2 200;
BA_REL_ "GenSigFirstTimeoutTime" BU_SG_REL_ ECUspare1 SG_ 2009 Debug_PVT_SCIM_RD_DAI2 1500;
BA_REL_ "GenSigTimeoutTime" BU_SG_REL_ ECUspare1 SG_ 2009 Debug_PVT_SCIM_RD_DAI1 200;
BA_REL_ "GenSigFirstTimeoutTime" BU_SG_REL_ ECUspare1 SG_ 2009 Debug_PVT_SCIM_RD_DAI1 1500;
BA_REL_ "GenSigTimeoutTime" BU_SG_REL_ ECUspare1 SG_ 2009 Debug_PVT_SCIM_RD_WLS3_Volt 200;
BA_REL_ "GenSigFirstTimeoutTime" BU_SG_REL_ ECUspare1 SG_ 2009 Debug_PVT_SCIM_RD_WLS3_Volt 1500;
BA_REL_ "GenSigTimeoutTime" BU_SG_REL_ ECUspare1 SG_ 2009 Debug_PVT_SCIM_RD_WLS3_Freq 200;
BA_REL_ "GenSigFirstTimeoutTime" BU_SG_REL_ ECUspare1 SG_ 2009 Debug_PVT_SCIM_RD_WLS3_Freq 1500;
BA_REL_ "GenSigTimeoutTime" BU_SG_REL_ ECUspare1 SG_ 2009 Debug_PVT_SCIM_RD_WLS3_Duty 200;
BA_REL_ "GenSigFirstTimeoutTime" BU_SG_REL_ ECUspare1 SG_ 2009 Debug_PVT_SCIM_RD_WLS3_Duty 1500;
BA_REL_ "GenSigTimeoutTime" BU_SG_REL_ ECUspare1 SG_ 2009 Debug_PVT_SCIM_RD_WLS3_Fault 200;
BA_REL_ "GenSigFirstTimeoutTime" BU_SG_REL_ ECUspare1 SG_ 2009 Debug_PVT_SCIM_RD_WLS3_Fault 1500;
BA_REL_ "GenSigFirstTimeoutTime" BU_SG_REL_ ECUspare1 SG_ 2008 Debug_PVT_SCIM_RD_ADI12 1500;
BA_REL_ "GenSigTimeoutTime" BU_SG_REL_ ECUspare1 SG_ 2008 Debug_PVT_SCIM_RD_ADI12 200;
BA_REL_ "GenSigFirstTimeoutTime" BU_SG_REL_ ECUspare1 SG_ 2008 Debug_PVT_SCIM_RD_ADI11 1500;
BA_REL_ "GenSigTimeoutTime" BU_SG_REL_ ECUspare1 SG_ 2008 Debug_PVT_SCIM_RD_ADI11 200;
BA_REL_ "GenSigFirstTimeoutTime" BU_SG_REL_ ECUspare1 SG_ 2008 Debug_PVT_SCIM_RD_ADI10 1500;
BA_REL_ "GenSigTimeoutTime" BU_SG_REL_ ECUspare1 SG_ 2008 Debug_PVT_SCIM_RD_ADI10 200;
BA_REL_ "GenSigTimeoutTime" BU_SG_REL_ ECUspare1 SG_ 2008 Debug_PVT_SCIM_RD_ADI09 200;
BA_REL_ "GenSigFirstTimeoutTime" BU_SG_REL_ ECUspare1 SG_ 2008 Debug_PVT_SCIM_RD_ADI09 1500;
BA_REL_ "GenSigFirstTimeoutTime" BU_SG_REL_ ECUspare1 SG_ 2007 Debug_PVT_SCIM_RD_ADI06 1500;
BA_REL_ "GenSigTimeoutTime" BU_SG_REL_ ECUspare1 SG_ 2007 Debug_PVT_SCIM_RD_ADI06 200;
BA_REL_ "GenSigFirstTimeoutTime" BU_SG_REL_ ECUspare1 SG_ 2007 Debug_PVT_SCIM_RD_ADI05 1500;
BA_REL_ "GenSigTimeoutTime" BU_SG_REL_ ECUspare1 SG_ 2007 Debug_PVT_SCIM_RD_ADI05 200;
BA_REL_ "GenSigTimeoutTime" BU_SG_REL_ ECUspare1 SG_ 2007 Debug_PVT_SCIM_RD_ADI04 200;
BA_REL_ "GenSigFirstTimeoutTime" BU_SG_REL_ ECUspare1 SG_ 2007 Debug_PVT_SCIM_RD_ADI04 1500;
BA_REL_ "GenSigTimeoutTime" BU_SG_REL_ ECUspare1 SG_ 2007 Debug_PVT_SCIM_RD_ADI03 200;
BA_REL_ "GenSigFirstTimeoutTime" BU_SG_REL_ ECUspare1 SG_ 2007 Debug_PVT_SCIM_RD_ADI03 1500;
BA_REL_ "GenSigTimeoutTime" BU_SG_REL_ ECUspare1 SG_ 2007 Debug_PVT_SCIM_RD_ADI02 200;
BA_REL_ "GenSigFirstTimeoutTime" BU_SG_REL_ ECUspare1 SG_ 2007 Debug_PVT_SCIM_RD_ADI02 1500;
BA_REL_ "GenSigTimeoutTime" BU_SG_REL_ ECUspare1 SG_ 2007 Debug_PVT_SCIM_RD_ADI01 200;
BA_REL_ "GenSigFirstTimeoutTime" BU_SG_REL_ ECUspare1 SG_ 2007 Debug_PVT_SCIM_RD_ADI01 1500;
BA_REL_ "GenSigFirstTimeoutTime" BU_SG_REL_ IC3 SG_ 2147484948 CalLoadTruckFrontAxle2_ISig_4 24000;
BA_REL_ "GenSigTimeoutTime" BU_SG_REL_ IC3 SG_ 2147484948 CalLoadTruckFrontAxle2_ISig_4 6000;
BA_REL_ "GenSigFirstTimeoutTime" BU_SG_REL_ CIOM SG_ 2147484948 CalLoadTruckFrontAxle2_ISig_4 24000;
BA_REL_ "GenSigTimeoutTime" BU_SG_REL_ CIOM SG_ 2147484948 CalLoadTruckFrontAxle2_ISig_4 6000;
BA_REL_ "GenSigFirstTimeoutTime" BU_SG_REL_ BBM SG_ 2147484948 CalLoadTruckFrontAxle2_ISig_4 24000;
BA_REL_ "GenSigTimeoutTime" BU_SG_REL_ BBM SG_ 2147484948 CalLoadTruckFrontAxle2_ISig_4 6000;
BA_REL_ "GenSigFirstTimeoutTime" BU_SG_REL_ CIOM SG_ 2147484948 CalLoadTrailer1Axle1_ISig_4 24000;
BA_REL_ "GenSigTimeoutTime" BU_SG_REL_ CIOM SG_ 2147484948 CalLoadTrailer1Axle1_ISig_4 6000;
BA_REL_ "GenSigFirstTimeoutTime" BU_SG_REL_ BBM SG_ 2147484948 CalLoadTrailer1Axle1_ISig_4 24000;
BA_REL_ "GenSigTimeoutTime" BU_SG_REL_ BBM SG_ 2147484948 CalLoadTrailer1Axle1_ISig_4 6000;
BA_REL_ "GenSigFirstTimeoutTime" BU_SG_REL_ IC3 SG_ 2147484948 CalLoadTrailer1Axle1_ISig_4 24000;
BA_REL_ "GenSigTimeoutTime" BU_SG_REL_ IC3 SG_ 2147484948 CalLoadTrailer1Axle1_ISig_4 6000;
BA_REL_ "GenSigFirstTimeoutTime" BU_SG_REL_ IC3 SG_ 2147484948 CalLoadTrailer2Axle6_ISig_4 24000;
BA_REL_ "GenSigTimeoutTime" BU_SG_REL_ IC3 SG_ 2147484948 CalLoadTrailer2Axle6_ISig_4 6000;
BA_REL_ "GenSigFirstTimeoutTime" BU_SG_REL_ CIOM SG_ 2147484948 CalLoadTrailer2Axle6_ISig_4 24000;
BA_REL_ "GenSigTimeoutTime" BU_SG_REL_ CIOM SG_ 2147484948 CalLoadTrailer2Axle6_ISig_4 6000;
BA_REL_ "GenSigFirstTimeoutTime" BU_SG_REL_ CIOM SG_ 2147484948 CalLoadTrailer4Axle4_ISig_4 24000;
BA_REL_ "GenSigTimeoutTime" BU_SG_REL_ CIOM SG_ 2147484948 CalLoadTrailer4Axle4_ISig_4 6000;
BA_REL_ "GenSigFirstTimeoutTime" BU_SG_REL_ IC3 SG_ 2147484948 CalLoadTrailer4Axle4_ISig_4 24000;
BA_REL_ "GenSigTimeoutTime" BU_SG_REL_ IC3 SG_ 2147484948 CalLoadTrailer4Axle4_ISig_4 6000;
BA_REL_ "GenSigFirstTimeoutTime" BU_SG_REL_ IC3 SG_ 2147484947 CalLoadTrailer5Axle1_ISig_4 24000;
BA_REL_ "GenSigTimeoutTime" BU_SG_REL_ IC3 SG_ 2147484947 CalLoadTrailer5Axle1_ISig_4 6000;
BA_REL_ "GenSigFirstTimeoutTime" BU_SG_REL_ CIOM SG_ 2147484947 CalLoadTrailer5Axle1_ISig_4 24000;
BA_REL_ "GenSigTimeoutTime" BU_SG_REL_ CIOM SG_ 2147484947 CalLoadTrailer5Axle1_ISig_4 6000;
BA_REL_ "GenSigFirstTimeoutTime" BU_SG_REL_ CIOM SG_ 2147484947 CalLoadTrailer3Axle1_ISig_4 24000;
BA_REL_ "GenSigTimeoutTime" BU_SG_REL_ CIOM SG_ 2147484947 CalLoadTrailer3Axle1_ISig_4 6000;
BA_REL_ "GenSigFirstTimeoutTime" BU_SG_REL_ IC3 SG_ 2147484947 CalLoadTrailer3Axle1_ISig_4 24000;
BA_REL_ "GenSigTimeoutTime" BU_SG_REL_ IC3 SG_ 2147484947 CalLoadTrailer3Axle1_ISig_4 6000;
BA_REL_ "GenSigFirstTimeoutTime" BU_SG_REL_ CIOM SG_ 2147484947 CalLoadTrailer5Axle5_ISig_4 24000;
BA_REL_ "GenSigTimeoutTime" BU_SG_REL_ CIOM SG_ 2147484947 CalLoadTrailer5Axle5_ISig_4 6000;
BA_REL_ "GenSigFirstTimeoutTime" BU_SG_REL_ IC3 SG_ 2147484947 CalLoadTrailer5Axle5_ISig_4 24000;
BA_REL_ "GenSigTimeoutTime" BU_SG_REL_ IC3 SG_ 2147484947 CalLoadTrailer5Axle5_ISig_4 6000;
BA_REL_ "GenSigFirstTimeoutTime" BU_SG_REL_ IC3 SG_ 2147484947 CalLoadTrailer5Axle4_ISig_4 24000;
BA_REL_ "GenSigTimeoutTime" BU_SG_REL_ IC3 SG_ 2147484947 CalLoadTrailer5Axle4_ISig_4 6000;
BA_REL_ "GenSigFirstTimeoutTime" BU_SG_REL_ CIOM SG_ 2147484947 CalLoadTrailer5Axle4_ISig_4 24000;
BA_REL_ "GenSigTimeoutTime" BU_SG_REL_ CIOM SG_ 2147484947 CalLoadTrailer5Axle4_ISig_4 6000;
BA_REL_ "GenSigFirstTimeoutTime" BU_SG_REL_ IC3 SG_ 2147484946 VehCombHeaviestBoogie_VehicleID 24000;
BA_REL_ "GenSigTimeoutTime" BU_SG_REL_ IC3 SG_ 2147484946 VehCombHeaviestBoogie_VehicleID 6000;
BA_REL_ "GenSigFirstTimeoutTime" BU_SG_REL_ IC3 SG_ 2147484946 VehCombHeaviestBoogie_Load 24000;
BA_REL_ "GenSigTimeoutTime" BU_SG_REL_ IC3 SG_ 2147484946 VehCombHeaviestBoogie_Load 6000;
BA_REL_ "GenSigFirstTimeoutTime" BU_SG_REL_ IC3 SG_ 2147484946 VehCombHeaviestBoogie_Position 24000;
BA_REL_ "GenSigTimeoutTime" BU_SG_REL_ IC3 SG_ 2147484946 VehCombHeaviestBoogie_Position 6000;
BA_REL_ "GenSigFirstTimeoutTime" BU_SG_REL_ IC3 SG_ 2147484946 VehCombHeaviestAxle_Position 24000;
BA_REL_ "GenSigTimeoutTime" BU_SG_REL_ IC3 SG_ 2147484946 VehCombHeaviestAxle_Position 6000;
BA_REL_ "GenSigFirstTimeoutTime" BU_SG_REL_ IC3 SG_ 2147484946 VehCombHeaviestAxle_Load 24000;
BA_REL_ "GenSigTimeoutTime" BU_SG_REL_ IC3 SG_ 2147484946 VehCombHeaviestAxle_Load 6000;
BA_REL_ "GenSigFirstTimeoutTime" BU_SG_REL_ IC3 SG_ 2147484946 VehCombHeaviestAxle_VehicleID 24000;
BA_REL_ "GenSigTimeoutTime" BU_SG_REL_ IC3 SG_ 2147484946 VehCombHeaviestAxle_VehicleID 6000;
BA_REL_ "GenSigFirstTimeoutTime" BU_SG_REL_ CIOM SG_ 2147484945 CalLoadTrailer5Axle3_ISig_4 24000;
BA_REL_ "GenSigTimeoutTime" BU_SG_REL_ CIOM SG_ 2147484945 CalLoadTrailer5Axle3_ISig_4 6000;
BA_REL_ "GenSigFirstTimeoutTime" BU_SG_REL_ IC3 SG_ 2147484945 CalLoadTrailer5Axle3_ISig_4 24000;
BA_REL_ "GenSigTimeoutTime" BU_SG_REL_ IC3 SG_ 2147484945 CalLoadTrailer5Axle3_ISig_4 6000;
BA_REL_ "GenSigFirstTimeoutTime" BU_SG_REL_ CIOM SG_ 2147484945 CalLoadTrailer4Axle1_ISig_4 24000;
BA_REL_ "GenSigTimeoutTime" BU_SG_REL_ CIOM SG_ 2147484945 CalLoadTrailer4Axle1_ISig_4 6000;
BA_REL_ "GenSigFirstTimeoutTime" BU_SG_REL_ IC3 SG_ 2147484945 CalLoadTrailer4Axle1_ISig_4 24000;
BA_REL_ "GenSigTimeoutTime" BU_SG_REL_ IC3 SG_ 2147484945 CalLoadTrailer4Axle1_ISig_4 6000;
BA_REL_ "GenSigFirstTimeoutTime" BU_SG_REL_ CIOM SG_ 2147484945 CalLoadTrailer2Axle5_ISig_4 24000;
BA_REL_ "GenSigTimeoutTime" BU_SG_REL_ CIOM SG_ 2147484945 CalLoadTrailer2Axle5_ISig_4 6000;
BA_REL_ "GenSigFirstTimeoutTime" BU_SG_REL_ IC3 SG_ 2147484945 CalLoadTrailer2Axle5_ISig_4 24000;
BA_REL_ "GenSigTimeoutTime" BU_SG_REL_ IC3 SG_ 2147484945 CalLoadTrailer2Axle5_ISig_4 6000;
BA_REL_ "GenSigFirstTimeoutTime" BU_SG_REL_ CIOM SG_ 2147484945 CalLoadTrailer3Axle3_ISig_4 24000;
BA_REL_ "GenSigTimeoutTime" BU_SG_REL_ CIOM SG_ 2147484945 CalLoadTrailer3Axle3_ISig_4 6000;
BA_REL_ "GenSigFirstTimeoutTime" BU_SG_REL_ IC3 SG_ 2147484945 CalLoadTrailer3Axle3_ISig_4 24000;
BA_REL_ "GenSigTimeoutTime" BU_SG_REL_ IC3 SG_ 2147484945 CalLoadTrailer3Axle3_ISig_4 6000;
BA_REL_ "GenSigFirstTimeoutTime" BU_SG_REL_ IC3 SG_ 2147484944 CalLoadTrailer1Axle3_ISig_4 24000;
BA_REL_ "GenSigTimeoutTime" BU_SG_REL_ IC3 SG_ 2147484944 CalLoadTrailer1Axle3_ISig_4 6000;
BA_REL_ "GenSigFirstTimeoutTime" BU_SG_REL_ BBM SG_ 2147484944 CalLoadTrailer1Axle3_ISig_4 24000;
BA_REL_ "GenSigTimeoutTime" BU_SG_REL_ BBM SG_ 2147484944 CalLoadTrailer1Axle3_ISig_4 6000;
BA_REL_ "GenSigFirstTimeoutTime" BU_SG_REL_ CIOM SG_ 2147484944 CalLoadTrailer1Axle3_ISig_4 24000;
BA_REL_ "GenSigTimeoutTime" BU_SG_REL_ CIOM SG_ 2147484944 CalLoadTrailer1Axle3_ISig_4 6000;
BA_REL_ "GenSigFirstTimeoutTime" BU_SG_REL_ IC3 SG_ 2147484944 CalLoadTrailer4Axle5_ISig_4 24000;
BA_REL_ "GenSigTimeoutTime" BU_SG_REL_ IC3 SG_ 2147484944 CalLoadTrailer4Axle5_ISig_4 6000;
BA_REL_ "GenSigFirstTimeoutTime" BU_SG_REL_ CIOM SG_ 2147484944 CalLoadTrailer4Axle5_ISig_4 24000;
BA_REL_ "GenSigTimeoutTime" BU_SG_REL_ CIOM SG_ 2147484944 CalLoadTrailer4Axle5_ISig_4 6000;
BA_REL_ "GenSigFirstTimeoutTime" BU_SG_REL_ CIOM SG_ 2147484944 CalLoadTruckRearAxle1_ISig_4 24000;
BA_REL_ "GenSigTimeoutTime" BU_SG_REL_ CIOM SG_ 2147484944 CalLoadTruckRearAxle1_ISig_4 6000;
BA_REL_ "GenSigFirstTimeoutTime" BU_SG_REL_ BBM SG_ 2147484944 CalLoadTruckRearAxle1_ISig_4 24000;
BA_REL_ "GenSigTimeoutTime" BU_SG_REL_ BBM SG_ 2147484944 CalLoadTruckRearAxle1_ISig_4 6000;
BA_REL_ "GenSigFirstTimeoutTime" BU_SG_REL_ IC3 SG_ 2147484944 CalLoadTruckRearAxle1_ISig_4 24000;
BA_REL_ "GenSigTimeoutTime" BU_SG_REL_ IC3 SG_ 2147484944 CalLoadTruckRearAxle1_ISig_4 6000;
BA_REL_ "GenSigFirstTimeoutTime" BU_SG_REL_ IC3 SG_ 2147484944 CalLoadTruckFrontAxle1_ISig_4 24000;
BA_REL_ "GenSigTimeoutTime" BU_SG_REL_ IC3 SG_ 2147484944 CalLoadTruckFrontAxle1_ISig_4 6000;
BA_REL_ "GenSigFirstTimeoutTime" BU_SG_REL_ BBM SG_ 2147484944 CalLoadTruckFrontAxle1_ISig_4 24000;
BA_REL_ "GenSigTimeoutTime" BU_SG_REL_ BBM SG_ 2147484944 CalLoadTruckFrontAxle1_ISig_4 6000;
BA_REL_ "GenSigFirstTimeoutTime" BU_SG_REL_ CIOM SG_ 2147484944 CalLoadTruckFrontAxle1_ISig_4 24000;
BA_REL_ "GenSigTimeoutTime" BU_SG_REL_ CIOM SG_ 2147484944 CalLoadTruckFrontAxle1_ISig_4 6000;
BA_REL_ "GenSigFirstTimeoutTime" BU_SG_REL_ IC3 SG_ 2147485038 TruckFrontAxle2_Liftable 24000;
BA_REL_ "GenSigTimeoutTime" BU_SG_REL_ IC3 SG_ 2147485038 TruckFrontAxle2_Liftable 6000;
BA_REL_ "GenSigFirstTimeoutTime" BU_SG_REL_ IC3 SG_ 2147485038 TruckRearAxle3_Liftable 24000;
BA_REL_ "GenSigTimeoutTime" BU_SG_REL_ IC3 SG_ 2147485038 TruckRearAxle3_Liftable 6000;
BA_REL_ "GenSigFirstTimeoutTime" BU_SG_REL_ IC3 SG_ 2147485038 TruckRearAxle2_Liftable 24000;
BA_REL_ "GenSigTimeoutTime" BU_SG_REL_ IC3 SG_ 2147485038 TruckRearAxle2_Liftable 6000;
BA_REL_ "GenSigFirstTimeoutTime" BU_SG_REL_ IC3 SG_ 2147485038 TruckRearAxle2_Suspension 24000;
BA_REL_ "GenSigTimeoutTime" BU_SG_REL_ IC3 SG_ 2147485038 TruckRearAxle2_Suspension 6000;
BA_REL_ "GenSigFirstTimeoutTime" BU_SG_REL_ IC3 SG_ 2147485038 TruckFrontAxle1_Liftable 24000;
BA_REL_ "GenSigTimeoutTime" BU_SG_REL_ IC3 SG_ 2147485038 TruckFrontAxle1_Liftable 6000;
BA_REL_ "GenSigFirstTimeoutTime" BU_SG_REL_ IC3 SG_ 2147485038 TruckRearAxle1_Driven 24000;
BA_REL_ "GenSigTimeoutTime" BU_SG_REL_ IC3 SG_ 2147485038 TruckRearAxle1_Driven 6000;
BA_REL_ "GenSigFirstTimeoutTime" BU_SG_REL_ IC3 SG_ 2147485038 TruckFrontAxle2_Driven 24000;
BA_REL_ "GenSigTimeoutTime" BU_SG_REL_ IC3 SG_ 2147485038 TruckFrontAxle2_Driven 6000;
BA_REL_ "GenSigFirstTimeoutTime" BU_SG_REL_ IC3 SG_ 2147485038 TruckRearAxle1_Suspension 24000;
BA_REL_ "GenSigTimeoutTime" BU_SG_REL_ IC3 SG_ 2147485038 TruckRearAxle1_Suspension 6000;
BA_REL_ "GenSigFirstTimeoutTime" BU_SG_REL_ IC3 SG_ 2147485038 TruckRearAxle2_Driven 24000;
BA_REL_ "GenSigTimeoutTime" BU_SG_REL_ IC3 SG_ 2147485038 TruckRearAxle2_Driven 6000;
BA_REL_ "GenSigFirstTimeoutTime" BU_SG_REL_ IC3 SG_ 2147485038 TruckFrontAxle2_Suspension 24000;
BA_REL_ "GenSigTimeoutTime" BU_SG_REL_ IC3 SG_ 2147485038 TruckFrontAxle2_Suspension 6000;
BA_REL_ "GenSigFirstTimeoutTime" BU_SG_REL_ IC3 SG_ 2147485038 TruckRearAxle1_Liftable 24000;
BA_REL_ "GenSigTimeoutTime" BU_SG_REL_ IC3 SG_ 2147485038 TruckRearAxle1_Liftable 6000;
BA_REL_ "GenSigFirstTimeoutTime" BU_SG_REL_ IC3 SG_ 2147485038 TruckFrontAxle1_Suspension 24000;
BA_REL_ "GenSigTimeoutTime" BU_SG_REL_ IC3 SG_ 2147485038 TruckFrontAxle1_Suspension 6000;
BA_REL_ "GenSigFirstTimeoutTime" BU_SG_REL_ IC3 SG_ 2147485038 TruckRearAxle3_Driven 24000;
BA_REL_ "GenSigTimeoutTime" BU_SG_REL_ IC3 SG_ 2147485038 TruckRearAxle3_Driven 6000;
BA_REL_ "GenSigFirstTimeoutTime" BU_SG_REL_ IC3 SG_ 2147485038 TruckFrontAxle1_Driven 24000;
BA_REL_ "GenSigTimeoutTime" BU_SG_REL_ IC3 SG_ 2147485038 TruckFrontAxle1_Driven 6000;
BA_REL_ "GenSigFirstTimeoutTime" BU_SG_REL_ IC3 SG_ 2147485038 TruckRearAxle3_Suspension 24000;
BA_REL_ "GenSigTimeoutTime" BU_SG_REL_ IC3 SG_ 2147485038 TruckRearAxle3_Suspension 6000;
BA_REL_ "GenSigFirstTimeoutTime" BU_SG_REL_ CIOM SG_ 2147485031 Trail2NoOfFrontAxles_ISig_4 24000;
BA_REL_ "GenSigTimeoutTime" BU_SG_REL_ CIOM SG_ 2147485031 Trail2NoOfFrontAxles_ISig_4 6000;
BA_REL_ "GenSigFirstTimeoutTime" BU_SG_REL_ IC3 SG_ 2147485031 Trail2NoOfFrontAxles_ISig_4 24000;
BA_REL_ "GenSigTimeoutTime" BU_SG_REL_ IC3 SG_ 2147485031 Trail2NoOfFrontAxles_ISig_4 6000;
BA_REL_ "GenSigFirstTimeoutTime" BU_SG_REL_ IC3 SG_ 2147485031 Trail2NoOfAxles_ISig_4 24000;
BA_REL_ "GenSigTimeoutTime" BU_SG_REL_ IC3 SG_ 2147485031 Trail2NoOfAxles_ISig_4 6000;
BA_REL_ "GenSigFirstTimeoutTime" BU_SG_REL_ CIOM SG_ 2147485031 Trail2NoOfAxles_ISig_4 24000;
BA_REL_ "GenSigTimeoutTime" BU_SG_REL_ CIOM SG_ 2147485031 Trail2NoOfAxles_ISig_4 6000;
BA_REL_ "GenSigFirstTimeoutTime" BU_SG_REL_ CIOM SG_ 2147485031 Trail4NoOfFrontAxles_ISig_4 24000;
BA_REL_ "GenSigTimeoutTime" BU_SG_REL_ CIOM SG_ 2147485031 Trail4NoOfFrontAxles_ISig_4 6000;
BA_REL_ "GenSigFirstTimeoutTime" BU_SG_REL_ IC3 SG_ 2147485031 Trail4NoOfFrontAxles_ISig_4 24000;
BA_REL_ "GenSigTimeoutTime" BU_SG_REL_ IC3 SG_ 2147485031 Trail4NoOfFrontAxles_ISig_4 6000;
BA_REL_ "GenSigFirstTimeoutTime" BU_SG_REL_ CIOM SG_ 2147485031 Trail1NoOfAxles_ISig_4 24000;
BA_REL_ "GenSigTimeoutTime" BU_SG_REL_ CIOM SG_ 2147485031 Trail1NoOfAxles_ISig_4 6000;
BA_REL_ "GenSigFirstTimeoutTime" BU_SG_REL_ IC3 SG_ 2147485031 Trail1NoOfAxles_ISig_4 24000;
BA_REL_ "GenSigTimeoutTime" BU_SG_REL_ IC3 SG_ 2147485031 Trail1NoOfAxles_ISig_4 6000;
BA_REL_ "GenSigFirstTimeoutTime" BU_SG_REL_ IC3 SG_ 2147485031 Trail3NoOfAxles_ISig_4 24000;
BA_REL_ "GenSigTimeoutTime" BU_SG_REL_ IC3 SG_ 2147485031 Trail3NoOfAxles_ISig_4 6000;
BA_REL_ "GenSigFirstTimeoutTime" BU_SG_REL_ CIOM SG_ 2147485031 Trail3NoOfAxles_ISig_4 24000;
BA_REL_ "GenSigTimeoutTime" BU_SG_REL_ CIOM SG_ 2147485031 Trail3NoOfAxles_ISig_4 6000;
BA_REL_ "GenSigFirstTimeoutTime" BU_SG_REL_ IC3 SG_ 2147485031 Trail4NoOfAxles_ISig_4 24000;
BA_REL_ "GenSigTimeoutTime" BU_SG_REL_ IC3 SG_ 2147485031 Trail4NoOfAxles_ISig_4 6000;
BA_REL_ "GenSigFirstTimeoutTime" BU_SG_REL_ CIOM SG_ 2147485031 Trail4NoOfAxles_ISig_4 24000;
BA_REL_ "GenSigTimeoutTime" BU_SG_REL_ CIOM SG_ 2147485031 Trail4NoOfAxles_ISig_4 6000;
BA_REL_ "GenSigFirstTimeoutTime" BU_SG_REL_ IC3 SG_ 2147485031 Trail1NoOfFrontAxles_ISig_4 24000;
BA_REL_ "GenSigTimeoutTime" BU_SG_REL_ IC3 SG_ 2147485031 Trail1NoOfFrontAxles_ISig_4 6000;
BA_REL_ "GenSigFirstTimeoutTime" BU_SG_REL_ CIOM SG_ 2147485031 Trail1NoOfFrontAxles_ISig_4 24000;
BA_REL_ "GenSigTimeoutTime" BU_SG_REL_ CIOM SG_ 2147485031 Trail1NoOfFrontAxles_ISig_4 6000;
BA_REL_ "GenSigFirstTimeoutTime" BU_SG_REL_ CIOM SG_ 2147485031 Trail5NoOfFrontAxles_ISig_4 24000;
BA_REL_ "GenSigTimeoutTime" BU_SG_REL_ CIOM SG_ 2147485031 Trail5NoOfFrontAxles_ISig_4 6000;
BA_REL_ "GenSigFirstTimeoutTime" BU_SG_REL_ IC3 SG_ 2147485031 Trail5NoOfFrontAxles_ISig_4 24000;
BA_REL_ "GenSigTimeoutTime" BU_SG_REL_ IC3 SG_ 2147485031 Trail5NoOfFrontAxles_ISig_4 6000;
BA_REL_ "GenSigFirstTimeoutTime" BU_SG_REL_ CIOM SG_ 2147485031 Trail5NoOfAxles_ISig_4 24000;
BA_REL_ "GenSigTimeoutTime" BU_SG_REL_ CIOM SG_ 2147485031 Trail5NoOfAxles_ISig_4 6000;
BA_REL_ "GenSigFirstTimeoutTime" BU_SG_REL_ IC3 SG_ 2147485031 Trail5NoOfAxles_ISig_4 24000;
BA_REL_ "GenSigTimeoutTime" BU_SG_REL_ IC3 SG_ 2147485031 Trail5NoOfAxles_ISig_4 6000;
BA_REL_ "GenSigFirstTimeoutTime" BU_SG_REL_ CIOM SG_ 2147485031 Trail3NoOfFrontAxles_ISig_4 24000;
BA_REL_ "GenSigTimeoutTime" BU_SG_REL_ CIOM SG_ 2147485031 Trail3NoOfFrontAxles_ISig_4 6000;
BA_REL_ "GenSigFirstTimeoutTime" BU_SG_REL_ IC3 SG_ 2147485031 Trail3NoOfFrontAxles_ISig_4 24000;
BA_REL_ "GenSigTimeoutTime" BU_SG_REL_ IC3 SG_ 2147485031 Trail3NoOfFrontAxles_ISig_4 6000;
BA_REL_ "GenSigFirstTimeoutTime" BU_SG_REL_ CIOM SG_ 2147485028 Trail3Type_TrailType_ISig_4 24000;
BA_REL_ "GenSigTimeoutTime" BU_SG_REL_ CIOM SG_ 2147485028 Trail3Type_TrailType_ISig_4 6000;
BA_REL_ "GenSigFirstTimeoutTime" BU_SG_REL_ IC3 SG_ 2147485028 Trail3Type_TrailType_ISig_4 24000;
BA_REL_ "GenSigTimeoutTime" BU_SG_REL_ IC3 SG_ 2147485028 Trail3Type_TrailType_ISig_4 6000;
BA_REL_ "GenSigFirstTimeoutTime" BU_SG_REL_ CIOM SG_ 2147485028 Trail5Axle1Type_ISig_4 24000;
BA_REL_ "GenSigTimeoutTime" BU_SG_REL_ CIOM SG_ 2147485028 Trail5Axle1Type_ISig_4 6000;
BA_REL_ "GenSigFirstTimeoutTime" BU_SG_REL_ IC3 SG_ 2147485028 Trail5Axle1Type_ISig_4 24000;
BA_REL_ "GenSigTimeoutTime" BU_SG_REL_ IC3 SG_ 2147485028 Trail5Axle1Type_ISig_4 6000;
BA_REL_ "GenSigFirstTimeoutTime" BU_SG_REL_ CIOM SG_ 2147485028 Trail3Type_Towing_ISig_4 24000;
BA_REL_ "GenSigTimeoutTime" BU_SG_REL_ CIOM SG_ 2147485028 Trail3Type_Towing_ISig_4 6000;
BA_REL_ "GenSigFirstTimeoutTime" BU_SG_REL_ IC3 SG_ 2147485028 Trail3Type_Towing_ISig_4 24000;
BA_REL_ "GenSigTimeoutTime" BU_SG_REL_ IC3 SG_ 2147485028 Trail3Type_Towing_ISig_4 6000;
BA_REL_ "GenSigFirstTimeoutTime" BU_SG_REL_ CIOM SG_ 2147485028 Trail5Axle4Type_ISig_4 24000;
BA_REL_ "GenSigTimeoutTime" BU_SG_REL_ CIOM SG_ 2147485028 Trail5Axle4Type_ISig_4 6000;
BA_REL_ "GenSigFirstTimeoutTime" BU_SG_REL_ IC3 SG_ 2147485028 Trail5Axle4Type_ISig_4 24000;
BA_REL_ "GenSigTimeoutTime" BU_SG_REL_ IC3 SG_ 2147485028 Trail5Axle4Type_ISig_4 6000;
BA_REL_ "GenSigFirstTimeoutTime" BU_SG_REL_ CIOM SG_ 2147485028 Trail5Axle3Type_ISig_4 24000;
BA_REL_ "GenSigTimeoutTime" BU_SG_REL_ CIOM SG_ 2147485028 Trail5Axle3Type_ISig_4 6000;
BA_REL_ "GenSigFirstTimeoutTime" BU_SG_REL_ IC3 SG_ 2147485028 Trail5Axle3Type_ISig_4 24000;
BA_REL_ "GenSigTimeoutTime" BU_SG_REL_ IC3 SG_ 2147485028 Trail5Axle3Type_ISig_4 6000;
BA_REL_ "GenSigFirstTimeoutTime" BU_SG_REL_ CIOM SG_ 2147485028 Trail4Type_Towing_ISig_4 24000;
BA_REL_ "GenSigTimeoutTime" BU_SG_REL_ CIOM SG_ 2147485028 Trail4Type_Towing_ISig_4 6000;
BA_REL_ "GenSigFirstTimeoutTime" BU_SG_REL_ IC3 SG_ 2147485028 Trail4Type_Towing_ISig_4 24000;
BA_REL_ "GenSigTimeoutTime" BU_SG_REL_ IC3 SG_ 2147485028 Trail4Type_Towing_ISig_4 6000;
BA_REL_ "GenSigFirstTimeoutTime" BU_SG_REL_ CIOM SG_ 2147485028 Trail4Type_TrailType_ISig_4 24000;
BA_REL_ "GenSigTimeoutTime" BU_SG_REL_ CIOM SG_ 2147485028 Trail4Type_TrailType_ISig_4 6000;
BA_REL_ "GenSigFirstTimeoutTime" BU_SG_REL_ IC3 SG_ 2147485028 Trail4Type_TrailType_ISig_4 24000;
BA_REL_ "GenSigTimeoutTime" BU_SG_REL_ IC3 SG_ 2147485028 Trail4Type_TrailType_ISig_4 6000;
BA_REL_ "GenSigFirstTimeoutTime" BU_SG_REL_ CIOM SG_ 2147485028 Trail5Axle2Type_ISig_4 24000;
BA_REL_ "GenSigTimeoutTime" BU_SG_REL_ CIOM SG_ 2147485028 Trail5Axle2Type_ISig_4 6000;
BA_REL_ "GenSigFirstTimeoutTime" BU_SG_REL_ IC3 SG_ 2147485028 Trail5Axle2Type_ISig_4 24000;
BA_REL_ "GenSigTimeoutTime" BU_SG_REL_ IC3 SG_ 2147485028 Trail5Axle2Type_ISig_4 6000;
BA_REL_ "GenSigFirstTimeoutTime" BU_SG_REL_ IC3 SG_ 2147485028 Trail5Type_TrailType_ISig_4 24000;
BA_REL_ "GenSigTimeoutTime" BU_SG_REL_ IC3 SG_ 2147485028 Trail5Type_TrailType_ISig_4 6000;
BA_REL_ "GenSigFirstTimeoutTime" BU_SG_REL_ CIOM SG_ 2147485028 Trail5Type_TrailType_ISig_4 24000;
BA_REL_ "GenSigTimeoutTime" BU_SG_REL_ CIOM SG_ 2147485028 Trail5Type_TrailType_ISig_4 6000;
BA_REL_ "GenSigFirstTimeoutTime" BU_SG_REL_ CIOM SG_ 2147485028 Trail5Axle5Type_ISig_4 24000;
BA_REL_ "GenSigTimeoutTime" BU_SG_REL_ CIOM SG_ 2147485028 Trail5Axle5Type_ISig_4 6000;
BA_REL_ "GenSigFirstTimeoutTime" BU_SG_REL_ IC3 SG_ 2147485028 Trail5Axle5Type_ISig_4 24000;
BA_REL_ "GenSigTimeoutTime" BU_SG_REL_ IC3 SG_ 2147485028 Trail5Axle5Type_ISig_4 6000;
BA_REL_ "GenSigFirstTimeoutTime" BU_SG_REL_ IC3 SG_ 2147485028 Trail5Type_Towing_ISig_4 24000;
BA_REL_ "GenSigTimeoutTime" BU_SG_REL_ IC3 SG_ 2147485028 Trail5Type_Towing_ISig_4 6000;
BA_REL_ "GenSigFirstTimeoutTime" BU_SG_REL_ CIOM SG_ 2147485028 Trail5Type_Towing_ISig_4 24000;
BA_REL_ "GenSigTimeoutTime" BU_SG_REL_ CIOM SG_ 2147485028 Trail5Type_Towing_ISig_4 6000;
BA_REL_ "GenSigFirstTimeoutTime" BU_SG_REL_ IC3 SG_ 2147485028 Trail5Axle6Type_ISig_4 24000;
BA_REL_ "GenSigTimeoutTime" BU_SG_REL_ IC3 SG_ 2147485028 Trail5Axle6Type_ISig_4 6000;
BA_REL_ "GenSigFirstTimeoutTime" BU_SG_REL_ CIOM SG_ 2147485028 Trail5Axle6Type_ISig_4 24000;
BA_REL_ "GenSigTimeoutTime" BU_SG_REL_ CIOM SG_ 2147485028 Trail5Axle6Type_ISig_4 6000;
BA_REL_ "GenSigFirstTimeoutTime" BU_SG_REL_ CIOM SG_ 2147485026 Trail2Axle4Type_ISig_4 24000;
BA_REL_ "GenSigTimeoutTime" BU_SG_REL_ CIOM SG_ 2147485026 Trail2Axle4Type_ISig_4 6000;
BA_REL_ "GenSigFirstTimeoutTime" BU_SG_REL_ IC3 SG_ 2147485026 Trail2Axle4Type_ISig_4 24000;
BA_REL_ "GenSigTimeoutTime" BU_SG_REL_ IC3 SG_ 2147485026 Trail2Axle4Type_ISig_4 6000;
BA_REL_ "GenSigFirstTimeoutTime" BU_SG_REL_ CIOM SG_ 2147485026 Trail4Axle1Type_ISig_4 24000;
BA_REL_ "GenSigTimeoutTime" BU_SG_REL_ CIOM SG_ 2147485026 Trail4Axle1Type_ISig_4 6000;
BA_REL_ "GenSigFirstTimeoutTime" BU_SG_REL_ IC3 SG_ 2147485026 Trail4Axle1Type_ISig_4 24000;
BA_REL_ "GenSigTimeoutTime" BU_SG_REL_ IC3 SG_ 2147485026 Trail4Axle1Type_ISig_4 6000;
BA_REL_ "GenSigFirstTimeoutTime" BU_SG_REL_ IC3 SG_ 2147485026 Trail2Axle3Type_ISig_4 24000;
BA_REL_ "GenSigTimeoutTime" BU_SG_REL_ IC3 SG_ 2147485026 Trail2Axle3Type_ISig_4 6000;
BA_REL_ "GenSigFirstTimeoutTime" BU_SG_REL_ CIOM SG_ 2147485026 Trail2Axle3Type_ISig_4 24000;
BA_REL_ "GenSigTimeoutTime" BU_SG_REL_ CIOM SG_ 2147485026 Trail2Axle3Type_ISig_4 6000;
BA_REL_ "GenSigFirstTimeoutTime" BU_SG_REL_ IC3 SG_ 2147485026 Trail1Axle6Type_ISig_4 24000;
BA_REL_ "GenSigTimeoutTime" BU_SG_REL_ IC3 SG_ 2147485026 Trail1Axle6Type_ISig_4 6000;
BA_REL_ "GenSigFirstTimeoutTime" BU_SG_REL_ CIOM SG_ 2147485026 Trail1Axle6Type_ISig_4 24000;
BA_REL_ "GenSigTimeoutTime" BU_SG_REL_ CIOM SG_ 2147485026 Trail1Axle6Type_ISig_4 6000;
BA_REL_ "GenSigFirstTimeoutTime" BU_SG_REL_ CIOM SG_ 2147485026 Trail1Type_Towing_ISig_4 24000;
BA_REL_ "GenSigTimeoutTime" BU_SG_REL_ CIOM SG_ 2147485026 Trail1Type_Towing_ISig_4 6000;
BA_REL_ "GenSigFirstTimeoutTime" BU_SG_REL_ IC3 SG_ 2147485026 Trail1Type_Towing_ISig_4 24000;
BA_REL_ "GenSigTimeoutTime" BU_SG_REL_ IC3 SG_ 2147485026 Trail1Type_Towing_ISig_4 6000;
BA_REL_ "GenSigFirstTimeoutTime" BU_SG_REL_ IC3 SG_ 2147485026 Trail3Axle5Type_ISig_4 24000;
BA_REL_ "GenSigTimeoutTime" BU_SG_REL_ IC3 SG_ 2147485026 Trail3Axle5Type_ISig_4 6000;
BA_REL_ "GenSigFirstTimeoutTime" BU_SG_REL_ CIOM SG_ 2147485026 Trail3Axle5Type_ISig_4 24000;
BA_REL_ "GenSigTimeoutTime" BU_SG_REL_ CIOM SG_ 2147485026 Trail3Axle5Type_ISig_4 6000;
BA_REL_ "GenSigFirstTimeoutTime" BU_SG_REL_ IC3 SG_ 2147485026 Trail1Axle5Type_ISig_4 24000;
BA_REL_ "GenSigTimeoutTime" BU_SG_REL_ IC3 SG_ 2147485026 Trail1Axle5Type_ISig_4 6000;
BA_REL_ "GenSigFirstTimeoutTime" BU_SG_REL_ CIOM SG_ 2147485026 Trail1Axle5Type_ISig_4 24000;
BA_REL_ "GenSigTimeoutTime" BU_SG_REL_ CIOM SG_ 2147485026 Trail1Axle5Type_ISig_4 6000;
BA_REL_ "GenSigFirstTimeoutTime" BU_SG_REL_ CIOM SG_ 2147485026 Trail3Axle4Type_ISig_4 24000;
BA_REL_ "GenSigTimeoutTime" BU_SG_REL_ CIOM SG_ 2147485026 Trail3Axle4Type_ISig_4 6000;
BA_REL_ "GenSigFirstTimeoutTime" BU_SG_REL_ IC3 SG_ 2147485026 Trail3Axle4Type_ISig_4 24000;
BA_REL_ "GenSigTimeoutTime" BU_SG_REL_ IC3 SG_ 2147485026 Trail3Axle4Type_ISig_4 6000;
BA_REL_ "GenSigFirstTimeoutTime" BU_SG_REL_ CIOM SG_ 2147485026 Trail4Axle4Type_ISig_4 24000;
BA_REL_ "GenSigTimeoutTime" BU_SG_REL_ CIOM SG_ 2147485026 Trail4Axle4Type_ISig_4 6000;
BA_REL_ "GenSigFirstTimeoutTime" BU_SG_REL_ IC3 SG_ 2147485026 Trail4Axle4Type_ISig_4 24000;
BA_REL_ "GenSigTimeoutTime" BU_SG_REL_ IC3 SG_ 2147485026 Trail4Axle4Type_ISig_4 6000;
BA_REL_ "GenSigFirstTimeoutTime" BU_SG_REL_ IC3 SG_ 2147485026 Trail4Axle3Type_ISig_4 24000;
BA_REL_ "GenSigTimeoutTime" BU_SG_REL_ IC3 SG_ 2147485026 Trail4Axle3Type_ISig_4 6000;
BA_REL_ "GenSigFirstTimeoutTime" BU_SG_REL_ CIOM SG_ 2147485026 Trail4Axle3Type_ISig_4 24000;
BA_REL_ "GenSigTimeoutTime" BU_SG_REL_ CIOM SG_ 2147485026 Trail4Axle3Type_ISig_4 6000;
BA_REL_ "GenSigFirstTimeoutTime" BU_SG_REL_ CIOM SG_ 2147485026 Trail4Axle2Type_ISig_4 24000;
BA_REL_ "GenSigTimeoutTime" BU_SG_REL_ CIOM SG_ 2147485026 Trail4Axle2Type_ISig_4 6000;
BA_REL_ "GenSigFirstTimeoutTime" BU_SG_REL_ IC3 SG_ 2147485026 Trail4Axle2Type_ISig_4 24000;
BA_REL_ "GenSigTimeoutTime" BU_SG_REL_ IC3 SG_ 2147485026 Trail4Axle2Type_ISig_4 6000;
BA_REL_ "GenSigFirstTimeoutTime" BU_SG_REL_ CIOM SG_ 2147485026 Trail1Axle4Type_ISig_4 24000;
BA_REL_ "GenSigTimeoutTime" BU_SG_REL_ CIOM SG_ 2147485026 Trail1Axle4Type_ISig_4 6000;
BA_REL_ "GenSigFirstTimeoutTime" BU_SG_REL_ IC3 SG_ 2147485026 Trail1Axle4Type_ISig_4 24000;
BA_REL_ "GenSigTimeoutTime" BU_SG_REL_ IC3 SG_ 2147485026 Trail1Axle4Type_ISig_4 6000;
BA_REL_ "GenSigFirstTimeoutTime" BU_SG_REL_ IC3 SG_ 2147485026 Trail1Axle1Type_ISig_4 24000;
BA_REL_ "GenSigTimeoutTime" BU_SG_REL_ IC3 SG_ 2147485026 Trail1Axle1Type_ISig_4 6000;
BA_REL_ "GenSigFirstTimeoutTime" BU_SG_REL_ CIOM SG_ 2147485026 Trail1Axle1Type_ISig_4 24000;
BA_REL_ "GenSigTimeoutTime" BU_SG_REL_ CIOM SG_ 2147485026 Trail1Axle1Type_ISig_4 6000;
BA_REL_ "GenSigFirstTimeoutTime" BU_SG_REL_ CIOM SG_ 2147485026 Trail1Type_TrailType_ISig_4 24000;
BA_REL_ "GenSigTimeoutTime" BU_SG_REL_ CIOM SG_ 2147485026 Trail1Type_TrailType_ISig_4 6000;
BA_REL_ "GenSigFirstTimeoutTime" BU_SG_REL_ IC3 SG_ 2147485026 Trail1Type_TrailType_ISig_4 24000;
BA_REL_ "GenSigTimeoutTime" BU_SG_REL_ IC3 SG_ 2147485026 Trail1Type_TrailType_ISig_4 6000;
BA_REL_ "GenSigFirstTimeoutTime" BU_SG_REL_ CIOM SG_ 2147485026 Trail2Type_Towing_ISig_4 24000;
BA_REL_ "GenSigTimeoutTime" BU_SG_REL_ CIOM SG_ 2147485026 Trail2Type_Towing_ISig_4 6000;
BA_REL_ "GenSigFirstTimeoutTime" BU_SG_REL_ IC3 SG_ 2147485026 Trail2Type_Towing_ISig_4 24000;
BA_REL_ "GenSigTimeoutTime" BU_SG_REL_ IC3 SG_ 2147485026 Trail2Type_Towing_ISig_4 6000;
BA_REL_ "GenSigFirstTimeoutTime" BU_SG_REL_ CIOM SG_ 2147485026 Trail2Axle1Type_ISig_4 24000;
BA_REL_ "GenSigTimeoutTime" BU_SG_REL_ CIOM SG_ 2147485026 Trail2Axle1Type_ISig_4 6000;
BA_REL_ "GenSigFirstTimeoutTime" BU_SG_REL_ IC3 SG_ 2147485026 Trail2Axle1Type_ISig_4 24000;
BA_REL_ "GenSigTimeoutTime" BU_SG_REL_ IC3 SG_ 2147485026 Trail2Axle1Type_ISig_4 6000;
BA_REL_ "GenSigFirstTimeoutTime" BU_SG_REL_ CIOM SG_ 2147485026 Trail3Axle3Type_ISig_4 24000;
BA_REL_ "GenSigTimeoutTime" BU_SG_REL_ CIOM SG_ 2147485026 Trail3Axle3Type_ISig_4 6000;
BA_REL_ "GenSigFirstTimeoutTime" BU_SG_REL_ IC3 SG_ 2147485026 Trail3Axle3Type_ISig_4 24000;
BA_REL_ "GenSigTimeoutTime" BU_SG_REL_ IC3 SG_ 2147485026 Trail3Axle3Type_ISig_4 6000;
BA_REL_ "GenSigFirstTimeoutTime" BU_SG_REL_ IC3 SG_ 2147485026 Trail3Axle1Type_ISig_4 24000;
BA_REL_ "GenSigTimeoutTime" BU_SG_REL_ IC3 SG_ 2147485026 Trail3Axle1Type_ISig_4 6000;
BA_REL_ "GenSigFirstTimeoutTime" BU_SG_REL_ CIOM SG_ 2147485026 Trail3Axle1Type_ISig_4 24000;
BA_REL_ "GenSigTimeoutTime" BU_SG_REL_ CIOM SG_ 2147485026 Trail3Axle1Type_ISig_4 6000;
BA_REL_ "GenSigFirstTimeoutTime" BU_SG_REL_ CIOM SG_ 2147485026 Trail4Axle5Type_ISig_4 24000;
BA_REL_ "GenSigTimeoutTime" BU_SG_REL_ CIOM SG_ 2147485026 Trail4Axle5Type_ISig_4 6000;
BA_REL_ "GenSigFirstTimeoutTime" BU_SG_REL_ IC3 SG_ 2147485026 Trail4Axle5Type_ISig_4 24000;
BA_REL_ "GenSigTimeoutTime" BU_SG_REL_ IC3 SG_ 2147485026 Trail4Axle5Type_ISig_4 6000;
BA_REL_ "GenSigFirstTimeoutTime" BU_SG_REL_ IC3 SG_ 2147485026 Trail1Axle3Type_ISig_4 24000;
BA_REL_ "GenSigTimeoutTime" BU_SG_REL_ IC3 SG_ 2147485026 Trail1Axle3Type_ISig_4 6000;
BA_REL_ "GenSigFirstTimeoutTime" BU_SG_REL_ CIOM SG_ 2147485026 Trail1Axle3Type_ISig_4 24000;
BA_REL_ "GenSigTimeoutTime" BU_SG_REL_ CIOM SG_ 2147485026 Trail1Axle3Type_ISig_4 6000;
BA_REL_ "GenSigFirstTimeoutTime" BU_SG_REL_ CIOM SG_ 2147485026 Trail2Type_TrailType_ISig_4 24000;
BA_REL_ "GenSigTimeoutTime" BU_SG_REL_ CIOM SG_ 2147485026 Trail2Type_TrailType_ISig_4 6000;
BA_REL_ "GenSigFirstTimeoutTime" BU_SG_REL_ IC3 SG_ 2147485026 Trail2Type_TrailType_ISig_4 24000;
BA_REL_ "GenSigTimeoutTime" BU_SG_REL_ IC3 SG_ 2147485026 Trail2Type_TrailType_ISig_4 6000;
BA_REL_ "GenSigFirstTimeoutTime" BU_SG_REL_ IC3 SG_ 2147485026 Trail3Axle2Type_ISig_4 24000;
BA_REL_ "GenSigTimeoutTime" BU_SG_REL_ IC3 SG_ 2147485026 Trail3Axle2Type_ISig_4 6000;
BA_REL_ "GenSigFirstTimeoutTime" BU_SG_REL_ CIOM SG_ 2147485026 Trail3Axle2Type_ISig_4 24000;
BA_REL_ "GenSigTimeoutTime" BU_SG_REL_ CIOM SG_ 2147485026 Trail3Axle2Type_ISig_4 6000;
BA_REL_ "GenSigFirstTimeoutTime" BU_SG_REL_ IC3 SG_ 2147485026 Trail4Axle6Type_ISig_4 24000;
BA_REL_ "GenSigTimeoutTime" BU_SG_REL_ IC3 SG_ 2147485026 Trail4Axle6Type_ISig_4 6000;
BA_REL_ "GenSigFirstTimeoutTime" BU_SG_REL_ CIOM SG_ 2147485026 Trail4Axle6Type_ISig_4 24000;
BA_REL_ "GenSigTimeoutTime" BU_SG_REL_ CIOM SG_ 2147485026 Trail4Axle6Type_ISig_4 6000;
BA_REL_ "GenSigFirstTimeoutTime" BU_SG_REL_ IC3 SG_ 2147485026 Trail2Axle5Type_ISig_4 24000;
BA_REL_ "GenSigTimeoutTime" BU_SG_REL_ IC3 SG_ 2147485026 Trail2Axle5Type_ISig_4 6000;
BA_REL_ "GenSigFirstTimeoutTime" BU_SG_REL_ CIOM SG_ 2147485026 Trail2Axle5Type_ISig_4 24000;
BA_REL_ "GenSigTimeoutTime" BU_SG_REL_ CIOM SG_ 2147485026 Trail2Axle5Type_ISig_4 6000;
BA_REL_ "GenSigFirstTimeoutTime" BU_SG_REL_ CIOM SG_ 2147485026 Trail2Axle6Type_ISig_4 24000;
BA_REL_ "GenSigTimeoutTime" BU_SG_REL_ CIOM SG_ 2147485026 Trail2Axle6Type_ISig_4 6000;
BA_REL_ "GenSigFirstTimeoutTime" BU_SG_REL_ IC3 SG_ 2147485026 Trail2Axle6Type_ISig_4 24000;
BA_REL_ "GenSigTimeoutTime" BU_SG_REL_ IC3 SG_ 2147485026 Trail2Axle6Type_ISig_4 6000;
BA_REL_ "GenSigFirstTimeoutTime" BU_SG_REL_ IC3 SG_ 2147485026 Trail3Axle6Type_ISig_4 24000;
BA_REL_ "GenSigTimeoutTime" BU_SG_REL_ IC3 SG_ 2147485026 Trail3Axle6Type_ISig_4 6000;
BA_REL_ "GenSigFirstTimeoutTime" BU_SG_REL_ CIOM SG_ 2147485026 Trail3Axle6Type_ISig_4 24000;
BA_REL_ "GenSigTimeoutTime" BU_SG_REL_ CIOM SG_ 2147485026 Trail3Axle6Type_ISig_4 6000;
BA_REL_ "GenSigFirstTimeoutTime" BU_SG_REL_ IC3 SG_ 2147485026 Trail1Axle2Type_ISig_4 24000;
BA_REL_ "GenSigTimeoutTime" BU_SG_REL_ IC3 SG_ 2147485026 Trail1Axle2Type_ISig_4 6000;
BA_REL_ "GenSigFirstTimeoutTime" BU_SG_REL_ CIOM SG_ 2147485026 Trail1Axle2Type_ISig_4 24000;
BA_REL_ "GenSigTimeoutTime" BU_SG_REL_ CIOM SG_ 2147485026 Trail1Axle2Type_ISig_4 6000;
BA_REL_ "GenSigFirstTimeoutTime" BU_SG_REL_ CIOM SG_ 2147485026 Trail2Axle2Type_ISig_4 24000;
BA_REL_ "GenSigTimeoutTime" BU_SG_REL_ CIOM SG_ 2147485026 Trail2Axle2Type_ISig_4 6000;
BA_REL_ "GenSigFirstTimeoutTime" BU_SG_REL_ IC3 SG_ 2147485026 Trail2Axle2Type_ISig_4 24000;
BA_REL_ "GenSigTimeoutTime" BU_SG_REL_ IC3 SG_ 2147485026 Trail2Axle2Type_ISig_4 6000;
BA_REL_ "GenSigFirstTimeoutTime" BU_SG_REL_ IC3 SG_ 2147484291 RelCargoLoadTrailer1_ISig_4 12000;
BA_REL_ "GenSigTimeoutTime" BU_SG_REL_ IC3 SG_ 2147484291 RelCargoLoadTrailer1_ISig_4 3000;
BA_REL_ "GenSigFirstTimeoutTime" BU_SG_REL_ CIOM SG_ 2147484291 RelCargoLoadTrailer1_ISig_4 24000;
BA_REL_ "GenSigTimeoutTime" BU_SG_REL_ CIOM SG_ 2147484291 RelCargoLoadTrailer1_ISig_4 6000;
BA_REL_ "GenSigFirstTimeoutTime" BU_SG_REL_ IC3 SG_ 2147484291 RelCargoLoadTrailer5_ISig_4 12000;
BA_REL_ "GenSigTimeoutTime" BU_SG_REL_ IC3 SG_ 2147484291 RelCargoLoadTrailer5_ISig_4 3000;
BA_REL_ "GenSigFirstTimeoutTime" BU_SG_REL_ CIOM SG_ 2147484291 RelCargoLoadTrailer5_ISig_4 24000;
BA_REL_ "GenSigTimeoutTime" BU_SG_REL_ CIOM SG_ 2147484291 RelCargoLoadTrailer5_ISig_4 6000;
BA_REL_ "GenSigFirstTimeoutTime" BU_SG_REL_ BBM SG_ 2147484181 TotalCargoLoadTrailer4 12000;
BA_REL_ "GenSigTimeoutTime" BU_SG_REL_ BBM SG_ 2147484181 TotalCargoLoadTrailer4 3000;
BA_REL_ "GenSigFirstTimeoutTime" BU_SG_REL_ BBM SG_ 2147484181 TotalCargoLoadTruck 12000;
BA_REL_ "GenSigTimeoutTime" BU_SG_REL_ BBM SG_ 2147484181 TotalCargoLoadTruck 3000;
BA_REL_ "GenSigFirstTimeoutTime" BU_SG_REL_ BBM SG_ 2147484181 TotalCargoLoadTrailer3 12000;
BA_REL_ "GenSigTimeoutTime" BU_SG_REL_ BBM SG_ 2147484181 TotalCargoLoadTrailer3 3000;
BA_REL_ "GenSigFirstTimeoutTime" BU_SG_REL_ IC3 SG_ 2147484181 RelCargoLoadTrailer4_ISig_4 12000;
BA_REL_ "GenSigTimeoutTime" BU_SG_REL_ IC3 SG_ 2147484181 RelCargoLoadTrailer4_ISig_4 3000;
BA_REL_ "GenSigFirstTimeoutTime" BU_SG_REL_ CIOM SG_ 2147484181 RelCargoLoadTrailer4_ISig_4 12000;
BA_REL_ "GenSigTimeoutTime" BU_SG_REL_ CIOM SG_ 2147484181 RelCargoLoadTrailer4_ISig_4 3000;
BA_REL_ "GenSigFirstTimeoutTime" BU_SG_REL_ BBM SG_ 2147484069 TotalCargoLoadTrailer2 12000;
BA_REL_ "GenSigTimeoutTime" BU_SG_REL_ BBM SG_ 2147484069 TotalCargoLoadTrailer2 3000;
BA_REL_ "GenSigFirstTimeoutTime" BU_SG_REL_ BBM SG_ 2147484069 TotalCargoLoadTrailer5 12000;
BA_REL_ "GenSigTimeoutTime" BU_SG_REL_ BBM SG_ 2147484069 TotalCargoLoadTrailer5 3000;
BA_REL_ "GenSigFirstTimeoutTime" BU_SG_REL_ BBM SG_ 2147484069 TotalCargoLoadTrailer1 12000;
BA_REL_ "GenSigTimeoutTime" BU_SG_REL_ BBM SG_ 2147484069 TotalCargoLoadTrailer1 3000;
BA_REL_ "GenSigFirstTimeoutTime" BU_SG_REL_ CIOM SG_ 2147484069 RelCargoLoadTruck_ISig_4 12000;
BA_REL_ "GenSigTimeoutTime" BU_SG_REL_ CIOM SG_ 2147484069 RelCargoLoadTruck_ISig_4 3000;
BA_REL_ "GenSigFirstTimeoutTime" BU_SG_REL_ IC3 SG_ 2147484069 RelCargoLoadTruck_ISig_4 12000;
BA_REL_ "GenSigTimeoutTime" BU_SG_REL_ IC3 SG_ 2147484069 RelCargoLoadTruck_ISig_4 3000;
BA_REL_ "GenSigFirstTimeoutTime" BU_SG_REL_ IC3 SG_ 2147483971 LoadTrailer5_ISig_4 12000;
BA_REL_ "GenSigTimeoutTime" BU_SG_REL_ IC3 SG_ 2147483971 LoadTrailer5_ISig_4 3000;
BA_REL_ "GenSigFirstTimeoutTime" BU_SG_REL_ CIOM SG_ 2147483971 LoadTrailer5_ISig_4 12000;
BA_REL_ "GenSigTimeoutTime" BU_SG_REL_ CIOM SG_ 2147483971 LoadTrailer5_ISig_4 3000;
BA_REL_ "GenSigFirstTimeoutTime" BU_SG_REL_ BBM SG_ 2147483971 LoadTrailer5_ISig_4 12000;
BA_REL_ "GenSigTimeoutTime" BU_SG_REL_ BBM SG_ 2147483971 LoadTrailer5_ISig_4 3000;
BA_REL_ "GenSigFirstTimeoutTime" BU_SG_REL_ IC3 SG_ 2147483971 LoadTrailer4Back 12000;
BA_REL_ "GenSigTimeoutTime" BU_SG_REL_ IC3 SG_ 2147483971 LoadTrailer4Back 3000;
BA_REL_ "GenSigFirstTimeoutTime" BU_SG_REL_ IC3 SG_ 2147483971 LoadTrailer2Front 12000;
BA_REL_ "GenSigTimeoutTime" BU_SG_REL_ IC3 SG_ 2147483971 LoadTrailer2Front 3000;
BA_REL_ "GenSigFirstTimeoutTime" BU_SG_REL_ IC3 SG_ 2147483958 TruckType 12000;
BA_REL_ "GenSigTimeoutTime" BU_SG_REL_ IC3 SG_ 2147483958 TruckType 3000;
BA_REL_ "GenSigFirstTimeoutTime" BU_SG_REL_ IC3 SG_ 2147483958 RelCargoLoadTrailer2_ISig_4 12000;
BA_REL_ "GenSigTimeoutTime" BU_SG_REL_ IC3 SG_ 2147483958 RelCargoLoadTrailer2_ISig_4 3000;
BA_REL_ "GenSigFirstTimeoutTime" BU_SG_REL_ CIOM SG_ 2147483958 RelCargoLoadTrailer2_ISig_4 12000;
BA_REL_ "GenSigTimeoutTime" BU_SG_REL_ CIOM SG_ 2147483958 RelCargoLoadTrailer2_ISig_4 3000;
BA_REL_ "GenSigFirstTimeoutTime" BU_SG_REL_ IC3 SG_ 2147483958 RelCargoLoadTrailer3_ISig_4 12000;
BA_REL_ "GenSigTimeoutTime" BU_SG_REL_ IC3 SG_ 2147483958 RelCargoLoadTrailer3_ISig_4 3000;
BA_REL_ "GenSigFirstTimeoutTime" BU_SG_REL_ CIOM SG_ 2147483958 RelCargoLoadTrailer3_ISig_4 12000;
BA_REL_ "GenSigTimeoutTime" BU_SG_REL_ CIOM SG_ 2147483958 RelCargoLoadTrailer3_ISig_4 3000;
BA_REL_ "GenSigFirstTimeoutTime" BU_SG_REL_ IC3 SG_ 2147483958 TruckNoOfFrontAxles 12000;
BA_REL_ "GenSigTimeoutTime" BU_SG_REL_ IC3 SG_ 2147483958 TruckNoOfFrontAxles 3000;
BA_REL_ "GenSigFirstTimeoutTime" BU_SG_REL_ IC3 SG_ 2147483958 MainBeamLEDStatusLeft_ISig_4 12000;
BA_REL_ "GenSigTimeoutTime" BU_SG_REL_ IC3 SG_ 2147483958 MainBeamLEDStatusLeft_ISig_4 3000;
BA_REL_ "GenSigFirstTimeoutTime" BU_SG_REL_ IC3 SG_ 2147483958 MainBeamLEDStatusRight_ISig_4 12000;
BA_REL_ "GenSigTimeoutTime" BU_SG_REL_ IC3 SG_ 2147483958 MainBeamLEDStatusRight_ISig_4 3000;
BA_REL_ "GenSigFirstTimeoutTime" BU_SG_REL_ IC3 SG_ 2147483958 TruckNoOfAxles 12000;
BA_REL_ "GenSigTimeoutTime" BU_SG_REL_ IC3 SG_ 2147483958 TruckNoOfAxles 3000;
BA_REL_ "GenSigFirstTimeoutTime" BU_SG_REL_ IC3 SG_ 2147485015 DistanceToEmptyLNG_ISig_4 24000;
BA_REL_ "GenSigTimeoutTime" BU_SG_REL_ IC3 SG_ 2147485015 DistanceToEmptyLNG_ISig_4 6000;
BA_REL_ "GenSigFirstTimeoutTime" BU_SG_REL_ IC3 SG_ 2147485015 DistanceToEmpty_Diesel_ISig_4 24000;
BA_REL_ "GenSigTimeoutTime" BU_SG_REL_ IC3 SG_ 2147485015 DistanceToEmpty_Diesel_ISig_4 6000;
BA_REL_ "GenSigFirstTimeoutTime" BU_SG_REL_ IC3 SG_ 2147485015 FuelLostInIdle 24000;
BA_REL_ "GenSigTimeoutTime" BU_SG_REL_ IC3 SG_ 2147485015 FuelLostInIdle 6000;
BA_REL_ "GenSigFirstTimeoutTime" BU_SG_REL_ IC3 SG_ 2147485016 FuelLostInOverAccel 24000;
BA_REL_ "GenSigTimeoutTime" BU_SG_REL_ IC3 SG_ 2147485016 FuelLostInOverAccel 6000;
BA_REL_ "GenSigFirstTimeoutTime" BU_SG_REL_ IC3 SG_ 2147485016 FuelLostInOverSpd 24000;
BA_REL_ "GenSigTimeoutTime" BU_SG_REL_ IC3 SG_ 2147485016 FuelLostInOverSpd 6000;
BA_REL_ "GenSigFirstTimeoutTime" BU_SG_REL_ IC3 SG_ 2147485018 FrontConspicLamp_stat_HiLeft_ISi 6000;
BA_REL_ "GenSigTimeoutTime" BU_SG_REL_ IC3 SG_ 2147485018 FrontConspicLamp_stat_HiLeft_ISi 1500;
BA_REL_ "GenSigFirstTimeoutTime" BU_SG_REL_ IC3 SG_ 2147485018 TrailerDirIndLeftOutputStat_ISig 6000;
BA_REL_ "GenSigTimeoutTime" BU_SG_REL_ IC3 SG_ 2147485018 TrailerDirIndLeftOutputStat_ISig 1500;
BA_REL_ "GenSigFirstTimeoutTime" BU_SG_REL_ IC3 SG_ 2147485018 TrailerPosLightLeftOutputStat_IS 6000;
BA_REL_ "GenSigTimeoutTime" BU_SG_REL_ IC3 SG_ 2147485018 TrailerPosLightLeftOutputStat_IS 1500;
BA_REL_ "GenSigFirstTimeoutTime" BU_SG_REL_ IC3 SG_ 2147485018 TrailerBrakeLightOutputStat_ISig 6000;
BA_REL_ "GenSigTimeoutTime" BU_SG_REL_ IC3 SG_ 2147485018 TrailerBrakeLightOutputStat_ISig 1500;
BA_REL_ "GenSigFirstTimeoutTime" BU_SG_REL_ IC3 SG_ 2147485018 FrontConspicLamp_stat_LoRight_IS 6000;
BA_REL_ "GenSigTimeoutTime" BU_SG_REL_ IC3 SG_ 2147485018 FrontConspicLamp_stat_LoRight_IS 1500;
BA_REL_ "GenSigFirstTimeoutTime" BU_SG_REL_ IC3 SG_ 2147485018 FrontConspicLamp_stat_LoLeft_ISi 6000;
BA_REL_ "GenSigTimeoutTime" BU_SG_REL_ IC3 SG_ 2147485018 FrontConspicLamp_stat_LoLeft_ISi 1500;
BA_REL_ "GenSigFirstTimeoutTime" BU_SG_REL_ IC3 SG_ 2147485018 TrailerDirIndRightOutputStat_ISi 6000;
BA_REL_ "GenSigTimeoutTime" BU_SG_REL_ IC3 SG_ 2147485018 TrailerDirIndRightOutputStat_ISi 1500;
BA_REL_ "GenSigFirstTimeoutTime" BU_SG_REL_ IC3 SG_ 2147485018 TrailerPosLightRightOutputStat_I 6000;
BA_REL_ "GenSigTimeoutTime" BU_SG_REL_ IC3 SG_ 2147485018 TrailerPosLightRightOutputStat_I 1500;
BA_REL_ "GenSigFirstTimeoutTime" BU_SG_REL_ IC3 SG_ 2147485018 FrontConspicLamp_stat_HiRight_IS 6000;
BA_REL_ "GenSigTimeoutTime" BU_SG_REL_ IC3 SG_ 2147485018 FrontConspicLamp_stat_HiRight_IS 1500;
BA_REL_ "GenSigFirstTimeoutTime" BU_SG_REL_ DACU SG_ 2147484194 FASSaturated_ISig_4 3000;
BA_REL_ "GenSigTimeoutTime" BU_SG_REL_ DACU SG_ 2147484194 FASSaturated_ISig_4 120;
BA_REL_ "GenSigFirstTimeoutTime" BU_SG_REL_ IC3 SG_ 2147484194 OverSteerGuidanceStatus_ISig_4 3000;
BA_REL_ "GenSigTimeoutTime" BU_SG_REL_ IC3 SG_ 2147484194 OverSteerGuidanceStatus_ISig_4 120;
BA_REL_ "GenSigFirstTimeoutTime" BU_SG_REL_ DACU SG_ 2147484194 FASFullyOperational_ISig_4 3000;
BA_REL_ "GenSigTimeoutTime" BU_SG_REL_ DACU SG_ 2147484194 FASFullyOperational_ISig_4 120;
BA_REL_ "GenSigFirstTimeoutTime" BU_SG_REL_ BBM SG_ 2147484194 FASFullyOperational_ISig_4 3000;
BA_REL_ "GenSigTimeoutTime" BU_SG_REL_ BBM SG_ 2147484194 FASFullyOperational_ISig_4 120;
BA_REL_ "GenSigFirstTimeoutTime" BU_SG_REL_ DACU SG_ 2147484194 FASFunctionInControl_ISig_4 3000;
BA_REL_ "GenSigTimeoutTime" BU_SG_REL_ DACU SG_ 2147484194 FASFunctionInControl_ISig_4 120;
BA_REL_ "GenSigFirstTimeoutTime" BU_SG_REL_ DACU SG_ 2147484194 FrontRoadWheelAngleEstimate_ISig 3000;
BA_REL_ "GenSigTimeoutTime" BU_SG_REL_ DACU SG_ 2147484194 FrontRoadWheelAngleEstimate_ISig 120;
BA_REL_ "GenSigFirstTimeoutTime" BU_SG_REL_ BBM SG_ 2147484194 FrontRoadWheelAngleEstimate_ISig 3600;
BA_REL_ "GenSigTimeoutTime" BU_SG_REL_ BBM SG_ 2147484194 FrontRoadWheelAngleEstimate_ISig 120;
BA_REL_ "GenSigFirstTimeoutTime" BU_SG_REL_ DACU SG_ 2147484194 DriverSteeringTorqueEstimate_ISi 3000;
BA_REL_ "GenSigTimeoutTime" BU_SG_REL_ DACU SG_ 2147484194 DriverSteeringTorqueEstimate_ISi 120;
BA_REL_ "GenSigFirstTimeoutTime" BU_SG_REL_ DACU SG_ 2147484194 DriverSteeringTqEstimateConf_ISi 3000;
BA_REL_ "GenSigTimeoutTime" BU_SG_REL_ DACU SG_ 2147484194 DriverSteeringTqEstimateConf_ISi 120;
BA_REL_ "GenSigFirstTimeoutTime" BU_SG_REL_ IC3 SG_ 2147485053 ActualFasPersSettingsButton_ISig 24000;
BA_REL_ "GenSigTimeoutTime" BU_SG_REL_ IC3 SG_ 2147485053 ActualFasPersSettingsButton_ISig 6000;
BA_REL_ "GenSigFirstTimeoutTime" BU_SG_REL_ IC3 SG_ 2147485053 FasUsrDefStiffStraightSetting_IS 24000;
BA_REL_ "GenSigTimeoutTime" BU_SG_REL_ IC3 SG_ 2147485053 FasUsrDefStiffStraightSetting_IS 6000;
BA_REL_ "GenSigFirstTimeoutTime" BU_SG_REL_ IC3 SG_ 2147485053 FuelLostByBraking_ISig_4 24000;
BA_REL_ "GenSigTimeoutTime" BU_SG_REL_ IC3 SG_ 2147485053 FuelLostByBraking_ISig_4 6000;
BA_REL_ "GenSigFirstTimeoutTime" BU_SG_REL_ IC3 SG_ 2147485053 ActualFasManualOffsetSetting_ISi 24000;
BA_REL_ "GenSigTimeoutTime" BU_SG_REL_ IC3 SG_ 2147485053 ActualFasManualOffsetSetting_ISi 6000;
BA_REL_ "GenSigFirstTimeoutTime" BU_SG_REL_ IC3 SG_ 2147485053 FasUsrDefinedDampingSetting_ISig 24000;
BA_REL_ "GenSigTimeoutTime" BU_SG_REL_ IC3 SG_ 2147485053 FasUsrDefinedDampingSetting_ISig 6000;
BA_REL_ "GenSigFirstTimeoutTime" BU_SG_REL_ IC3 SG_ 2147485053 FasDriver_ISig_4 24000;
BA_REL_ "GenSigTimeoutTime" BU_SG_REL_ IC3 SG_ 2147485053 FasDriver_ISig_4 6000;
BA_REL_ "GenSigFirstTimeoutTime" BU_SG_REL_ IC3 SG_ 2147485053 FasUsrDefLowSpeedReturnSetting_I 24000;
BA_REL_ "GenSigTimeoutTime" BU_SG_REL_ IC3 SG_ 2147485053 FasUsrDefLowSpeedReturnSetting_I 6000;
BA_REL_ "GenSigFirstTimeoutTime" BU_SG_REL_ IC3 SG_ 2147485053 FasUsrDefStiffnessCurveSetting_I 24000;
BA_REL_ "GenSigTimeoutTime" BU_SG_REL_ IC3 SG_ 2147485053 FasUsrDefStiffnessCurveSetting_I 6000;
BA_REL_ "GenSigFirstTimeoutTime" BU_SG_REL_ IC3 SG_ 2147484478 PS_PosLightDoorOpen 3000;
BA_REL_ "GenSigTimeoutTime" BU_SG_REL_ IC3 SG_ 2147484478 PS_PosLightDoorOpen 600;
BA_REL_ "GenSigFirstTimeoutTime" BU_SG_REL_ IC3 SG_ 2147484478 PS_FogLightRear 3000;
BA_REL_ "GenSigTimeoutTime" BU_SG_REL_ IC3 SG_ 2147484478 PS_FogLightRear 600;
BA_REL_ "GenSigFirstTimeoutTime" BU_SG_REL_ CIOM SG_ 2147484478 TrailerBodyLampDI_stat 6000;
BA_REL_ "GenSigTimeoutTime" BU_SG_REL_ CIOM SG_ 2147484478 TrailerBodyLampDI_stat 6000;
BA_REL_ "GenSigFirstTimeoutTime" BU_SG_REL_ IC3 SG_ 2147484478 ParkedLoadDistribution_ISig_4 3000;
BA_REL_ "GenSigTimeoutTime" BU_SG_REL_ IC3 SG_ 2147484478 ParkedLoadDistribution_ISig_4 600;
BA_REL_ "GenSigFirstTimeoutTime" BU_SG_REL_ IC3 SG_ 2147484478 PV_HeadLightLevel 3000;
BA_REL_ "GenSigTimeoutTime" BU_SG_REL_ IC3 SG_ 2147484478 PV_HeadLightLevel 600;
BA_REL_ "GenSigFirstTimeoutTime" BU_SG_REL_ CIOM SG_ 2147484478 TrailerBodyLampFdbk_stat 6000;
BA_REL_ "GenSigTimeoutTime" BU_SG_REL_ CIOM SG_ 2147484478 TrailerBodyLampFdbk_stat 6000;
BA_REL_ "GenSigFirstTimeoutTime" BU_SG_REL_ IC3 SG_ 2147484478 PS_FogLightFront 3000;
BA_REL_ "GenSigTimeoutTime" BU_SG_REL_ IC3 SG_ 2147484478 PS_FogLightFront 600;
BA_REL_ "GenSigFirstTimeoutTime" BU_SG_REL_ IC3 SG_ 2147484478 Alcolock_PBReleaseInhibit_ind 3000;
BA_REL_ "GenSigTimeoutTime" BU_SG_REL_ IC3 SG_ 2147484478 Alcolock_PBReleaseInhibit_ind 600;
BA_REL_ "GenSigFirstTimeoutTime" BU_SG_REL_ IC3 SG_ 2147484478 DHCNotificationReq 3000;
BA_REL_ "GenSigTimeoutTime" BU_SG_REL_ IC3 SG_ 2147484478 DHCNotificationReq 600;
BA_REL_ "GenSigFirstTimeoutTime" BU_SG_REL_ IC3 SG_ 2147484478 DriverCrank_rqst 3000;
BA_REL_ "GenSigTimeoutTime" BU_SG_REL_ IC3 SG_ 2147484478 DriverCrank_rqst 600;
BA_REL_ "GenSigFirstTimeoutTime" BU_SG_REL_ IC3 SG_ 2147484478 PS_HeadLightAdjustment 3000;
BA_REL_ "GenSigTimeoutTime" BU_SG_REL_ IC3 SG_ 2147484478 PS_HeadLightAdjustment 600;
BA_REL_ "GenSigFirstTimeoutTime" BU_SG_REL_ IC3 SG_ 2147484478 PS_MainBeam 3000;
BA_REL_ "GenSigTimeoutTime" BU_SG_REL_ IC3 SG_ 2147484478 PS_MainBeam 600;
BA_REL_ "GenSigFirstTimeoutTime" BU_SG_REL_ IC3 SG_ 2147484478 InstFuel_ConsumpValue 3000;
BA_REL_ "GenSigTimeoutTime" BU_SG_REL_ IC3 SG_ 2147484478 InstFuel_ConsumpValue 600;
BA_REL_ "GenSigFirstTimeoutTime" BU_SG_REL_ IC3 SG_ 2147484478 InstFuel_VehicleMoving 3000;
BA_REL_ "GenSigTimeoutTime" BU_SG_REL_ IC3 SG_ 2147484478 InstFuel_VehicleMoving 600;
BA_REL_ "GenSigFirstTimeoutTime" BU_SG_REL_ IC3 SG_ 2147484478 PS_AFSAllowedInDriveP 3000;
BA_REL_ "GenSigTimeoutTime" BU_SG_REL_ IC3 SG_ 2147484478 PS_AFSAllowedInDriveP 600;
BA_REL_ "GenSigFirstTimeoutTime" BU_SG_REL_ IC3 SG_ 2147484478 PS_AFS 3000;
BA_REL_ "GenSigTimeoutTime" BU_SG_REL_ IC3 SG_ 2147484478 PS_AFS 600;
BA_REL_ "GenSigFirstTimeoutTime" BU_SG_REL_ CIOM SG_ 2147484478 AC2CoolingFanControl_rqst 6000;
BA_REL_ "GenSigTimeoutTime" BU_SG_REL_ CIOM SG_ 2147484478 AC2CoolingFanControl_rqst 6000;
BA_REL_ "GenSigFirstTimeoutTime" BU_SG_REL_ IC3 SG_ 2147484478 DHCStatus 3000;
BA_REL_ "GenSigTimeoutTime" BU_SG_REL_ IC3 SG_ 2147484478 DHCStatus 600;
BA_REL_ "GenSigFirstTimeoutTime" BU_SG_REL_ IC3 SG_ 2147484478 PS_PositionLight 3000;
BA_REL_ "GenSigTimeoutTime" BU_SG_REL_ IC3 SG_ 2147484478 PS_PositionLight 600;
VAL_ 2044 Debug_PVT_SCIM_RD_DAI1Fault 3 "Input signals invalid" 2 "Open circuit " 1 "Short to GND " 0 "Nomal" ;
VAL_ 2044 Debug_PVT_SCIM_RD_DAI2Fualt 3 "Input signals invalid" 2 "Open circuit " 1 "Short to GND" 0 "Nomal" ;
VAL_ 2044 Debug_PVT_SCIM_RD_ADI16Fault 3 "Input signals invalid" 2 "Open circuit" 1 "Short to GND " 0 "Nomal" ;
VAL_ 2044 Debug_PVT_SCIM_RD_ADI15Fault 3 "Input signals invalid " 2 "Open circuit " 1 "Short to GND" 0 "Nomal" ;
VAL_ 2044 Debug_PVT_SCIM_RD_ADI14Fault 3 "Input signals invalid " 2 "Open circuit " 1 "Short to GND" 0 "Nomal" ;
VAL_ 2044 Debug_PVT_SCIM_RD_ADI13Fault 3 "Input signals invalid " 2 "Open circuit" 1 "Short to GND " 0 "Nomal" ;
VAL_ 2044 Debug_PVT_SCIM_RD_ADI12Fault 3 "Input signals invalid" 2 "Open circuit " 1 "Short to GND" 0 "Nomal" ;
VAL_ 2044 Debug_PVT_SCIM_RD_ADI11Fault 3 "Input signals invalid" 2 "Open circuit " 1 "Short to GND " 0 "Nomal" ;
VAL_ 2044 Debug_PVT_SCIM_RD_ADI10Fault 3 "Input signals invalid" 2 "Open circuit " 1 "Short to GND" 0 "Nomal" ;
VAL_ 2044 Debug_PVT_SCIM_RD_ADI09Fault 3 "Input signals invalid " 2 "Open circuit " 1 "Short to GND" 0 "Nomal" ;
VAL_ 2044 Debug_PVT_SCIM_RD_ADI08Fault 3 "Input signals invalid " 2 "Open circuit" 1 "Short to GND" 0 "Nomal" ;
VAL_ 2044 Debug_PVT_SCIM_RD_ADI07Fault 3 "Input signals invalid " 2 "Open circuit " 1 "Short to GND" 0 "Nomal" ;
VAL_ 2044 Debug_PVT_SCIM_RD_ADI06Fault 3 "Input signals invalid" 2 "Open circuit" 1 "Short to GND" 0 "Nomal" ;
VAL_ 2044 Debug_PVT_SCIM_RD_ADI05Fault 3 "Input signals invalid " 2 "Open circuit " 1 "Short to GND " 0 "Nomal" ;
VAL_ 2044 Debug_PVT_SCIM_RD_ADI04Fault 3 "Input signals invalid " 2 "Open circuit " 1 "Short to GND" 0 "Nomal" ;
VAL_ 2044 Debug_PVT_SCIM_RD_ADI03Fault 3 "Input signals invalid " 2 "Open circuit" 1 "Short to GND" 0 "Nomal" ;
VAL_ 2044 Debug_PVT_SCIM_RD_ADI02Fault 3 "Input signals invalid" 2 "Open circuit" 1 "Short to GND" 0 "Nomal" ;
VAL_ 2044 Debug_PVT_SCIM_RD_ADI01Fault 3 "Input signals invalid " 2 "Open circuit" 1 "Short to GND" 0 "Nomal" ;
VAL_ 2035 Debug_PVT_PEPS_TestPeriod_Ctrl 4 "4s" 3 "3s" 2 "2s" 1 "1s" 0 "None" ;
VAL_ 2035 Debug_PVT_PEPS_Ant_Ctrl 5 "P4 Antenna" 4 "P3 Antenna" 3 "P2 Antenna" 2 "P1 Antenna" 1 "Pi Antenna" 0 "None" ;
VAL_ 2035 Debug_PVT_PEPS_Logic_Ctrl 3 "For PS+PE_Pi+P1+P2+P3" 2 "For PS only_Pi+P1" 1 "For PS only_Pi" 0 "None" ;
VAL_ 2017 Debug_PVT_Fob_Found 3 "Invaild" 2 "Not found" 1 "Found" 0 "None" ;
VAL_ 2017 Debug_PVT_PEPS_Fob_location 5 "Invaild" 4 "Inside" 3 "Front" 2 "Ast" 1 "Drv" 0 "None" ;
VAL_ 2017 Debug_PVT_PEPS_Logic_stat 3 "For PS+PE_Pi+P1+P2+P3" 2 "For PS only_Pi+P1" 1 "For PS only_Pi" 0 "None" ;
VAL_ 2017 Debug_PVT_PEPS_AntCtrl_stat 5 "P4 Antenna" 4 "P3 Antenna" 3 "P2 Antenna" 2 "P1 Antenna" 1 "Pi Antenna" 0 "None" ;
VAL_ 2017 Debug_PVT_PEPS_TestPeriod_stat 4 "4s" 3 "3s" 2 "2s" 1 "1s" 0 "None" ;
VAL_ 2014 Debug_PVT_Fob_Select 8 "Fob8" 7 "Fob7" 6 "Fob6" 5 "Fob5" 4 "Fob4" 3 "Fob3" 2 "Fob2" 1 "Fob1" 0 "Non_Select" ;
VAL_ 2014 Debug_PVT_SCIM_Ctrl_WLS3 1 "Deactivate" 0 "Activate" ;
VAL_ 2014 Debug_PVT_SCIM_Ctrl_WLS2 1 "Deactivate" 0 "Activate" ;
VAL_ 2014 Debug_PVT_SCIM_Ctrl_WLS1 1 "Deactivate" 0 "Activate" ;
VAL_ 2013 Debug_PVT_SCIM_Ctrl_DAIPullUp 1 "Deactivate" 0 "Activate" ;
VAL_ 2013 Debug_PVT_SCIM_Ctrl_WHS2 1 "Deactivate" 0 "Activate" ;
VAL_ 2013 Debug_PVT_SCIM_Ctrl_WHS1 1 "Deactivate" 0 "Activate" ;
VAL_ 2013 Debug_PVT_SCIM_Ctrl_ParkedPullUp 1 "Deactivate" 0 "Activate" ;
VAL_ 2013 Debug_PVT_SCIM_Ctrl_LivingPullUp 1 "Deactivate" 0 "Activate" ;
VAL_ 2013 Debug_PVT_SCIM_Ctrl_BHS4 1 "Deactivate" 0 "Activate" ;
VAL_ 2013 Debug_PVT_SCIM_Ctrl_BHS3 1 "Deactivate" 0 "Activate" ;
VAL_ 2013 Debug_PVT_SCIM_Ctrl_BHS2 1 "Deactivate" 0 "Activate" ;
VAL_ 2013 Debug_PVT_SCIM_Ctrl_BHS1 1 "Deactivate" 0 "Activate" ;
VAL_ 2013 Debug_PVT_SCIM_Ctrl_12VParked 1 "Deactivate" 0 "Activate" ;
VAL_ 2013 Debug_PVT_SCIM_Ctrl_12VLiving 1 "Deactivate" 0 "Activate" ;
VAL_ 2013 Debug_PVT_SCIM_Ctrl_12VDCDC 1 "Deactivate" 0 "Activate" ;
VAL_ 2012 Debug_PVT_Fob_ID 8 "Fob8" 7 "Fob7" 6 "Fob6" 5 "Fob5" 4 "Fob4" 3 "Fob3" 2 "Fob2" 1 "Fob1" 0 "Non_Select" ;
VAL_ 2011 Debug_PVT_SCIM_RD_WLS2_Fault 0 "Nomal" 8 "Invalid[Error Value]" 5 "Reserved" 4 "Reserved" 7 "Voltage Too High" 6 "Voltage Too Low" 3 "Open Circuit" 2 "Short To Battery" 1 "Short To Ground" ;
VAL_ 2011 Debug_PVT_SCIM_RD_WLS1_Fault 0 "Nomal" 8 "Invalid[Error Value]" 5 "Reserved" 4 "Reserved" 7 "Voltage Too High" 6 "Voltage Too Low" 3 "Open Circuit" 2 "Short To Battery" 1 "Short To Ground" ;
VAL_ 2010 Debug_PVT_SCIM_RD_WHS2_Fault 0 "Nomal" 8 "Invalid[Error Value]" 5 "Reserved" 4 "Reserved" 7 "Voltage Too High" 6 "Voltage Too Low" 3 "Open Circuit" 2 "Short To Battery" 1 "Short To Ground" ;
VAL_ 2010 Debug_PVT_SCIM_RD_WHS1_Fault 0 "Nomal" 8 "Invalid[Error Value]" 5 "Reserved" 4 "Reserved" 7 "Voltage Too High" 6 "Voltage Too Low" 3 "Open Circuit" 2 "Short To Battery" 1 "Short To Ground" ;
VAL_ 2009 Debug_PVT_SCIM_RD_WLS3_Fault 0 "Nomal" 8 "Invalid[Error Value]" 5 "Reserved" 4 "Reserved" 7 "Voltage Too High" 6 "Voltage Too Low" 3 "Open Circuit" 2 "Short To Battery" 1 "Short To Ground" ;
VAL_ 2147484946 VehCombHeaviestBoogie_VehicleID 7 "VehicleID_NotAvailable" 6 "VehicleID_Error" 5 "VehicleID_Trailer5" 4 "VehicleID_Trailer4" 3 "VehicleID_Trailer3" 2 "VehicleID_Trailer2" 1 "VehicleID_Trailer1" 0 "VehicleID_Truck" ;
VAL_ 2147484946 VehCombHeaviestBoogie_Position 3 "FrontRear_NotAvailable" 2 "FrontRear_Error" 1 "FrontRear_Rear" 0 "FrontRear_Front" ;
VAL_ 2147484946 VehCombHeaviestAxle_Position 15 "AxlePositionNo_NotAvailable" 14 "AxlePositionNo_Error" 13 "AxlePositionNo_Spare8" 12 "AxlePositionNo_Spare7" 11 "AxlePositionNo_Spare6" 10 "AxlePositionNo_Spare5" 9 "AxlePositionNo_Spare4" 8 "AxlePositionNo_Spare3" 7 "AxlePositionNo_Spare2" 6 "AxlePositionNo_Spare1" 5 "AxlePositionNo_Axle6" 4 "AxlePositionNo_Axle5" 3 "AxlePositionNo_Axle4" 2 "AxlePositionNo_Axle3" 1 "AxlePositionNo_Axle2" 0 "AxlePositionNo_Axle1" ;
VAL_ 2147484946 VehCombHeaviestAxle_VehicleID 7 "VehicleID_NotAvailable" 6 "VehicleID_Error" 5 "VehicleID_Trailer5" 4 "VehicleID_Trailer4" 3 "VehicleID_Trailer3" 2 "VehicleID_Trailer2" 1 "VehicleID_Trailer1" 0 "VehicleID_Truck" ;
VAL_ 2147485038 TruckFrontAxle2_Liftable 1 "Liftable_Liftable" 0 "Liftable_NotLiftable" ;
VAL_ 2147485038 TruckRearAxle3_Liftable 1 "Liftable_Liftable" 0 "Liftable_NotLiftable" ;
VAL_ 2147485038 TruckRearAxle2_Liftable 1 "Liftable_Liftable" 0 "Liftable_NotLiftable" ;
VAL_ 2147485038 TruckRearAxle2_Suspension 3 "Suspension_NotAvailable" 2 "Suspension_Spare" 1 "Suspension_Air" 0 "Suspension_Leaf" ;
VAL_ 2147485038 TruckFrontAxle1_Liftable 1 "Liftable_Liftable" 0 "Liftable_NotLiftable" ;
VAL_ 2147485038 TruckRearAxle1_Driven 1 "Driven_Driven" 0 "Driven_NotDriven" ;
VAL_ 2147485038 TruckFrontAxle2_Driven 1 "Driven_Driven" 0 "Driven_NotDriven" ;
VAL_ 2147485038 TruckRearAxle1_Suspension 3 "Suspension_NotAvailable" 2 "Suspension_Spare" 1 "Suspension_Air" 0 "Suspension_Leaf" ;
VAL_ 2147485038 TruckRearAxle2_Driven 1 "Driven_Driven" 0 "Driven_NotDriven" ;
VAL_ 2147485038 TruckFrontAxle2_Suspension 3 "Suspension_NotAvailable" 2 "Suspension_Spare" 1 "Suspension_Air" 0 "Suspension_Leaf" ;
VAL_ 2147485038 TruckRearAxle1_Liftable 1 "Liftable_Liftable" 0 "Liftable_NotLiftable" ;
VAL_ 2147485038 TruckFrontAxle1_Suspension 3 "Suspension_NotAvailable" 2 "Suspension_Spare" 1 "Suspension_Air" 0 "Suspension_Leaf" ;
VAL_ 2147485038 TruckRearAxle3_Driven 1 "Driven_Driven" 0 "Driven_NotDriven" ;
VAL_ 2147485038 TruckFrontAxle1_Driven 1 "Driven_Driven" 0 "Driven_NotDriven" ;
VAL_ 2147485038 TruckRearAxle3_Suspension 3 "Suspension_NotAvailable" 2 "Suspension_Spare" 1 "Suspension_Air" 0 "Suspension_Leaf" ;
VAL_ 2147485028 Trail3Type_TrailType_ISig_4 7 "TrailerType2_NotAvailable" 6 "TrailerType2_Spare" 5 "TrailerType2_NotConnected" 4 "TrailerType2_LinkTrailer" 3 "TrailerType2_Dolly" 2 "TrailerType2_DrawbarTrailer" 1 "TrailerType2_CentreAxleTrailer" 0 "TrailerType2_SemiTrailer" ;
VAL_ 2147485028 Trail5Axle1Type_ISig_4 3 "TrailerAxleType_NotAvailable" 2 "TrailerAxleType_Error" 1 "TrailerAxleType_Liftable" 0 "TrailerAxleType_NotLiftable" ;
VAL_ 2147485028 Trail3Type_Towing_ISig_4 1 "Towing_TowingPossible" 0 "Towing_NoTowingOrOldTrailer" ;
VAL_ 2147485028 Trail5Axle4Type_ISig_4 3 "TrailerAxleType_NotAvailable" 2 "TrailerAxleType_Error" 1 "TrailerAxleType_Liftable" 0 "TrailerAxleType_NotLiftable" ;
VAL_ 2147485028 Trail5Axle3Type_ISig_4 3 "TrailerAxleType_NotAvailable" 2 "TrailerAxleType_Error" 1 "TrailerAxleType_Liftable" 0 "TrailerAxleType_NotLiftable" ;
VAL_ 2147485028 Trail4Type_Towing_ISig_4 1 "Towing_TowingPossible" 0 "Towing_NoTowingOrOldTrailer" ;
VAL_ 2147485028 Trail4Type_TrailType_ISig_4 7 "TrailerType2_NotAvailable" 6 "TrailerType2_Spare" 5 "TrailerType2_NotConnected" 4 "TrailerType2_LinkTrailer" 3 "TrailerType2_Dolly" 2 "TrailerType2_DrawbarTrailer" 1 "TrailerType2_CentreAxleTrailer" 0 "TrailerType2_SemiTrailer" ;
VAL_ 2147485028 Trail5Axle2Type_ISig_4 3 "TrailerAxleType_NotAvailable" 2 "TrailerAxleType_Error" 1 "TrailerAxleType_Liftable" 0 "TrailerAxleType_NotLiftable" ;
VAL_ 2147485028 Trail5Type_TrailType_ISig_4 7 "TrailerType2_NotAvailable" 6 "TrailerType2_Spare" 5 "TrailerType2_NotConnected" 4 "TrailerType2_LinkTrailer" 3 "TrailerType2_Dolly" 2 "TrailerType2_DrawbarTrailer" 1 "TrailerType2_CentreAxleTrailer" 0 "TrailerType2_SemiTrailer" ;
VAL_ 2147485028 Trail5Axle5Type_ISig_4 3 "TrailerAxleType_NotAvailable" 2 "TrailerAxleType_Error" 1 "TrailerAxleType_Liftable" 0 "TrailerAxleType_NotLiftable" ;
VAL_ 2147485028 Trail5Type_Towing_ISig_4 1 "Towing_TowingPossible" 0 "Towing_NoTowingOrOldTrailer" ;
VAL_ 2147485028 Trail5Axle6Type_ISig_4 3 "TrailerAxleType_NotAvailable" 2 "TrailerAxleType_Error" 1 "TrailerAxleType_Liftable" 0 "TrailerAxleType_NotLiftable" ;
VAL_ 2147485026 Trail2Axle4Type_ISig_4 3 "TrailerAxleType_NotAvailable" 2 "TrailerAxleType_Error" 1 "TrailerAxleType_Liftable" 0 "TrailerAxleType_NotLiftable" ;
VAL_ 2147485026 Trail4Axle1Type_ISig_4 3 "TrailerAxleType_NotAvailable" 2 "TrailerAxleType_Error" 1 "TrailerAxleType_Liftable" 0 "TrailerAxleType_NotLiftable" ;
VAL_ 2147485026 Trail2Axle3Type_ISig_4 3 "TrailerAxleType_NotAvailable" 2 "TrailerAxleType_Error" 1 "TrailerAxleType_Liftable" 0 "TrailerAxleType_NotLiftable" ;
VAL_ 2147485026 Trail1Axle6Type_ISig_4 3 "TrailerAxleType_NotAvailable" 2 "TrailerAxleType_Error" 1 "TrailerAxleType_Liftable" 0 "TrailerAxleType_NotLiftable" ;
VAL_ 2147485026 Trail1Type_Towing_ISig_4 1 "Towing_TowingPossible" 0 "Towing_NoTowingOrOldTrailer" ;
VAL_ 2147485026 Trail3Axle5Type_ISig_4 3 "TrailerAxleType_NotAvailable" 2 "TrailerAxleType_Error" 1 "TrailerAxleType_Liftable" 0 "TrailerAxleType_NotLiftable" ;
VAL_ 2147485026 Trail1Axle5Type_ISig_4 3 "TrailerAxleType_NotAvailable" 2 "TrailerAxleType_Error" 1 "TrailerAxleType_Liftable" 0 "TrailerAxleType_NotLiftable" ;
VAL_ 2147485026 Trail3Axle4Type_ISig_4 3 "TrailerAxleType_NotAvailable" 2 "TrailerAxleType_Error" 1 "TrailerAxleType_Liftable" 0 "TrailerAxleType_NotLiftable" ;
VAL_ 2147485026 Trail4Axle4Type_ISig_4 3 "TrailerAxleType_NotAvailable" 2 "TrailerAxleType_Error" 1 "TrailerAxleType_Liftable" 0 "TrailerAxleType_NotLiftable" ;
VAL_ 2147485026 Trail4Axle3Type_ISig_4 3 "TrailerAxleType_NotAvailable" 2 "TrailerAxleType_Error" 1 "TrailerAxleType_Liftable" 0 "TrailerAxleType_NotLiftable" ;
VAL_ 2147485026 Trail4Axle2Type_ISig_4 3 "TrailerAxleType_NotAvailable" 2 "TrailerAxleType_Error" 1 "TrailerAxleType_Liftable" 0 "TrailerAxleType_NotLiftable" ;
VAL_ 2147485026 Trail1Axle4Type_ISig_4 3 "TrailerAxleType_NotAvailable" 2 "TrailerAxleType_Error" 1 "TrailerAxleType_Liftable" 0 "TrailerAxleType_NotLiftable" ;
VAL_ 2147485026 Trail1Axle1Type_ISig_4 3 "TrailerAxleType_NotAvailable" 2 "TrailerAxleType_Error" 1 "TrailerAxleType_Liftable" 0 "TrailerAxleType_NotLiftable" ;
VAL_ 2147485026 Trail1Type_TrailType_ISig_4 7 "TrailerType2_NotAvailable" 6 "TrailerType2_Spare" 5 "TrailerType2_NotConnected" 4 "TrailerType2_LinkTrailer" 3 "TrailerType2_Dolly" 2 "TrailerType2_DrawbarTrailer" 1 "TrailerType2_CentreAxleTrailer" 0 "TrailerType2_SemiTrailer" ;
VAL_ 2147485026 Trail2Type_Towing_ISig_4 1 "Towing_TowingPossible" 0 "Towing_NoTowingOrOldTrailer" ;
VAL_ 2147485026 Trail2Axle1Type_ISig_4 3 "TrailerAxleType_NotAvailable" 2 "TrailerAxleType_Error" 1 "TrailerAxleType_Liftable" 0 "TrailerAxleType_NotLiftable" ;
VAL_ 2147485026 Trail3Axle3Type_ISig_4 3 "TrailerAxleType_NotAvailable" 2 "TrailerAxleType_Error" 1 "TrailerAxleType_Liftable" 0 "TrailerAxleType_NotLiftable" ;
VAL_ 2147485026 Trail3Axle1Type_ISig_4 3 "TrailerAxleType_NotAvailable" 2 "TrailerAxleType_Error" 1 "TrailerAxleType_Liftable" 0 "TrailerAxleType_NotLiftable" ;
VAL_ 2147485026 Trail4Axle5Type_ISig_4 3 "TrailerAxleType_NotAvailable" 2 "TrailerAxleType_Error" 1 "TrailerAxleType_Liftable" 0 "TrailerAxleType_NotLiftable" ;
VAL_ 2147485026 Trail1Axle3Type_ISig_4 3 "TrailerAxleType_NotAvailable" 2 "TrailerAxleType_Error" 1 "TrailerAxleType_Liftable" 0 "TrailerAxleType_NotLiftable" ;
VAL_ 2147485026 Trail2Type_TrailType_ISig_4 7 "TrailerType2_NotAvailable" 6 "TrailerType2_Spare" 5 "TrailerType2_NotConnected" 4 "TrailerType2_LinkTrailer" 3 "TrailerType2_Dolly" 2 "TrailerType2_DrawbarTrailer" 1 "TrailerType2_CentreAxleTrailer" 0 "TrailerType2_SemiTrailer" ;
VAL_ 2147485026 Trail3Axle2Type_ISig_4 3 "TrailerAxleType_NotAvailable" 2 "TrailerAxleType_Error" 1 "TrailerAxleType_Liftable" 0 "TrailerAxleType_NotLiftable" ;
VAL_ 2147485026 Trail4Axle6Type_ISig_4 3 "TrailerAxleType_NotAvailable" 2 "TrailerAxleType_Error" 1 "TrailerAxleType_Liftable" 0 "TrailerAxleType_NotLiftable" ;
VAL_ 2147485026 Trail2Axle5Type_ISig_4 3 "TrailerAxleType_NotAvailable" 2 "TrailerAxleType_Error" 1 "TrailerAxleType_Liftable" 0 "TrailerAxleType_NotLiftable" ;
VAL_ 2147485026 Trail2Axle6Type_ISig_4 3 "TrailerAxleType_NotAvailable" 2 "TrailerAxleType_Error" 1 "TrailerAxleType_Liftable" 0 "TrailerAxleType_NotLiftable" ;
VAL_ 2147485026 Trail3Axle6Type_ISig_4 3 "TrailerAxleType_NotAvailable" 2 "TrailerAxleType_Error" 1 "TrailerAxleType_Liftable" 0 "TrailerAxleType_NotLiftable" ;
VAL_ 2147485026 Trail1Axle2Type_ISig_4 3 "TrailerAxleType_NotAvailable" 2 "TrailerAxleType_Error" 1 "TrailerAxleType_Liftable" 0 "TrailerAxleType_NotLiftable" ;
VAL_ 2147485026 Trail2Axle2Type_ISig_4 3 "TrailerAxleType_NotAvailable" 2 "TrailerAxleType_Error" 1 "TrailerAxleType_Liftable" 0 "TrailerAxleType_NotLiftable" ;
VAL_ 2147483958 TruckType 3 "TruckType_NotAvailable" 2 "TruckType_Undefined" 1 "TruckType_Tractor" 0 "TruckType_Rigid" ;
VAL_ 2147483958 MainBeamLEDStatusLeft_ISig_4 7 "LampCheck_stat_NotAvailable" 6 "LampCheck_stat_Error" 5 "LampCheck_stat_Spare_02" 4 "LampCheck_stat_Spare_01" 3 "LampCheck_stat_Spare" 2 "LampCheck_stat_TestedLampNOK" 1 "LampCheck_stat_TestedLampOK" 0 "LampCheck_stat_NotTested" ;
VAL_ 2147483958 MainBeamLEDStatusRight_ISig_4 7 "LampCheck_stat_NotAvailable" 6 "LampCheck_stat_Error" 5 "LampCheck_stat_Spare_02" 4 "LampCheck_stat_Spare_01" 3 "LampCheck_stat_Spare" 2 "LampCheck_stat_TestedLampNOK" 1 "LampCheck_stat_TestedLampOK" 0 "LampCheck_stat_NotTested" ;
VAL_ 2147485018 FrontConspicLamp_stat_HiLeft_ISi 7 "LampCheck_stat_NotAvailable" 6 "LampCheck_stat_Error" 5 "LampCheck_stat_Spare_02" 4 "LampCheck_stat_Spare_01" 3 "LampCheck_stat_Spare" 2 "LampCheck_stat_TestedLampNOK" 1 "LampCheck_stat_TestedLampOK" 0 "LampCheck_stat_NotTested" ;
VAL_ 2147485018 TrailerDirIndLeftOutputStat_ISig 7 "TrailerLightOutputStat_NotAvailable" 6 "TrailerLightOutputStat_Error" 5 "TrailerLightOutputStat_OutputActiveStatusUncertain" 4 "TrailerLightOutputStat_OutputActiveLightDetectedOnActivation" 3 "TrailerLightOutputStat_OutputActiveLightDetected" 2 "TrailerLightOutputStat_OutputActiveNoLightDetected" 1 "TrailerLightOutputStat_OutputActiveDetectionOngoing" 0 "TrailerLightOutputStat_OutputInactive" ;
VAL_ 2147485018 TrailerPosLightLeftOutputStat_IS 7 "TrailerLightOutputStat_NotAvailable" 6 "TrailerLightOutputStat_Error" 5 "TrailerLightOutputStat_OutputActiveStatusUncertain" 4 "TrailerLightOutputStat_OutputActiveLightDetectedOnActivation" 3 "TrailerLightOutputStat_OutputActiveLightDetected" 2 "TrailerLightOutputStat_OutputActiveNoLightDetected" 1 "TrailerLightOutputStat_OutputActiveDetectionOngoing" 0 "TrailerLightOutputStat_OutputInactive" ;
VAL_ 2147485018 TrailerBrakeLightOutputStat_ISig 7 "TrailerLightOutputStat_NotAvailable" 6 "TrailerLightOutputStat_Error" 5 "TrailerLightOutputStat_OutputActiveStatusUncertain" 4 "TrailerLightOutputStat_OutputActiveLightDetectedOnActivation" 3 "TrailerLightOutputStat_OutputActiveLightDetected" 2 "TrailerLightOutputStat_OutputActiveNoLightDetected" 1 "TrailerLightOutputStat_OutputActiveDetectionOngoing" 0 "TrailerLightOutputStat_OutputInactive" ;
VAL_ 2147485018 FrontConspicLamp_stat_LoRight_IS 7 "LampCheck_stat_NotAvailable" 6 "LampCheck_stat_Error" 5 "LampCheck_stat_Spare_02" 4 "LampCheck_stat_Spare_01" 3 "LampCheck_stat_Spare" 2 "LampCheck_stat_TestedLampNOK" 1 "LampCheck_stat_TestedLampOK" 0 "LampCheck_stat_NotTested" ;
VAL_ 2147485018 FrontConspicLamp_stat_LoLeft_ISi 7 "LampCheck_stat_NotAvailable" 6 "LampCheck_stat_Error" 5 "LampCheck_stat_Spare_02" 4 "LampCheck_stat_Spare_01" 3 "LampCheck_stat_Spare" 2 "LampCheck_stat_TestedLampNOK" 1 "LampCheck_stat_TestedLampOK" 0 "LampCheck_stat_NotTested" ;
VAL_ 2147485018 TrailerDirIndRightOutputStat_ISi 7 "TrailerLightOutputStat_NotAvailable" 6 "TrailerLightOutputStat_Error" 5 "TrailerLightOutputStat_OutputActiveStatusUncertain" 4 "TrailerLightOutputStat_OutputActiveLightDetectedOnActivation" 3 "TrailerLightOutputStat_OutputActiveLightDetected" 2 "TrailerLightOutputStat_OutputActiveNoLightDetected" 1 "TrailerLightOutputStat_OutputActiveDetectionOngoing" 0 "TrailerLightOutputStat_OutputInactive" ;
VAL_ 2147485018 TrailerPosLightRightOutputStat_I 7 "TrailerLightOutputStat_NotAvailable" 6 "TrailerLightOutputStat_Error" 5 "TrailerLightOutputStat_OutputActiveStatusUncertain" 4 "TrailerLightOutputStat_OutputActiveLightDetectedOnActivation" 3 "TrailerLightOutputStat_OutputActiveLightDetected" 2 "TrailerLightOutputStat_OutputActiveNoLightDetected" 1 "TrailerLightOutputStat_OutputActiveDetectionOngoing" 0 "TrailerLightOutputStat_OutputInactive" ;
VAL_ 2147485018 FrontConspicLamp_stat_HiRight_IS 7 "LampCheck_stat_NotAvailable" 6 "LampCheck_stat_Error" 5 "LampCheck_stat_Spare_02" 4 "LampCheck_stat_Spare_01" 3 "LampCheck_stat_Spare" 2 "LampCheck_stat_TestedLampNOK" 1 "LampCheck_stat_TestedLampOK" 0 "LampCheck_stat_NotTested" ;
VAL_ 2147484194 FASSaturated_ISig_4 3 "FASSaturated_NotAvailable" 2 "FASSaturated_Error" 1 "FASSaturated_FAS_IsSaturated" 0 "FASSaturated_FAS_IsNotSaturated" ;
VAL_ 2147484194 OverSteerGuidanceStatus_ISig_4 3 "InactiveActive_NotAvailable" 2 "InactiveActive_Error" 1 "InactiveActive_Active" 0 "InactiveActive_Inactive" ;
VAL_ 2147484194 FASFullyOperational_ISig_4 3 "FASFullyOperational_NotAvailable" 2 "FASFullyOperational_Error" 1 "FASFullyOperational_FASFullyOperational" 0 "FASFullyOperational_FASNotFullyOperational" ;
VAL_ 2147484194 FASFunctionInControl_ISig_4 3 "FASFunctionInControl_NotAvailable" 2 "FASFunctionInControl_Error" 1 "FASFunctionInControl_FunctionInControl" 0 "FASFunctionInControl_DriverInControl" ;
VAL_ 2147485053 ActualFasPersSettingsButton_ISig 7 "FasPersSettingsButton_NotAvailable" 6 "FasPersSettingsButton_Error" 5 "FasPersSettingsButton_Spare" 4 "FasPersSettingsButton_UserDefinedButton" 3 "FasPersSettingsButton_PresetButtonHeavy" 2 "FasPersSettingsButton_PresetButtonFirm" 1 "FasPersSettingsButton_PresetButtonLight" 0 "FasPersSettingsButton_PresetButtonDefault" ;
VAL_ 2147485053 FasDriver_ISig_4 15 "FasDriver_NotAvailable" 14 "FasDriver_Error" 13 "FasDriver_Spare3" 12 "FasDriver_Spare2" 11 "FasDriver_Spare1" 10 "FasDriver_Driver10" 9 "FasDriver_Driver9" 8 "FasDriver_Driver8" 7 "FasDriver_Driver7" 6 "FasDriver_Driver6" 5 "FasDriver_Driver5" 4 "FasDriver_Driver4" 3 "FasDriver_Driver3" 2 "FasDriver_Driver2" 1 "FasDriver_Driver1" 0 "FasDriver_DefaultDriver" ;
VAL_ 2147484478 PS_PosLightDoorOpen 3 "InactiveActiveSpare_NotAvailable" 2 "InactiveActiveSpare_Spare" 1 "InactiveActiveSpare_Active" 0 "InactiveActiveSpare_Inactive" ;
VAL_ 2147484478 PS_FogLightRear 3 "InactiveActiveSpare_NotAvailable" 2 "InactiveActiveSpare_Spare" 1 "InactiveActiveSpare_Active" 0 "InactiveActiveSpare_Inactive" ;
VAL_ 2147484478 TrailerBodyLampDI_stat 3 "PushButtonStatus_NotAvailable" 2 "PushButtonStatus_Error" 1 "PushButtonStatus_Pushed" 0 "PushButtonStatus_Neutral" ;
VAL_ 2147484478 ParkedLoadDistribution_ISig_4 7 "ParkedLoadDistribution_NotAvailable" 6 "ParkedLoadDistribution_Error" 5 "ParkedLoadDistribution_Spare3" 4 "ParkedLoadDistribution_Spare2" 3 "ParkedLoadDistribution_Spare1" 2 "ParkedLoadDistribution_ActiveLevelNotReached" 1 "ParkedLoadDistribution_ActiveLevelReached" 0 "ParkedLoadDistribution_Inactive" ;
VAL_ 2147484478 TrailerBodyLampFdbk_stat 3 "OffOn_NotAvailable" 2 "OffOn_Error" 1 "OffOn_On" 0 "OffOn_Off" ;
VAL_ 2147484478 PS_FogLightFront 3 "InactiveActiveSpare_NotAvailable" 2 "InactiveActiveSpare_Spare" 1 "InactiveActiveSpare_Active" 0 "InactiveActiveSpare_Inactive" ;
VAL_ 2147484478 Alcolock_PBReleaseInhibit_ind 7 "PBReleaseInhibit_ind_NotAvailable" 6 "PBReleaseInhibit_ind_Error" 5 "PBReleaseInhibit_ind_Spare" 4 "PBReleaseInhibit_ind_AutoReleaseBeingInhibited" 3 "PBReleaseInhibit_ind_XPRReleaseCommandBeingInhibited" 2 "PBReleaseInhibit_ind_ManualReleaseCommandBeingInhibited" 1 "PBReleaseInhibit_ind_Active" 0 "PBReleaseInhibit_ind_NotActive" ;
VAL_ 2147484478 DHCNotificationReq 15 "DHCNotificationReq_NotAvailable" 14 "DHCNotificationReq_Error" 13 "DHCNotificationReq_Spare8" 12 "DHCNotificationReq_Spare7" 11 "DHCNotificationReq_Spare6" 10 "DHCNotificationReq_Spare5" 9 "DHCNotificationReq_Spare4" 8 "DHCNotificationReq_Spare3" 7 "DHCNotificationReq_Spare2" 6 "DHCNotificationReq_Spare1" 5 "DHCNotificationReq_ActivationFailedBrakePedalCheck" 4 "DHCNotificationReq_DeactivationWarning" 3 "DHCNotificationReq_ActivationstopFailedError" 2 "DHCNotificationReq_ActivationstopBraking" 1 "DHCNotificationReq_ActivationFailedLowSpeed" 0 "DHCNotificationReq_NoRequest" ;
VAL_ 2147484478 DriverCrank_rqst 3 "Request_NotAvailable" 2 "Request_Error" 1 "Request_RequestActive" 0 "Request_NotRequested" ;
VAL_ 2147484478 PS_HeadLightAdjustment 3 "InactiveActiveSpare_NotAvailable" 2 "InactiveActiveSpare_Spare" 1 "InactiveActiveSpare_Active" 0 "InactiveActiveSpare_Inactive" ;
VAL_ 2147484478 PS_MainBeam 3 "PSOffOn_NotAvailable" 2 "PSOffOn_Spare" 1 "PSOffOn_On" 0 "PSOffOn_Off" ;
VAL_ 2147484478 InstFuel_VehicleMoving 3 "VehicleMoving_NotAvailable" 2 "VehicleMoving_Error" 1 "VehicleMoving_VehicleMoving" 0 "VehicleMoving_VehicleStopped" ;
VAL_ 2147484478 PS_AFSAllowedInDriveP 3 "InactiveActiveSpare_NotAvailable" 2 "InactiveActiveSpare_Spare" 1 "InactiveActiveSpare_Active" 0 "InactiveActiveSpare_Inactive" ;
VAL_ 2147484478 PS_AFS 7 "PS_AFS_NotAvailable" 6 "PS_AFS_Spare3" 5 "PS_AFS_Spare2" 4 "PS_AFS_Spare1" 3 "PS_AFS_AFS_ActiveGlareFreeAllowed" 2 "PS_AFS_AFS_ActiveMainBeamAllowed" 1 "PS_AFS_AFS_ActiveMainBeamNotAllowed" 0 "PS_AFS_AFS_NotActive" ;
VAL_ 2147484478 AC2CoolingFanControl_rqst 3 "Request_NotAvailable" 2 "Request_Error" 1 "Request_RequestActive" 0 "Request_NotRequested" ;
VAL_ 2147484478 DHCStatus 3 "InactiveActive_NotAvailable" 2 "InactiveActive_Error" 1 "InactiveActive_Active" 0 "InactiveActive_Inactive" ;
VAL_ 2147484478 PS_PositionLight 3 "OffOnSpare_NotAvailable" 2 "OffOnSpare_Spare" 1 "OffOnSpare_On" 0 "OffOnSpare_Off" ;
SIG_GROUP_ 2147484946 VehCombHeaviestAxle_sg 1 : VehCombHeaviestAxle_Position VehCombHeaviestAxle_Load VehCombHeaviestAxle_VehicleID;
SIG_GROUP_ 2147484946 VehCombHeaviestBoogie_sg 1 : VehCombHeaviestBoogie_VehicleID VehCombHeaviestBoogie_Load VehCombHeaviestBoogie_Position;
SIG_GROUP_ 2147485038 TruckRearAxle2_sg 1 : TruckRearAxle2_Liftable TruckRearAxle2_Suspension TruckRearAxle2_Driven;
SIG_GROUP_ 2147485038 TruckRearAxle3_sg 1 : TruckRearAxle3_Liftable TruckRearAxle3_Driven TruckRearAxle3_Suspension;
SIG_GROUP_ 2147485038 TruckFrontAxle1_sg 1 : TruckFrontAxle1_Liftable TruckFrontAxle1_Suspension TruckFrontAxle1_Driven;
SIG_GROUP_ 2147485038 TruckRearAxle1_sg 1 : TruckRearAxle1_Driven TruckRearAxle1_Suspension TruckRearAxle1_Liftable;
SIG_GROUP_ 2147485038 TruckFrontAxle2_sg 1 : TruckFrontAxle2_Liftable TruckFrontAxle2_Driven TruckFrontAxle2_Suspension;
SIG_GROUP_ 2147485028 Trail4Type_sg_ISig_4 1 : Trail4Type_Towing_ISig_4 Trail4Type_TrailType_ISig_4;
SIG_GROUP_ 2147485028 Trail5Type_sg_ISig_4 1 : Trail5Type_TrailType_ISig_4 Trail5Type_Towing_ISig_4;
SIG_GROUP_ 2147485028 Trail3Type_sg_ISig_4 1 : Trail3Type_TrailType_ISig_4 Trail3Type_Towing_ISig_4;
SIG_GROUP_ 2147485026 Trail1Type_sg_ISig_4 1 : Trail1Type_Towing_ISig_4 Trail1Type_TrailType_ISig_4;
SIG_GROUP_ 2147485026 Trail2Type_sg_ISig_4 1 : Trail2Type_Towing_ISig_4 Trail2Type_TrailType_ISig_4;
SIG_GROUP_ 2147485018 FrontConspicLamp_stat_sg_ISig_4 1 : FrontConspicLamp_stat_HiLeft_ISi FrontConspicLamp_stat_LoRight_IS FrontConspicLamp_stat_LoLeft_ISi FrontConspicLamp_stat_HiRight_IS;
SIG_GROUP_ 2147484478 InstFuel_sg 1 : InstFuel_ConsumpValue InstFuel_VehicleMoving;
